VERSION "created by canmatrix"

NS_ :

BS_:

BU_:

BO_ 2633936894 GFC: 8 Vector__XXX
 SG_ TotalFuelUsed : 32|32@1+ (0.5,0) [0|2105540607.5] "kg" Vector__XXX
 SG_ TripFuel : 0|32@1+ (0.5,0) [0|2105540607.5] "kg" Vector__XXX

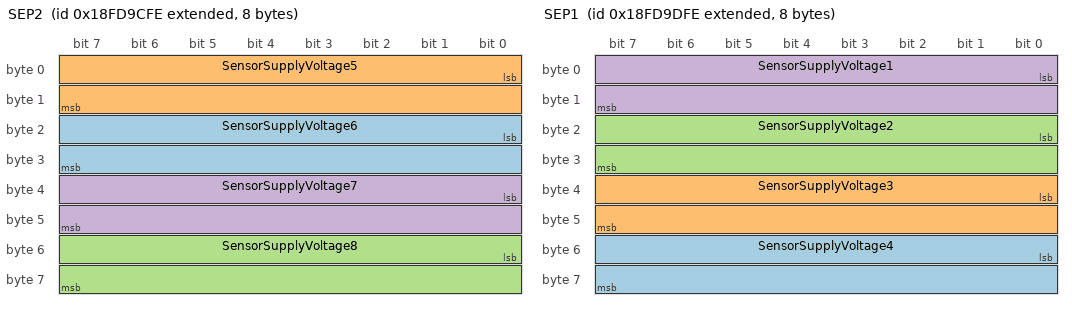
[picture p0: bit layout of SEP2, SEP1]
BO_ 2566757630 SEP2: 8 Vector__XXX
 SG_ SensorSupplyVoltage6 : 16|16@1+ (0.05,0) [0|3212.75] "V" Vector__XXX
 SG_ SensorSupplyVoltage5 : 0|16@1+ (0.05,0) [0|3212.75] "V" Vector__XXX
 SG_ SensorSupplyVoltage8 : 48|16@1+ (0.05,0) [0|3212.75] "V" Vector__XXX
 SG_ SensorSupplyVoltage7 : 32|16@1+ (0.05,0) [0|3212.75] "V" Vector__XXX

BO_ 2566757886 SEP1: 8 Vector__XXX
 SG_ SensorSupplyVoltage4 : 48|16@1+ (0.05,0) [0|3212.75] "V" Vector__XXX
 SG_ SensorSupplyVoltage3 : 32|16@1+ (0.05,0) [0|3212.75] "V" Vector__XXX
 SG_ SensorSupplyVoltage2 : 16|16@1+ (0.05,0) [0|3212.75] "V" Vector__XXX
 SG_ SensorSupplyVoltage1 : 0|16@1+ (0.05,0) [0|3212.75] "V" Vector__XXX

BO_ 2566759678 PTODE: 8 Vector__XXX
 SG_ EnggmntSttusTransInputShaftPTO1 : 38|2@1+ (1,0) [0|3] "" Vector__XXX
 SG_ EnggmntSttusTransInputShaftPTO2 : 36|2@1+ (1,0) [0|3] "" Vector__XXX
 SG_ EnggmntSttusTransOutputShaftPTO : 34|2@1+ (1,0) [0|3] "" Vector__XXX
 SG_ EnggmntSttsTrnsfrCsOtptShaftPTO : 32|2@1+ (1,0) [0|3] "" Vector__XXX
 SG_ EnggmntCnsntTransInputShaftPTO1 : 22|2@1+ (1,0) [0|3] "" Vector__XXX
 SG_ EnggmntCnsntTransInputShaftPTO2 : 20|2@1+ (1,0) [0|3] "" Vector__XXX
 SG_ EnggmntCnsntTransOutputShaftPTO : 18|2@1+ (1,0) [0|3] "" Vector__XXX
 SG_ EnggmntCnsntTrnsfrCsOtptShftPTO : 16|2@1+ (1,0) [0|3] "" Vector__XXX
 SG_ EnableSwitchTransInputShaftPTO1 : 6|2@1+ (1,0) [0|3] "" Vector__XXX
 SG_ EnableSwitchTransInputShaftPTO2 : 4|2@1+ (1,0) [0|3] "" Vector__XXX
 SG_ EnableSwitchTransOutputShaftPTO : 2|2@1+ (1,0) [0|3] "" Vector__XXX
 SG_ EnblSwtchTrnsfrCsOutputShaftPTO : 0|2@1+ (1,0) [0|3] "" Vector__XXX
 SG_ EnggmntSttsPTOEngAccssoryDrive2 : 44|2@1+ (1,0) [0|3] "" Vector__XXX
 SG_ EnggmntSttsPTOEngAccssoryDrive1 : 42|2@1+ (1,0) [0|3] "" Vector__XXX
 SG_ EnggmntCnsntPTOEngAccssryDrive2 : 28|2@1+ (1,0) [0|3] "" Vector__XXX
 SG_ EnggmntCnsntPTOEngAccssryDrive1 : 26|2@1+ (1,0) [0|3] "" Vector__XXX
 SG_ EngagementStatusPTOEngFlywheel : 40|2@1+ (1,0) [0|3] "" Vector__XXX
 SG_ EngagementConsentPTOEngFlywheel : 24|2@1+ (1,0) [0|3] "" Vector__XXX
 SG_ EnblSwitchPTOEngAccessoryDrive2 : 12|2@1+ (1,0) [0|3] "" Vector__XXX
 SG_ EnblSwitchPTOEngAccessoryDrive1 : 10|2@1+ (1,0) [0|3] "" Vector__XXX
 SG_ EnableSwitchPTOEngFlywheel : 8|2@1+ (1,0) [0|3] "" Vector__XXX
 SG_ AtLeastOnePTOEngaged : 48|2@1+ (1,0) [0|3] "" Vector__XXX

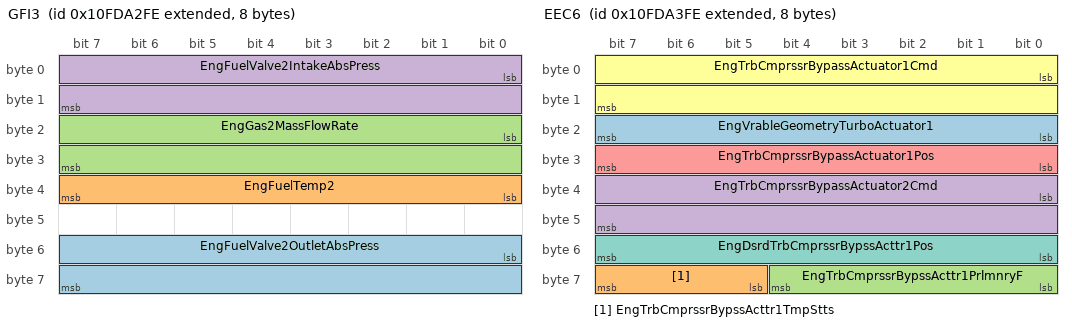
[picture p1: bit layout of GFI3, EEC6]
BO_ 2432541438 GFI3: 8 Vector__XXX
 SG_ EngFuelValve2OutletAbsPress : 48|16@1+ (0.1,0) [0|6425.5] "kPa" Vector__XXX
 SG_ EngFuelTemp2 : 32|8@1+ (1,-40) [-40|210] "deg C" Vector__XXX
 SG_ EngGas2MassFlowRate : 16|16@1+ (0.05,0) [0|3212.75] "kg/h" Vector__XXX
 SG_ EngFuelValve2IntakeAbsPress : 0|16@1+ (0.1,0) [0|6425.5] "kPa" Vector__XXX

BO_ 2432541694 EEC6: 8 Vector__XXX
 SG_ EngVrableGeometryTurboActuator1 : 16|8@1+ (0.4,0) [0|100] "%" Vector__XXX
 SG_ EngTrbCmprssrBypssActtr1TmpStts : 61|3@1+ (1,0) [0|7] "" Vector__XXX
 SG_ EngTrbCmprssrBypssActtr1PrlmnryF : 56|5@1+ (1,0) [0|31] "" Vector__XXX
 SG_ EngTrbCmprssrBypassActuator2Cmd : 32|16@1+ (0.0025,0) [0|160.6375] "%" Vector__XXX
 SG_ EngTrbCmprssrBypassActuator1Pos : 24|8@1+ (0.4,0) [0|100] "%" Vector__XXX
 SG_ EngTrbCmprssrBypassActuator1Cmd : 0|16@1+ (0.0025,0) [0|160.6375] "%" Vector__XXX
 SG_ EngDsrdTrbCmprssrBypssActtr1Pos : 48|8@1+ (0.4,0) [0|100] "%" Vector__XXX

BO_ 2566759934 DC2: 8 Vector__XXX
 SG_ EnableStatusOfDoor10 : 58|2@1+ (1,0) [0|3] "" Vector__XXX
 SG_ OpenStatusOfDoor10 : 56|2@1+ (1,0) [0|3] "" Vector__XXX
 SG_ LockStatusOfDoor10 : 54|2@1+ (1,0) [0|3] "" Vector__XXX
 SG_ EnableStatusOfDoor9 : 52|2@1+ (1,0) [0|3] "" Vector__XXX
 SG_ OpenStatusOfDoor9 : 50|2@1+ (1,0) [0|3] "" Vector__XXX
 SG_ LockStatusOfDoor9 : 48|2@1+ (1,0) [0|3] "" Vector__XXX
 SG_ EnableStatusOfDoor8 : 46|2@1+ (1,0) [0|3] "" Vector__XXX
 SG_ OpenStatusOfDoor8 : 44|2@1+ (1,0) [0|3] "" Vector__XXX
 SG_ LockStatusOfDoor8 : 42|2@1+ (1,0) [0|3] "" Vector__XXX
 SG_ EnableStatusOfDoor7 : 40|2@1+ (1,0) [0|3] "" Vector__XXX
 SG_ OpenStatusOfDoor7 : 38|2@1+ (1,0) [0|3] "" Vector__XXX
 SG_ LockStatusOfDoor7 : 36|2@1+ (1,0) [0|3] "" Vector__XXX
 SG_ EnableStatusOfDoor6 : 34|2@1+ (1,0) [0|3] "" Vector__XXX
 SG_ OpenStatusOfDoor6 : 32|2@1+ (1,0) [0|3] "" Vector__XXX
 SG_ LockStatusOfDoor6 : 30|2@1+ (1,0) [0|3] "" Vector__XXX
 SG_ EnableStatusOfDoor5 : 28|2@1+ (1,0) [0|3] "" Vector__XXX
 SG_ OpenStatusOfDoor5 : 26|2@1+ (1,0) [0|3] "" Vector__XXX
 SG_ LockStatusOfDoor5 : 24|2@1+ (1,0) [0|3] "" Vector__XXX
 SG_ EnableStatusOfDoor4 : 22|2@1+ (1,0) [0|3] "" Vector__XXX
 SG_ OpenStatusOfDoor4 : 20|2@1+ (1,0) [0|3] "" Vector__XXX
 SG_ LockStatusOfDoor4 : 18|2@1+ (1,0) [0|3] "" Vector__XXX
 SG_ EnableStatusOfDoor3 : 16|2@1+ (1,0) [0|3] "" Vector__XXX
 SG_ OpenStatusOfDoor3 : 14|2@1+ (1,0) [0|3] "" Vector__XXX
 SG_ LockStatusOfDoor3 : 12|2@1+ (1,0) [0|3] "" Vector__XXX
 SG_ EnableStatusOfDoor2 : 10|2@1+ (1,0) [0|3] "" Vector__XXX
 SG_ OpenStatusOfDoor2 : 8|2@1+ (1,0) [0|3] "" Vector__XXX
 SG_ LockStatusOfDoor2 : 6|2@1+ (1,0) [0|3] "" Vector__XXX
 SG_ EnableStatusOfDoor1 : 4|2@1+ (1,0) [0|3] "" Vector__XXX
 SG_ OpenStatusOfDoor1 : 2|2@1+ (1,0) [0|3] "" Vector__XXX
 SG_ LockStatusOfDoor1 : 0|2@1+ (1,0) [0|3] "" Vector__XXX

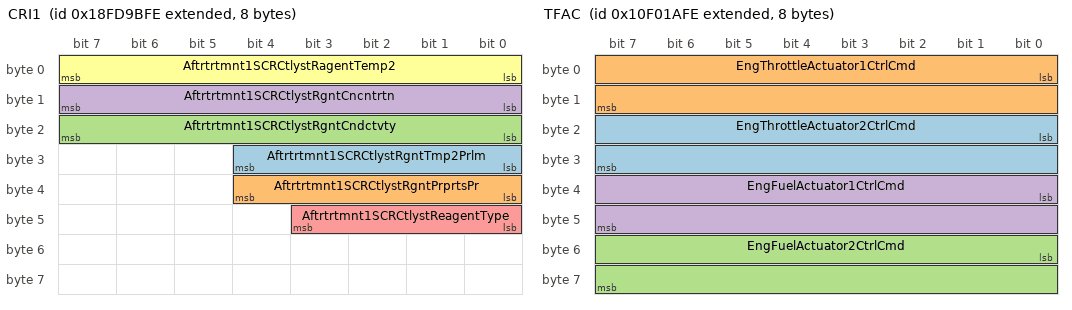
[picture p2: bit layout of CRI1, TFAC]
BO_ 2566757374 CRI1: 8 Vector__XXX
 SG_ Aftrtrtmnt1SCRCtlystRgntTmp2Prlm : 24|5@1+ (1,0) [0|31] "" Vector__XXX
 SG_ Aftrtrtmnt1SCRCtlystRgntPrprtsPr : 32|5@1+ (1,0) [0|31] "" Vector__XXX
 SG_ Aftrtrtmnt1SCRCtlystRgntCndctvty : 16|8@1+ (5,0) [0|1250] "microSiemens/mm" Vector__XXX
 SG_ Aftrtrtmnt1SCRCtlystRgntCncntrtn : 8|8@1+ (0.25,0) [0|62.5] "%" Vector__XXX
 SG_ Aftrtrtmnt1SCRCtlystReagentType : 40|4@1+ (1,0) [0|15] "" Vector__XXX
 SG_ Aftrtrtmnt1SCRCtlystRagentTemp2 : 0|8@1+ (1,-40) [-40|210] "deg C" Vector__XXX

BO_ 2431654654 TFAC: 8 Vector__XXX
 SG_ EngThrottleActuator2CtrlCmd : 16|16@1+ (0.0025,0) [0|160.6375] "%" Vector__XXX
 SG_ EngThrottleActuator1CtrlCmd : 0|16@1+ (0.0025,0) [0|160.6375] "%" Vector__XXX
 SG_ EngFuelActuator2CtrlCmd : 48|16@1+ (0.0025,0) [0|160.6375] "%" Vector__XXX
 SG_ EngFuelActuator1CtrlCmd : 32|16@1+ (0.0025,0) [0|160.6375] "%" Vector__XXX

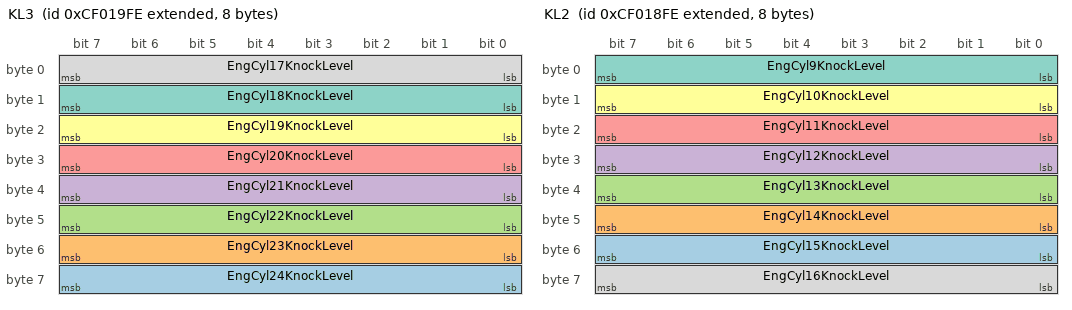
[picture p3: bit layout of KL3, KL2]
BO_ 2364545534 KL3: 8 Vector__XXX
 SG_ EngCyl24KnockLevel : 56|8@1+ (1,0) [0|250] "%" Vector__XXX
 SG_ EngCyl23KnockLevel : 48|8@1+ (1,0) [0|250] "%" Vector__XXX
 SG_ EngCyl22KnockLevel : 40|8@1+ (1,0) [0|250] "%" Vector__XXX
 SG_ EngCyl21KnockLevel : 32|8@1+ (1,0) [0|250] "%" Vector__XXX
 SG_ EngCyl20KnockLevel : 24|8@1+ (1,0) [0|250] "%" Vector__XXX
 SG_ EngCyl19KnockLevel : 16|8@1+ (1,0) [0|250] "%" Vector__XXX
 SG_ EngCyl18KnockLevel : 8|8@1+ (1,0) [0|250] "%" Vector__XXX
 SG_ EngCyl17KnockLevel : 0|8@1+ (1,0) [0|250] "%" Vector__XXX

BO_ 2364545278 KL2: 8 Vector__XXX
 SG_ EngCyl15KnockLevel : 48|8@1+ (1,0) [0|250] "%" Vector__XXX
 SG_ EngCyl14KnockLevel : 40|8@1+ (1,0) [0|250] "%" Vector__XXX
 SG_ EngCyl13KnockLevel : 32|8@1+ (1,0) [0|250] "%" Vector__XXX
 SG_ EngCyl12KnockLevel : 24|8@1+ (1,0) [0|250] "%" Vector__XXX
 SG_ EngCyl11KnockLevel : 16|8@1+ (1,0) [0|250] "%" Vector__XXX
 SG_ EngCyl10KnockLevel : 8|8@1+ (1,0) [0|250] "%" Vector__XXX
 SG_ EngCyl9KnockLevel : 0|8@1+ (1,0) [0|250] "%" Vector__XXX
 SG_ EngCyl16KnockLevel : 56|8@1+ (1,0) [0|250] "%" Vector__XXX

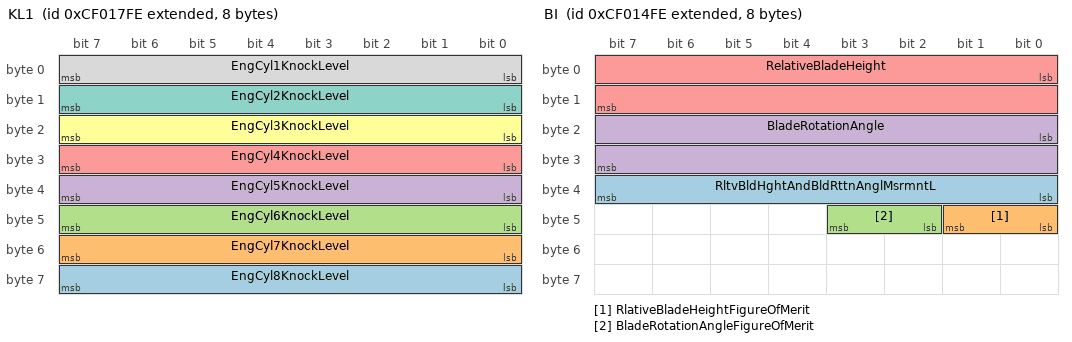
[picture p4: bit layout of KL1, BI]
BO_ 2364545022 KL1: 8 Vector__XXX
 SG_ EngCyl8KnockLevel : 56|8@1+ (1,0) [0|250] "%" Vector__XXX
 SG_ EngCyl7KnockLevel : 48|8@1+ (1,0) [0|250] "%" Vector__XXX
 SG_ EngCyl6KnockLevel : 40|8@1+ (1,0) [0|250] "%" Vector__XXX
 SG_ EngCyl5KnockLevel : 32|8@1+ (1,0) [0|250] "%" Vector__XXX
 SG_ EngCyl4KnockLevel : 24|8@1+ (1,0) [0|250] "%" Vector__XXX
 SG_ EngCyl3KnockLevel : 16|8@1+ (1,0) [0|250] "%" Vector__XXX
 SG_ EngCyl2KnockLevel : 8|8@1+ (1,0) [0|250] "%" Vector__XXX
 SG_ EngCyl1KnockLevel : 0|8@1+ (1,0) [0|250] "%" Vector__XXX

BO_ 2364544766 CCS: 8 Vector__XXX
 SG_ EngCyl9CombustionStatus : 16|2@1+ (1,0) [0|3] "" Vector__XXX
 SG_ EngCyl8CombustionStatus : 14|2@1+ (1,0) [0|3] "" Vector__XXX
 SG_ EngCyl7CombustionStatus : 12|2@1+ (1,0) [0|3] "" Vector__XXX
 SG_ EngCyl6CombustionStatus : 10|2@1+ (1,0) [0|3] "" Vector__XXX
 SG_ EngCyl5CombustionStatus : 8|2@1+ (1,0) [0|3] "" Vector__XXX
 SG_ EngCyl4CombustionStatus : 6|2@1+ (1,0) [0|3] "" Vector__XXX
 SG_ EngCyl3CombustionStatus : 4|2@1+ (1,0) [0|3] "" Vector__XXX
 SG_ EngCyl2CombustionStatus : 2|2@1+ (1,0) [0|3] "" Vector__XXX
 SG_ EngCyl24CombustionStatus : 46|2@1+ (1,0) [0|3] "" Vector__XXX
 SG_ EngCyl23CombustionStatus : 44|2@1+ (1,0) [0|3] "" Vector__XXX
 SG_ EngCyl22CombustionStatus : 42|2@1+ (1,0) [0|3] "" Vector__XXX
 SG_ EngCyl21CombustionStatus : 40|2@1+ (1,0) [0|3] "" Vector__XXX
 SG_ EngCyl20CombustionStatus : 38|2@1+ (1,0) [0|3] "" Vector__XXX
 SG_ EngCyl1CombustionStatus : 0|2@1+ (1,0) [0|3] "" Vector__XXX
 SG_ EngCyl19CombustionStatus : 36|2@1+ (1,0) [0|3] "" Vector__XXX
 SG_ EngCyl18CombustionStatus : 34|2@1+ (1,0) [0|3] "" Vector__XXX
 SG_ EngCyl17CombustionStatus : 32|2@1+ (1,0) [0|3] "" Vector__XXX
 SG_ EngCyl16CombustionStatus : 30|2@1+ (1,0) [0|3] "" Vector__XXX
 SG_ EngCyl15CombustionStatus : 28|2@1+ (1,0) [0|3] "" Vector__XXX
 SG_ EngCyl14CombustionStatus : 26|2@1+ (1,0) [0|3] "" Vector__XXX
 SG_ EngCyl13CombustionStatus : 24|2@1+ (1,0) [0|3] "" Vector__XXX
 SG_ EngCyl12CombustionStatus : 22|2@1+ (1,0) [0|3] "" Vector__XXX
 SG_ EngCyl11CombustionStatus : 20|2@1+ (1,0) [0|3] "" Vector__XXX
 SG_ EngCyl10CombustionStatus : 18|2@1+ (1,0) [0|3] "" Vector__XXX

BO_ 2364544254 BI: 8 Vector__XXX
 SG_ RltvBldHghtAndBldRttnAnglMsrmntL : 32|8@1+ (0.5,0) [0|125] "ms" Vector__XXX
 SG_ RlativeBladeHeightFigureOfMerit : 40|2@1+ (1,0) [0|3] "" Vector__XXX
 SG_ BladeRotationAngleFigureOfMerit : 42|2@1+ (1,0) [0|3] "" Vector__XXX
 SG_ BladeRotationAngle : 16|16@1+ (0.0078125,-200) [-200|301.99] "deg" Vector__XXX
 SG_ RelativeBladeHeight : 0|16@1+ (0.1,-3200) [-3200|3225.5] "mm" Vector__XXX

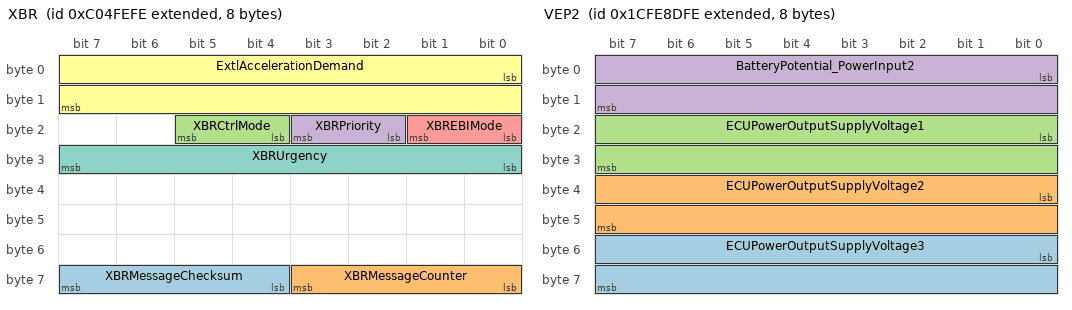
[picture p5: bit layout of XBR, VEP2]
BO_ 2349137662 XBR: 8 Vector__XXX
 SG_ XBRMessageChecksum : 60|4@1+ (1,0) [0|15] "" Vector__XXX
 SG_ XBRMessageCounter : 56|4@1+ (1,0) [0|15] "" Vector__XXX
 SG_ XBRCtrlMode : 20|2@1+ (1,0) [0|3] "" Vector__XXX
 SG_ XBRPriority : 18|2@1+ (1,0) [0|3] "" Vector__XXX
 SG_ XBREBIMode : 16|2@1+ (1,0) [0|3] "" Vector__XXX
 SG_ ExtlAccelerationDemand : 0|16@1+ (0.00048828125,-15.687) [-15.687|15.687] "m/s/s" Vector__XXX
 SG_ XBRUrgency : 24|8@1+ (0.4,0) [0|100] "%" Vector__XXX

BO_ 2566848510 WFI: 8 Vector__XXX
 SG_ WaterInFuelIndicator : 0|2@1+ (1,0) [0|3] "" Vector__XXX

BO_ 2566843134 VW: 8 Vector__XXX
 SG_ AxleLocation M : 0|8@1+ (1,0) [0|255] "" Vector__XXX
 SG_ CargoWeight_30 m48 : 40|16@1+ (2,0) [0|128510] "kg" Vector__XXX
 SG_ CargoWeight_20 m32 : 40|16@1+ (2,0) [0|128510] "kg" Vector__XXX
 SG_ CargoWeight_10 m16 : 40|16@1+ (2,0) [0|128510] "kg" Vector__XXX
 SG_ CargoWeight_00 m0 : 40|16@1+ (2,0) [0|128510] "kg" Vector__XXX
 SG_ TrailerWeight_30 m48 : 24|16@1+ (2,0) [0|128510] "kg" Vector__XXX
 SG_ TrailerWeight_20 m32 : 24|16@1+ (2,0) [0|128510] "kg" Vector__XXX
 SG_ TrailerWeight_10 m16 : 24|16@1+ (2,0) [0|128510] "kg" Vector__XXX
 SG_ TrailerWeight_00 m0 : 24|16@1+ (2,0) [0|128510] "kg" Vector__XXX
 SG_ AxleWeight_30 m48 : 8|16@1+ (0.5,0) [0|32127.5] "kg" Vector__XXX
 SG_ AxleWeight_20 m32 : 8|16@1+ (0.5,0) [0|32127.5] "kg" Vector__XXX
 SG_ AxleWeight_10 m16 : 8|16@1+ (0.5,0) [0|32127.5] "kg" Vector__XXX
 SG_ AxleWeight_00 m0 : 8|16@1+ (0.5,0) [0|32127.5] "kg" Vector__XXX

BO_ 2566804222 VEP3: 8 Vector__XXX
 SG_ NetBatteryCurrentHiRes : 16|16@1+ (0.05,-1600) [-1600|1612.75] "A" Vector__XXX
 SG_ AltCurrentHiRes : 0|16@1+ (0.05,-1600) [-1600|1676.75] "A" Vector__XXX

BO_ 2633928190 VEP2: 8 Vector__XXX
 SG_ ECUPowerOutputSupplyVoltage3 : 48|16@1+ (0.05,0) [0|3212.75] "V" Vector__XXX
 SG_ ECUPowerOutputSupplyVoltage2 : 32|16@1+ (0.05,0) [0|3212.75] "V" Vector__XXX
 SG_ ECUPowerOutputSupplyVoltage1 : 16|16@1+ (0.05,0) [0|3212.75] "V" Vector__XXX
 SG_ BatteryPotential_PowerInput2 : 0|16@1+ (0.05,0) [0|3212.75] "V" Vector__XXX

BO_ 2566845438 VP: 8 Vector__XXX
 SG_ Longitude : 32|32@1+ (10,-210) [-210|211.1008122] "deg" Vector__XXX
 SG_ Latitude : 0|32@1+ (10,-210) [-210|211.1008122] "deg" Vector__XXX

BO_ 2566843646 VI: 8 Vector__XXX
 SG_ VehicleIdentificationNumber : 0|8@1+ (1,0) [0|255] "" Vector__XXX

BO_ 2566842366 VH: 8 Vector__XXX
 SG_ TotalPowerTakeoffHours : 32|32@1+ (0.05,0) [0|210554060.75] "hr" Vector__XXX
 SG_ TotalVehicleHours : 0|32@1+ (0.05,0) [0|210554060.75] "hr" Vector__XXX

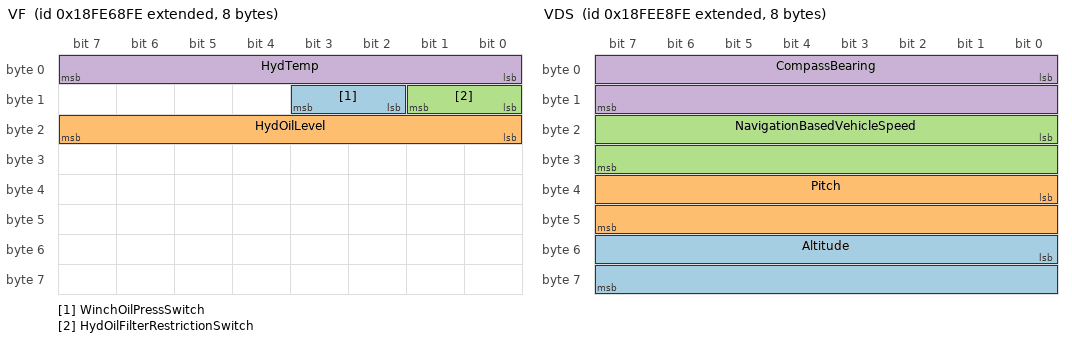
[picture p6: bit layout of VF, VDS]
BO_ 2566809854 VF: 8 Vector__XXX
 SG_ WinchOilPressSwitch : 10|2@1+ (1,0) [0|3] "" Vector__XXX
 SG_ HydOilLevel : 16|8@1+ (0.4,0) [0|100] "%" Vector__XXX
 SG_ HydOilFilterRestrictionSwitch : 8|2@1+ (1,0) [0|3] "" Vector__XXX
 SG_ HydTemp : 0|8@1+ (1,-40) [-40|210] "deg C" Vector__XXX

BO_ 2566842622 VDS: 8 Vector__XXX
 SG_ Altitude : 48|16@1+ (0.125,-2500) [-2500|5531.875] "m" Vector__XXX
 SG_ Pitch : 32|16@1+ (0.0078125,-200) [-200|301.99] "deg" Vector__XXX
 SG_ NavigationBasedVehicleSpeed : 16|16@1+ (0.00390625,0) [0|250.996] "km/h" Vector__XXX
 SG_ CompassBearing : 0|16@1+ (0.0078125,0) [0|501.99] "deg" Vector__XXX

BO_ 2566832638 VDHR: 8 Vector__XXX
 SG_ HighResolutionTripDistance : 32|32@1+ (5,0) [0|21055406] "km" Vector__XXX
 SG_ HghRslutionTotalVehicleDistance : 0|32@1+ (5,0) [0|21055406] "km" Vector__XXX

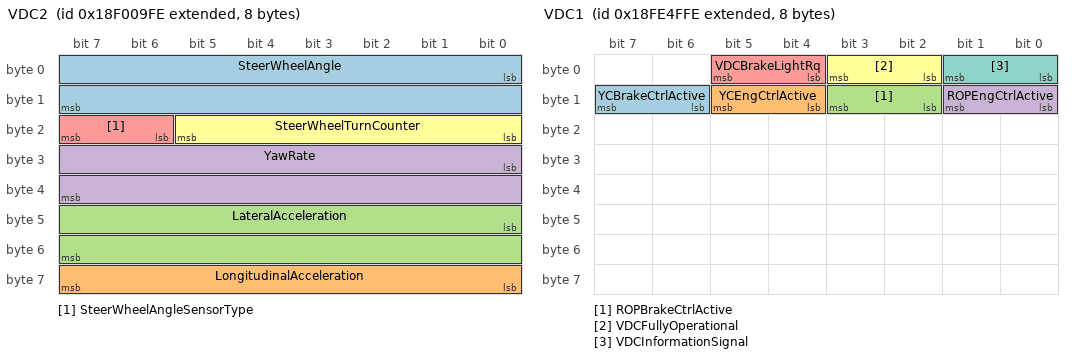
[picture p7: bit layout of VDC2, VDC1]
BO_ 2565868030 VDC2: 8 Vector__XXX
 SG_ SteerWheelAngle : 0|16@1+ (0.0009765625,-31.374) [-31.374|31.374] "rad" Vector__XXX
 SG_ LongitudinalAcceleration : 56|8@1+ (0.1,-12.5) [-12.5|12.5] "m/s/s" Vector__XXX
 SG_ LateralAcceleration : 40|16@1+ (0.00048828125,-15.687) [-15.687|15.687] "m/s/s" Vector__XXX
 SG_ YawRate : 24|16@1+ (0.0001220703125,-3.92) [-3.92|3.92] "rad/s" Vector__XXX
 SG_ SteerWheelAngleSensorType : 22|2@1+ (1,0) [0|3] "" Vector__XXX
 SG_ SteerWheelTurnCounter : 16|6@1+ (1,-32) [-32|29] "turns" Vector__XXX

BO_ 2566803454 VDC1: 8 Vector__XXX
 SG_ YCBrakeCtrlActive : 14|2@1+ (1,0) [0|3] "" Vector__XXX
 SG_ YCEngCtrlActive : 12|2@1+ (1,0) [0|3] "" Vector__XXX
 SG_ ROPBrakeCtrlActive : 10|2@1+ (1,0) [0|3] "" Vector__XXX
 SG_ ROPEngCtrlActive : 8|2@1+ (1,0) [0|3] "" Vector__XXX
 SG_ VDCBrakeLightRq : 4|2@1+ (1,0) [0|3] "" Vector__XXX
 SG_ VDCFullyOperational : 2|2@1+ (1,0) [0|3] "" Vector__XXX
 SG_ VDCInformationSignal : 0|2@1+ (1,0) [0|3] "" Vector__XXX

BO_ 2566840574 VD: 8 Vector__XXX
 SG_ TotalVehicleDistance : 32|32@1+ (0.125,0) [0|526385151.9] "km" Vector__XXX
 SG_ TripDistance : 0|32@1+ (0.125,0) [0|526385151.9] "km" Vector__XXX

BO_ 2633938686 TVI: 8 Vector__XXX
 SG_ TripCruiseDistance : 16|32@1+ (0.125,0) [0|526385151.9] "km" Vector__XXX
 SG_ TripMaxVehicleSpeed : 0|16@1+ (0.00390625,0) [0|250.996] "km/h" Vector__XXX

BO_ 2633937150 TTI2: 20 Vector__XXX
 SG_ TripAirCompressorOnTime : 128|32@1+ (0.05,0) [0|210554060.75] "hr" Vector__XXX
 SG_ TripIdleTime : 96|32@1+ (0.05,0) [0|210554060.75] "hr" Vector__XXX
 SG_ TripEngRunningTime : 64|32@1+ (0.05,0) [0|210554060.75] "hr" Vector__XXX
 SG_ TripCruiseTime : 0|32@1+ (0.05,0) [0|210554060.75] "hr" Vector__XXX
 SG_ TripPTOGovernorTime : 32|32@1+ (0.05,0) [0|210554060.75] "hr" Vector__XXX

BO_ 2633938174 TTI1: 16 Vector__XXX
 SG_ TripTimeInDerateByEng : 96|32@1+ (0.05,0) [0|210554060.75] "hr" Vector__XXX
 SG_ TripTimeInGearDown : 64|32@1+ (0.05,0) [0|210554060.75] "hr" Vector__XXX
 SG_ TripTimeInTopGear : 32|32@1+ (0.05,0) [0|210554060.75] "hr" Vector__XXX
 SG_ TripTimeInVSL : 0|32@1+ (0.05,0) [0|210554060.75] "hr" Vector__XXX

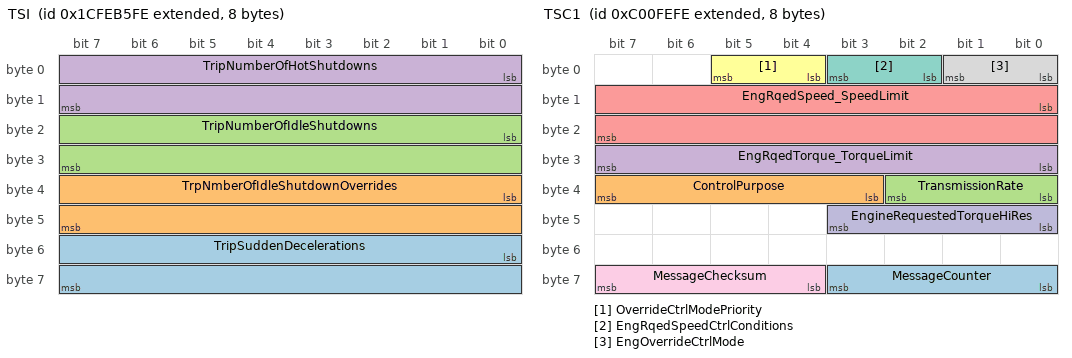
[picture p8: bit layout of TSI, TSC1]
BO_ 2633938430 TSI: 8 Vector__XXX
 SG_ TripSuddenDecelerations : 48|16@1+ (1,0) [0|64255] "counts" Vector__XXX
 SG_ TrpNmberOfIdleShutdownOverrides : 32|16@1+ (1,0) [0|64255] "counts" Vector__XXX
 SG_ TripNumberOfIdleShutdowns : 16|16@1+ (1,0) [0|64255] "counts" Vector__XXX
 SG_ TripNumberOfHotShutdowns : 0|16@1+ (1,0) [0|64255] "counts" Vector__XXX

BO_ 2348875518 TSC1: 8 Vector__XXX
 SG_ MessageCounter : 56|4@1+ (1,0) [0|15] "" Vector__XXX
 SG_ ControlPurpose : 35|5@1+ (1,0) [0|31] "" Vector__XXX
 SG_ TransmissionRate : 32|3@1+ (1,0) [0|7] "" Vector__XXX
 SG_ EngRqedTorque_TorqueLimit : 24|8@1+ (1,-125) [-125|125] "%" Vector__XXX
 SG_ EngRqedSpeed_SpeedLimit : 8|16@1+ (0.125,0) [0|8031.875] "rpm" Vector__XXX
 SG_ OverrideCtrlModePriority : 4|2@1+ (1,0) [0|3] "" Vector__XXX
 SG_ EngRqedSpeedCtrlConditions : 2|2@1+ (1,0) [0|3] "" Vector__XXX
 SG_ EngOverrideCtrlMode : 0|2@1+ (1,0) [0|3] "" Vector__XXX
 SG_ MessageChecksum : 60|4@1+ (1,0) [0|15] "" Vector__XXX
 SG_ EngineRequestedTorqueHiRes : 40|4@1+ (0.125,0) [0|0.875] "%" Vector__XXX

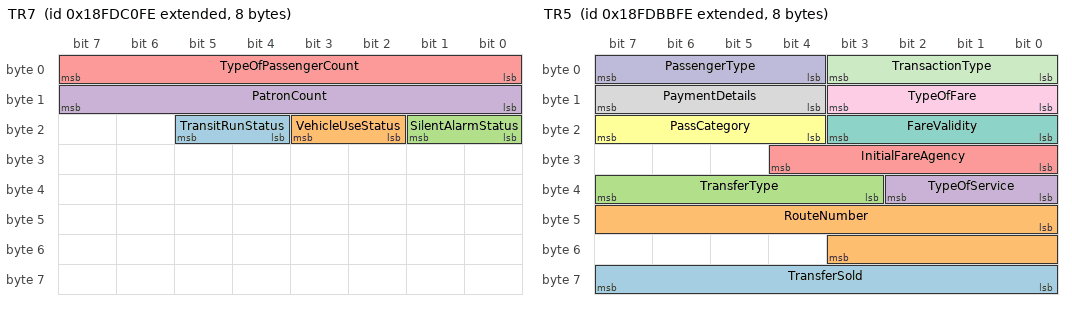
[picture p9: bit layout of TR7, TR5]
BO_ 2566766846 TR7: 8 Vector__XXX
 SG_ TransitRunStatus : 20|2@1+ (1,0) [0|3] "" Vector__XXX
 SG_ VehicleUseStatus : 18|2@1+ (1,0) [0|3] "" Vector__XXX
 SG_ SilentAlarmStatus : 16|2@1+ (1,0) [0|3] "" Vector__XXX
 SG_ PatronCount : 8|8@1+ (1,0) [0|250] "" Vector__XXX
 SG_ TypeOfPassengerCount : 0|8@1+ (1,0) [0|255] "" Vector__XXX

BO_ 2566765310 TR6: 8 Vector__XXX
 SG_ FareboxAlarmIdentifier : 8|7@1+ (1,0) [0|127] "" Vector__XXX
 SG_ FareboxEmergencyStatus : 0|2@1+ (1,0) [0|3] "" Vector__XXX

BO_ 2566765566 TR5: 8 Vector__XXX
 SG_ TransferSold : 56|8@1+ (1,0) [0|255] "" Vector__XXX
 SG_ RouteNumber : 40|12@1+ (1,0) [0|4095] "" Vector__XXX
 SG_ TransferType : 35|5@1+ (1,0) [0|31] "" Vector__XXX
 SG_ TypeOfService : 32|3@1+ (1,0) [0|7] "" Vector__XXX
 SG_ InitialFareAgency : 24|5@1+ (1,0) [0|31] "" Vector__XXX
 SG_ PassCategory : 20|4@1+ (1,0) [0|15] "" Vector__XXX
 SG_ FareValidity : 16|4@1+ (1,0) [0|15] "" Vector__XXX
 SG_ PaymentDetails : 12|4@1+ (1,0) [0|15] "" Vector__XXX
 SG_ TypeOfFare : 8|4@1+ (1,0) [0|15] "" Vector__XXX
 SG_ PassengerType : 4|4@1+ (1,0) [0|15] "" Vector__XXX
 SG_ TransactionType : 0|4@1+ (1,0) [0|15] "" Vector__XXX

BO_ 2566765822 TR4: 15 Vector__XXX
 SG_ DriversFareboxSecurityCode : 104|16@1+ (1,0) [0|65535] "counts" Vector__XXX
 SG_ AssignedBlock : 88|16@1+ (1,0) [0|65535] "counts" Vector__XXX
 SG_ AssignedRun : 72|16@1+ (1,0) [0|65535] "counts" Vector__XXX
 SG_ AssignedRoute : 56|16@1+ (1,0) [0|65535] "counts" Vector__XXX
 SG_ PatternNumber : 40|16@1+ (1,0) [0|65535] "counts" Vector__XXX
 SG_ TripNumber : 24|16@1+ (1,0) [0|65535] "counts" Vector__XXX
 SG_ FarePresets : 16|8@1+ (1,0) [0|255] "" Vector__XXX
 SG_ TripDirection : 8|4@1+ (1,0) [0|15] "" Vector__XXX
 SG_ TripStatus : 2|3@1+ (1,0) [0|7] "" Vector__XXX
 SG_ FareboxServiceStatus : 0|2@1+ (1,0) [0|3] "" Vector__XXX

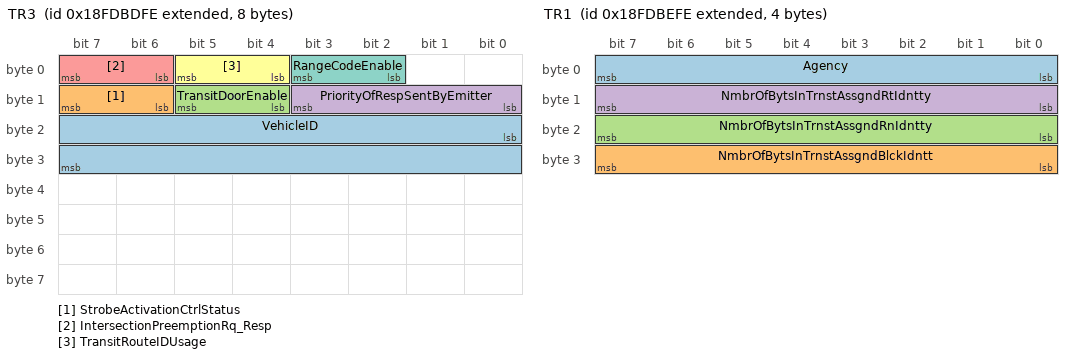
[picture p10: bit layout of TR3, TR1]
BO_ 2566766078 TR3: 8 Vector__XXX
 SG_ VehicleID : 16|16@1+ (1,0) [0|65535] "counts" Vector__XXX
 SG_ StrobeActivationCtrlStatus : 14|2@1+ (1,0) [0|3] "" Vector__XXX
 SG_ TransitDoorEnable : 12|2@1+ (1,0) [0|3] "" Vector__XXX
 SG_ PriorityOfRespSentByEmitter : 8|4@1+ (1,0) [0|15] "" Vector__XXX
 SG_ IntersectionPreemptionRq_Resp : 6|2@1+ (1,0) [0|3] "" Vector__XXX
 SG_ TransitRouteIDUsage : 4|2@1+ (1,0) [0|3] "" Vector__XXX
 SG_ RangeCodeEnable : 2|2@1+ (1,0) [0|3] "" Vector__XXX

BO_ 2566766590 TR2: 8 Vector__XXX
 SG_ NmbrOfBytsInMlpstIdentification : 0|8@1+ (1,0) [0|250] "" Vector__XXX

BO_ 2566766334 TR1: 4 Vector__XXX
 SG_ Agency : 0|8@1+ (1,0) [0|255] "" Vector__XXX
 SG_ NmbrOfBytsInTrnstAssgndBlckIdntt : 24|8@1+ (1,0) [0|250] "" Vector__XXX
 SG_ NmbrOfBytsInTrnstAssgndRnIdntty : 16|8@1+ (1,0) [0|250] "" Vector__XXX
 SG_ NmbrOfBytsInTrnstAssgndRtIdntty : 8|8@1+ (1,0) [0|250] "" Vector__XXX

BO_ 2561605374 TPRS: 8 Vector__XXX
 SG_ ReferenceTirePressSetting_33 m51 : 8|8@1+ (8,0) [0|2000] "kPa" Vector__XXX
 SG_ ReferenceTirePressSetting_32 m50 : 8|8@1+ (8,0) [0|2000] "kPa" Vector__XXX
 SG_ ReferenceTirePressSetting_31 m49 : 8|8@1+ (8,0) [0|2000] "kPa" Vector__XXX
 SG_ ReferenceTirePressSetting_30 m48 : 8|8@1+ (8,0) [0|2000] "kPa" Vector__XXX
 SG_ ReferenceTirePressSetting_23 m35 : 8|8@1+ (8,0) [0|2000] "kPa" Vector__XXX
 SG_ ReferenceTirePressSetting_22 m34 : 8|8@1+ (8,0) [0|2000] "kPa" Vector__XXX
 SG_ ReferenceTirePressSetting_21 m33 : 8|8@1+ (8,0) [0|2000] "kPa" Vector__XXX
 SG_ ReferenceTirePressSetting_20 m32 : 8|8@1+ (8,0) [0|2000] "kPa" Vector__XXX
 SG_ ReferenceTirePressSetting_13 m19 : 8|8@1+ (8,0) [0|2000] "kPa" Vector__XXX
 SG_ ReferenceTirePressSetting_12 m18 : 8|8@1+ (8,0) [0|2000] "kPa" Vector__XXX
 SG_ ReferenceTirePressSetting_11 m17 : 8|8@1+ (8,0) [0|2000] "kPa" Vector__XXX
 SG_ ReferenceTirePressSetting_10 m16 : 8|8@1+ (8,0) [0|2000] "kPa" Vector__XXX
 SG_ ReferenceTirePressSetting_01 m1 : 8|8@1+ (8,0) [0|2000] "kPa" Vector__XXX
 SG_ ReferenceTirePressSetting_00 m0 : 8|8@1+ (8,0) [0|2000] "kPa" Vector__XXX
 SG_ TireLocation M : 0|8@1+ (1,0) [0|255] "" Vector__XXX

BO_ 2566765054 TPRI: 8 Vector__XXX
 SG_ ReferenceTirePress_33 m51 : 8|8@1+ (8,0) [0|2000] "kPa" Vector__XXX
 SG_ ReferenceTirePress_32 m50 : 8|8@1+ (8,0) [0|2000] "kPa" Vector__XXX
 SG_ ReferenceTirePress_31 m49 : 8|8@1+ (8,0) [0|2000] "kPa" Vector__XXX
 SG_ ReferenceTirePress_30 m48 : 8|8@1+ (8,0) [0|2000] "kPa" Vector__XXX
 SG_ ReferenceTirePress_23 m35 : 8|8@1+ (8,0) [0|2000] "kPa" Vector__XXX
 SG_ ReferenceTirePress_22 m34 : 8|8@1+ (8,0) [0|2000] "kPa" Vector__XXX
 SG_ ReferenceTirePress_21 m33 : 8|8@1+ (8,0) [0|2000] "kPa" Vector__XXX
 SG_ ReferenceTirePress_20 m32 : 8|8@1+ (8,0) [0|2000] "kPa" Vector__XXX
 SG_ ReferenceTirePress_13 m19 : 8|8@1+ (8,0) [0|2000] "kPa" Vector__XXX
 SG_ ReferenceTirePress_12 m18 : 8|8@1+ (8,0) [0|2000] "kPa" Vector__XXX
 SG_ ReferenceTirePress_11 m17 : 8|8@1+ (8,0) [0|2000] "kPa" Vector__XXX
 SG_ ReferenceTirePress_10 m16 : 8|8@1+ (8,0) [0|2000] "kPa" Vector__XXX
 SG_ ReferenceTirePress_01 m1 : 8|8@1+ (8,0) [0|2000] "kPa" Vector__XXX
 SG_ ReferenceTirePress_00 m0 : 8|8@1+ (8,0) [0|2000] "kPa" Vector__XXX
 SG_ TireLocation M : 0|8@1+ (1,0) [0|255] "" Vector__XXX

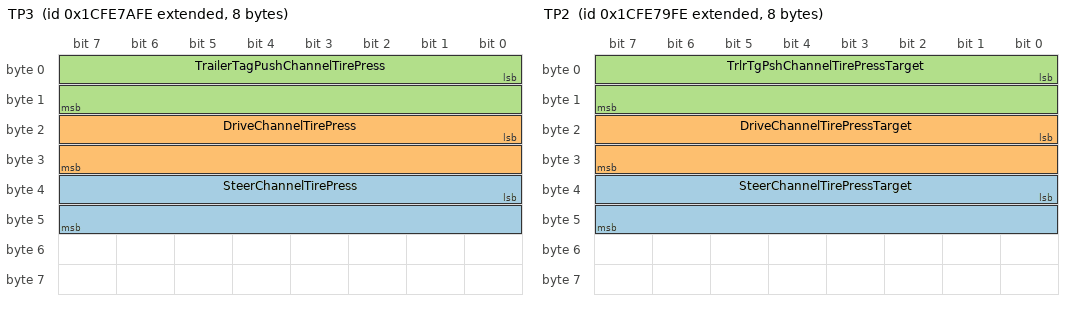
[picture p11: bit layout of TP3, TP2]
BO_ 2633923326 TP3: 8 Vector__XXX
 SG_ SteerChannelTirePress : 32|16@1+ (0.5,0) [0|32127.5] "kPa" Vector__XXX
 SG_ DriveChannelTirePress : 16|16@1+ (0.5,0) [0|32127.5] "kPa" Vector__XXX
 SG_ TrailerTagPushChannelTirePress : 0|16@1+ (0.5,0) [0|32127.5] "kPa" Vector__XXX

BO_ 2633923070 TP2: 8 Vector__XXX
 SG_ SteerChannelTirePressTarget : 32|16@1+ (0.5,0) [0|32127.5] "kPa" Vector__XXX
 SG_ DriveChannelTirePressTarget : 16|16@1+ (0.5,0) [0|32127.5] "kPa" Vector__XXX
 SG_ TrlrTgPshChannelTirePressTarget : 0|16@1+ (0.5,0) [0|32127.5] "kPa" Vector__XXX

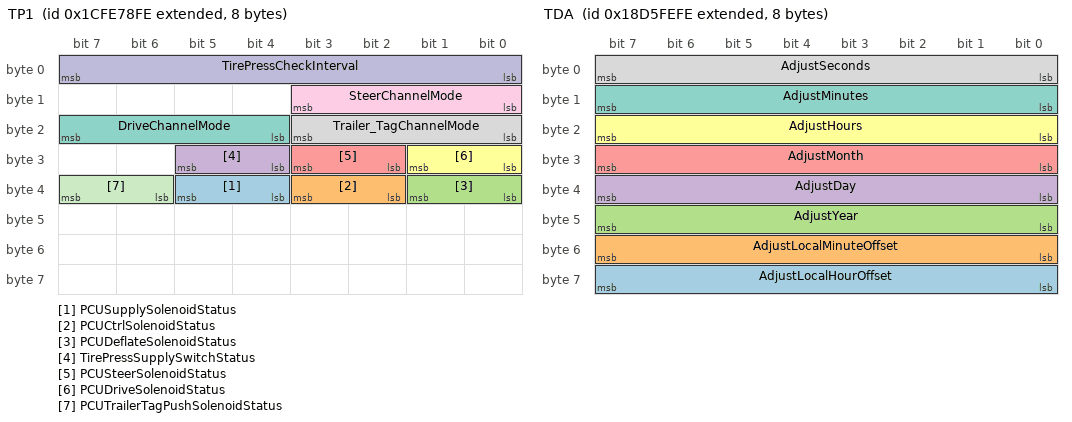
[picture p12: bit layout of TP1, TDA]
BO_ 2633922814 TP1: 8 Vector__XXX
 SG_ PCUSupplySolenoidStatus : 36|2@1+ (1,0) [0|3] "" Vector__XXX
 SG_ PCUCtrlSolenoidStatus : 34|2@1+ (1,0) [0|3] "" Vector__XXX
 SG_ PCUDeflateSolenoidStatus : 32|2@1+ (1,0) [0|3] "" Vector__XXX
 SG_ TirePressSupplySwitchStatus : 28|2@1+ (1,0) [0|3] "" Vector__XXX
 SG_ PCUSteerSolenoidStatus : 26|2@1+ (1,0) [0|3] "" Vector__XXX
 SG_ PCUDriveSolenoidStatus : 24|2@1+ (1,0) [0|3] "" Vector__XXX
 SG_ DriveChannelMode : 20|4@1+ (1,0) [0|15] "" Vector__XXX
 SG_ Trailer_TagChannelMode : 16|4@1+ (1,0) [0|15] "" Vector__XXX
 SG_ SteerChannelMode : 8|4@1+ (1,0) [0|15] "" Vector__XXX
 SG_ TirePressCheckInterval : 0|8@1+ (1,0) [0|250] "mins" Vector__XXX
 SG_ PCUTrailerTagPushSolenoidStatus : 38|2@1+ (1,0) [0|3] "" Vector__XXX

BO_ 2566845694 TIRE: 8 Vector__XXX
 SG_ TirePressThresholdDetection_13 m19 : 61|3@1+ (1,0) [0|7] "" Vector__XXX
 SG_ TirePressThresholdDetection_12 m18 : 61|3@1+ (1,0) [0|7] "" Vector__XXX
 SG_ TirePressThresholdDetection_11 m17 : 61|3@1+ (1,0) [0|7] "" Vector__XXX
 SG_ TirePressThresholdDetection_10 m16 : 61|3@1+ (1,0) [0|7] "" Vector__XXX
 SG_ TirePressThresholdDetection_01 m1 : 61|3@1+ (1,0) [0|7] "" Vector__XXX
 SG_ TirePress_33 m51 : 8|8@1+ (4,0) [0|1000] "kPa" Vector__XXX
 SG_ TirePress_32 m50 : 8|8@1+ (4,0) [0|1000] "kPa" Vector__XXX
 SG_ TirePress_31 m49 : 8|8@1+ (4,0) [0|1000] "kPa" Vector__XXX
 SG_ TirePress_30 m48 : 8|8@1+ (4,0) [0|1000] "kPa" Vector__XXX
 SG_ TirePress_23 m35 : 8|8@1+ (4,0) [0|1000] "kPa" Vector__XXX
 SG_ TirePress_22 m34 : 8|8@1+ (4,0) [0|1000] "kPa" Vector__XXX
 SG_ TirePress_21 m33 : 8|8@1+ (4,0) [0|1000] "kPa" Vector__XXX
 SG_ TirePress_20 m32 : 8|8@1+ (4,0) [0|1000] "kPa" Vector__XXX
 SG_ TirePress_13 m19 : 8|8@1+ (4,0) [0|1000] "kPa" Vector__XXX
 SG_ TirePress_12 m18 : 8|8@1+ (4,0) [0|1000] "kPa" Vector__XXX
 SG_ TirePress_11 m17 : 8|8@1+ (4,0) [0|1000] "kPa" Vector__XXX
 SG_ TirePress_10 m16 : 8|8@1+ (4,0) [0|1000] "kPa" Vector__XXX
 SG_ TireAirLeakageRate_33 m51 : 40|16@1+ (0.1,0) [0|6425.5] "Pa/s" Vector__XXX
 SG_ TireAirLeakageRate_32 m50 : 40|16@1+ (0.1,0) [0|6425.5] "Pa/s" Vector__XXX
 SG_ TireAirLeakageRate_31 m49 : 40|16@1+ (0.1,0) [0|6425.5] "Pa/s" Vector__XXX
 SG_ TireAirLeakageRate_30 m48 : 40|16@1+ (0.1,0) [0|6425.5] "Pa/s" Vector__XXX
 SG_ TireAirLeakageRate_23 m35 : 40|16@1+ (0.1,0) [0|6425.5] "Pa/s" Vector__XXX
 SG_ TireAirLeakageRate_22 m34 : 40|16@1+ (0.1,0) [0|6425.5] "Pa/s" Vector__XXX
 SG_ TireAirLeakageRate_21 m33 : 40|16@1+ (0.1,0) [0|6425.5] "Pa/s" Vector__XXX
 SG_ TireAirLeakageRate_20 m32 : 40|16@1+ (0.1,0) [0|6425.5] "Pa/s" Vector__XXX
 SG_ TireAirLeakageRate_13 m19 : 40|16@1+ (0.1,0) [0|6425.5] "Pa/s" Vector__XXX
 SG_ TireAirLeakageRate_12 m18 : 40|16@1+ (0.1,0) [0|6425.5] "Pa/s" Vector__XXX
 SG_ TireAirLeakageRate_11 m17 : 40|16@1+ (0.1,0) [0|6425.5] "Pa/s" Vector__XXX
 SG_ TireAirLeakageRate_10 m16 : 40|16@1+ (0.1,0) [0|6425.5] "Pa/s" Vector__XXX
 SG_ TireAirLeakageRate_01 m1 : 40|16@1+ (0.1,0) [0|6425.5] "Pa/s" Vector__XXX
 SG_ TireAirLeakageRate_00 m0 : 40|16@1+ (0.1,0) [0|6425.5] "Pa/s" Vector__XXX
 SG_ CTIWheelSensorStatus_33 m51 : 32|2@1+ (1,0) [0|3] "" Vector__XXX
 SG_ CTIWheelSensorStatus_32 m50 : 32|2@1+ (1,0) [0|3] "" Vector__XXX
 SG_ CTIWheelSensorStatus_31 m49 : 32|2@1+ (1,0) [0|3] "" Vector__XXX
 SG_ CTIWheelSensorStatus_30 m48 : 32|2@1+ (1,0) [0|3] "" Vector__XXX
 SG_ CTIWheelSensorStatus_23 m35 : 32|2@1+ (1,0) [0|3] "" Vector__XXX
 SG_ CTIWheelSensorStatus_22 m34 : 32|2@1+ (1,0) [0|3] "" Vector__XXX
 SG_ CTIWheelSensorStatus_21 m33 : 32|2@1+ (1,0) [0|3] "" Vector__XXX
 SG_ CTIWheelSensorStatus_20 m32 : 32|2@1+ (1,0) [0|3] "" Vector__XXX
 SG_ CTIWheelSensorStatus_13 m19 : 32|2@1+ (1,0) [0|3] "" Vector__XXX
 SG_ CTIWheelSensorStatus_12 m18 : 32|2@1+ (1,0) [0|3] "" Vector__XXX
 SG_ CTIWheelSensorStatus_11 m17 : 32|2@1+ (1,0) [0|3] "" Vector__XXX
 SG_ CTIWheelSensorStatus_10 m16 : 32|2@1+ (1,0) [0|3] "" Vector__XXX
 SG_ CTIWheelSensorStatus_01 m1 : 32|2@1+ (1,0) [0|3] "" Vector__XXX
 SG_ CTIWheelEndElectricalFault_33 m51 : 36|2@1+ (1,0) [0|3] "" Vector__XXX
 SG_ CTIWheelEndElectricalFault_32 m50 : 36|2@1+ (1,0) [0|3] "" Vector__XXX
 SG_ CTIWheelEndElectricalFault_31 m49 : 36|2@1+ (1,0) [0|3] "" Vector__XXX
 SG_ CTIWheelEndElectricalFault_30 m48 : 36|2@1+ (1,0) [0|3] "" Vector__XXX
 SG_ CTIWheelEndElectricalFault_23 m35 : 36|2@1+ (1,0) [0|3] "" Vector__XXX
 SG_ CTIWheelEndElectricalFault_22 m34 : 36|2@1+ (1,0) [0|3] "" Vector__XXX
 SG_ CTIWheelEndElectricalFault_21 m33 : 36|2@1+ (1,0) [0|3] "" Vector__XXX
 SG_ CTIWheelEndElectricalFault_20 m32 : 36|2@1+ (1,0) [0|3] "" Vector__XXX
 SG_ CTIWheelEndElectricalFault_13 m19 : 36|2@1+ (1,0) [0|3] "" Vector__XXX
 SG_ CTIWheelEndElectricalFault_12 m18 : 36|2@1+ (1,0) [0|3] "" Vector__XXX
 SG_ CTIWheelEndElectricalFault_11 m17 : 36|2@1+ (1,0) [0|3] "" Vector__XXX
 SG_ CTIWheelEndElectricalFault_10 m16 : 36|2@1+ (1,0) [0|3] "" Vector__XXX
 SG_ CTIWheelEndElectricalFault_01 m1 : 36|2@1+ (1,0) [0|3] "" Vector__XXX
 SG_ CTITireStatus_33 m51 : 34|2@1+ (1,0) [0|3] "" Vector__XXX
 SG_ CTITireStatus_32 m50 : 34|2@1+ (1,0) [0|3] "" Vector__XXX
 SG_ CTITireStatus_31 m49 : 34|2@1+ (1,0) [0|3] "" Vector__XXX
 SG_ CTITireStatus_30 m48 : 34|2@1+ (1,0) [0|3] "" Vector__XXX
 SG_ CTITireStatus_23 m35 : 34|2@1+ (1,0) [0|3] "" Vector__XXX
 SG_ CTITireStatus_22 m34 : 34|2@1+ (1,0) [0|3] "" Vector__XXX
 SG_ CTITireStatus_21 m33 : 34|2@1+ (1,0) [0|3] "" Vector__XXX
 SG_ CTITireStatus_20 m32 : 34|2@1+ (1,0) [0|3] "" Vector__XXX
 SG_ CTITireStatus_13 m19 : 34|2@1+ (1,0) [0|3] "" Vector__XXX
 SG_ CTITireStatus_12 m18 : 34|2@1+ (1,0) [0|3] "" Vector__XXX
 SG_ CTITireStatus_11 m17 : 34|2@1+ (1,0) [0|3] "" Vector__XXX
 SG_ CTITireStatus_10 m16 : 34|2@1+ (1,0) [0|3] "" Vector__XXX
 SG_ CTITireStatus_01 m1 : 34|2@1+ (1,0) [0|3] "" Vector__XXX
 SG_ TireTemp_11 m17 : 16|16@1+ (0.03125,-273) [-273|1735] "deg C" Vector__XXX
 SG_ TireTemp_33 m51 : 16|16@1+ (0.03125,-273) [-273|1735] "deg C" Vector__XXX
 SG_ TireTemp_32 m50 : 16|16@1+ (0.03125,-273) [-273|1735] "deg C" Vector__XXX
 SG_ TireTemp_31 m49 : 16|16@1+ (0.03125,-273) [-273|1735] "deg C" Vector__XXX
 SG_ TireTemp_30 m48 : 16|16@1+ (0.03125,-273) [-273|1735] "deg C" Vector__XXX
 SG_ TireTemp_23 m35 : 16|16@1+ (0.03125,-273) [-273|1735] "deg C" Vector__XXX
 SG_ TireTemp_22 m34 : 16|16@1+ (0.03125,-273) [-273|1735] "deg C" Vector__XXX
 SG_ TireTemp_21 m33 : 16|16@1+ (0.03125,-273) [-273|1735] "deg C" Vector__XXX
 SG_ TireTemp_20 m32 : 16|16@1+ (0.03125,-273) [-273|1735] "deg C" Vector__XXX
 SG_ TireTemp_13 m19 : 16|16@1+ (0.03125,-273) [-273|1735] "deg C" Vector__XXX
 SG_ TireTemp_12 m18 : 16|16@1+ (0.03125,-273) [-273|1735] "deg C" Vector__XXX
 SG_ TireTemp_10 m16 : 16|16@1+ (0.03125,-273) [-273|1735] "deg C" Vector__XXX
 SG_ TireTemp_01 m1 : 16|16@1+ (0.03125,-273) [-273|1735] "deg C" Vector__XXX
 SG_ TireTemp_00 m0 : 16|16@1+ (0.03125,-273) [-273|1735] "deg C" Vector__XXX
 SG_ TirePressThresholdDetection_33 m51 : 61|3@1+ (1,0) [0|7] "" Vector__XXX
 SG_ TirePressThresholdDetection_32 m50 : 61|3@1+ (1,0) [0|7] "" Vector__XXX
 SG_ TirePressThresholdDetection_31 m49 : 61|3@1+ (1,0) [0|7] "" Vector__XXX
 SG_ TirePressThresholdDetection_30 m48 : 61|3@1+ (1,0) [0|7] "" Vector__XXX
 SG_ TirePressThresholdDetection_23 m35 : 61|3@1+ (1,0) [0|7] "" Vector__XXX
 SG_ TirePressThresholdDetection_22 m34 : 61|3@1+ (1,0) [0|7] "" Vector__XXX
 SG_ TirePressThresholdDetection_21 m33 : 61|3@1+ (1,0) [0|7] "" Vector__XXX
 SG_ TirePressThresholdDetection_20 m32 : 61|3@1+ (1,0) [0|7] "" Vector__XXX
 SG_ TirePressThresholdDetection_00 m0 : 61|3@1+ (1,0) [0|7] "" Vector__XXX
 SG_ TirePress_01 m1 : 8|8@1+ (4,0) [0|1000] "kPa" Vector__XXX
 SG_ TirePress_00 m0 : 8|8@1+ (4,0) [0|1000] "kPa" Vector__XXX
 SG_ CTIWheelSensorStatus_00 m0 : 32|2@1+ (1,0) [0|3] "" Vector__XXX
 SG_ CTIWheelEndElectricalFault_00 m0 : 36|2@1+ (1,0) [0|3] "" Vector__XXX
 SG_ CTITireStatus_00 m0 : 34|2@1+ (1,0) [0|3] "" Vector__XXX
 SG_ TireLocation M : 0|8@1+ (1,0) [0|255] "" Vector__XXX

BO_ 2633939966 TFI: 16 Vector__XXX
 SG_ TripFanOnTimeDueToAManualSwitch : 64|32@1+ (0.05,0) [0|210554060.75] "hr" Vector__XXX
 SG_ TripFanOnTime : 0|32@1+ (0.05,0) [0|210554060.75] "hr" Vector__XXX
 SG_ TripFanOnTimeDueToA_CSystem : 96|32@1+ (0.05,0) [0|210554060.75] "hr" Vector__XXX
 SG_ TripFanOnTimeDueToEngSystem : 32|32@1+ (0.05,0) [0|210554060.75] "hr" Vector__XXX

BO_ 2633939710 TDI: 12 Vector__XXX
 SG_ TripDistanceInTopGear : 64|32@1+ (0.125,0) [0|526385151.9] "km" Vector__XXX
 SG_ TripGearDownDistance : 32|32@1+ (0.125,0) [0|526385151.9] "km" Vector__XXX
 SG_ TripDistanceOnVSL : 0|32@1+ (0.125,0) [0|526385151.9] "km" Vector__XXX

BO_ 2564161278 TDA: 8 Vector__XXX
 SG_ AdjustLocalHourOffset : 56|8@1+ (1,-125) [-125|125] "hr" Vector__XXX
 SG_ AdjustLocalMinuteOffset : 48|8@1+ (1,-125) [-125|125] "mins" Vector__XXX
 SG_ AdjustYear : 40|8@1+ (1,1985) [1985|2235] "years" Vector__XXX
 SG_ AdjustDay : 32|8@1+ (0.25,0) [0|62.5] "days" Vector__XXX
 SG_ AdjustMonth : 24|8@1+ (1,0) [0|250] "months" Vector__XXX
 SG_ AdjustHours : 16|8@1+ (1,0) [0|250] "hr" Vector__XXX
 SG_ AdjustMinutes : 8|8@1+ (1,0) [0|250] "mins" Vector__XXX
 SG_ AdjustSeconds : 0|8@1+ (0.25,0) [0|62.5] "s" Vector__XXX

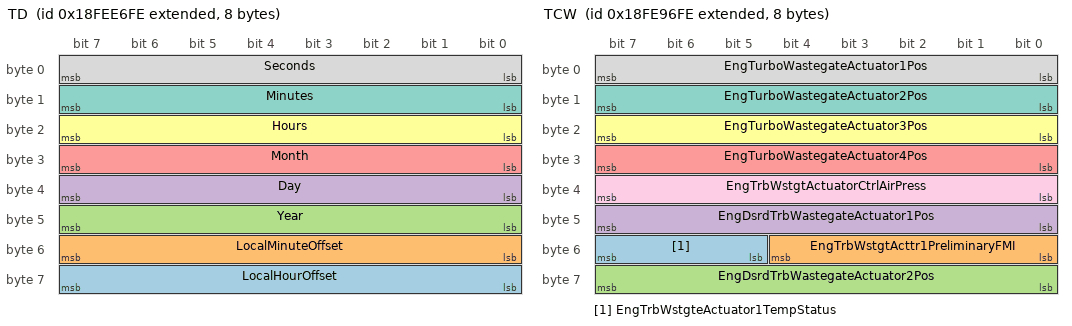
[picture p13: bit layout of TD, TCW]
BO_ 2566842110 TD: 8 Vector__XXX
 SG_ LocalHourOffset : 56|8@1+ (1,-125) [-125|125] "hr" Vector__XXX
 SG_ LocalMinuteOffset : 48|8@1+ (1,-125) [-125|125] "mins" Vector__XXX
 SG_ Year : 40|8@1+ (1,1985) [1985|2235] "years" Vector__XXX
 SG_ Day : 32|8@1+ (0.25,0) [0|62.5] "days" Vector__XXX
 SG_ Month : 24|8@1+ (1,0) [0|250] "months" Vector__XXX
 SG_ Hours : 16|8@1+ (1,0) [0|250] "hr" Vector__XXX
 SG_ Minutes : 8|8@1+ (1,0) [0|250] "mins" Vector__XXX
 SG_ Seconds : 0|8@1+ (0.25,0) [0|62.5] "s" Vector__XXX

BO_ 2566821630 TCW: 8 Vector__XXX
 SG_ EngTrbWstgteActuator1TempStatus : 53|3@1+ (1,0) [0|7] "" Vector__XXX
 SG_ EngTrbWstgtActtr1PreliminaryFMI : 48|5@1+ (1,0) [0|31] "" Vector__XXX
 SG_ EngDsrdTrbWastegateActuator2Pos : 56|8@1+ (0.4,0) [0|100] "%" Vector__XXX
 SG_ EngDsrdTrbWastegateActuator1Pos : 40|8@1+ (0.4,0) [0|100] "%" Vector__XXX
 SG_ EngTurboWastegateActuator4Pos : 24|8@1+ (0.4,0) [0|100] "%" Vector__XXX
 SG_ EngTurboWastegateActuator3Pos : 16|8@1+ (0.4,0) [0|100] "%" Vector__XXX
 SG_ EngTurboWastegateActuator2Pos : 8|8@1+ (0.4,0) [0|100] "%" Vector__XXX
 SG_ EngTurboWastegateActuator1Pos : 0|8@1+ (0.4,0) [0|100] "%" Vector__XXX
 SG_ EngTrbWstgtActuatorCtrlAirPress : 32|8@1+ (4,0) [0|1000] "kPa" Vector__XXX

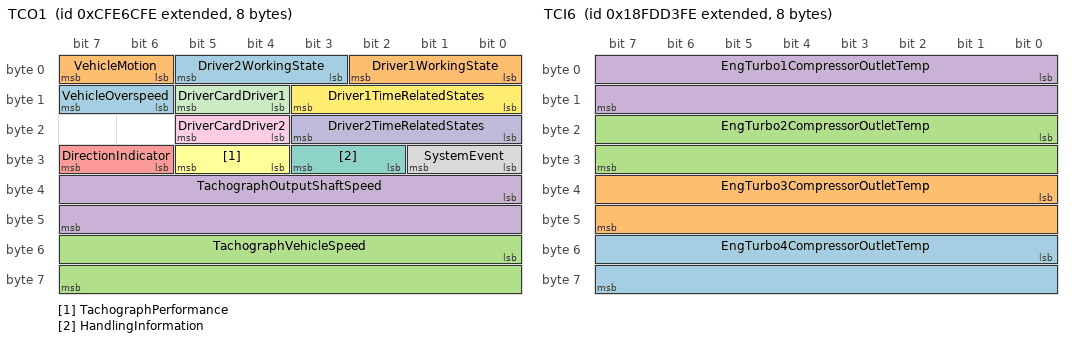
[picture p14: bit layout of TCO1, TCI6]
BO_ 2365484286 TCO1: 8 Vector__XXX
 SG_ VehicleOverspeed : 14|2@1+ (1,0) [0|3] "" Vector__XXX
 SG_ VehicleMotion : 6|2@1+ (1,0) [0|3] "" Vector__XXX
 SG_ TachographVehicleSpeed : 48|16@1+ (0.00390625,0) [0|250.996] "km/h" Vector__XXX
 SG_ TachographOutputShaftSpeed : 32|16@1+ (0.125,0) [0|8031.875] "rpm" Vector__XXX
 SG_ DirectionIndicator : 30|2@1+ (1,0) [0|3] "" Vector__XXX
 SG_ TachographPerformance : 28|2@1+ (1,0) [0|3] "" Vector__XXX
 SG_ HandlingInformation : 26|2@1+ (1,0) [0|3] "" Vector__XXX
 SG_ SystemEvent : 24|2@1+ (1,0) [0|3] "" Vector__XXX
 SG_ DriverCardDriver2 : 20|2@1+ (1,0) [0|3] "" Vector__XXX
 SG_ Driver2TimeRelatedStates : 16|4@1+ (1,0) [0|15] "" Vector__XXX
 SG_ DriverCardDriver1 : 12|2@1+ (1,0) [0|3] "" Vector__XXX
 SG_ Driver1TimeRelatedStates : 8|4@1+ (1,0) [0|15] "" Vector__XXX
 SG_ Driver2WorkingState : 3|3@1+ (1,0) [0|7] "" Vector__XXX
 SG_ Driver1WorkingState : 0|3@1+ (1,0) [0|7] "" Vector__XXX

BO_ 2566771710 TCI6: 8 Vector__XXX
 SG_ EngTurbo4CompressorOutletTemp : 48|16@1+ (0.03125,-273) [-273|1734.96875] "deg C" Vector__XXX
 SG_ EngTurbo3CompressorOutletTemp : 32|16@1+ (0.03125,-273) [-273|1734.96875] "deg C" Vector__XXX
 SG_ EngTurbo2CompressorOutletTemp : 16|16@1+ (0.03125,-273) [-273|1734.96875] "deg C" Vector__XXX
 SG_ EngTurbo1CompressorOutletTemp : 0|16@1+ (0.03125,-273) [-273|1734.96875] "deg C" Vector__XXX

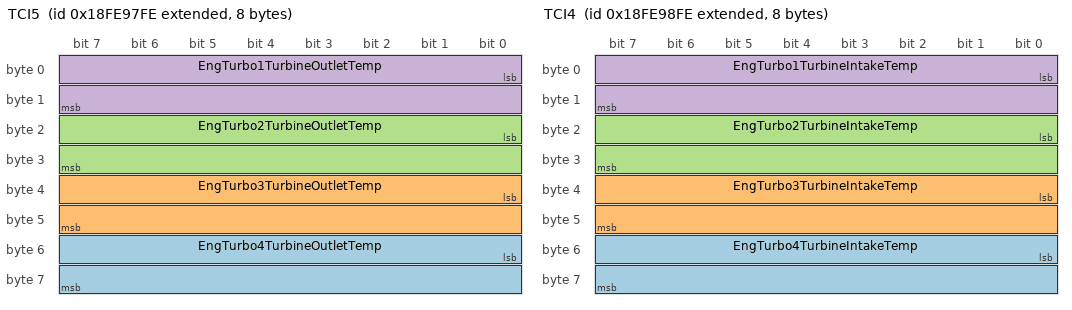
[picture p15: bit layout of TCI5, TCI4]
BO_ 2566821886 TCI5: 8 Vector__XXX
 SG_ EngTurbo4TurbineOutletTemp : 48|16@1+ (0.03125,-273) [-273|1734.96875] "deg C" Vector__XXX
 SG_ EngTurbo3TurbineOutletTemp : 32|16@1+ (0.03125,-273) [-273|1734.96875] "deg C" Vector__XXX
 SG_ EngTurbo2TurbineOutletTemp : 16|16@1+ (0.03125,-273) [-273|1734.96875] "deg C" Vector__XXX
 SG_ EngTurbo1TurbineOutletTemp : 0|16@1+ (0.03125,-273) [-273|1734.96875] "deg C" Vector__XXX

BO_ 2566822142 TCI4: 8 Vector__XXX
 SG_ EngTurbo4TurbineIntakeTemp : 48|16@1+ (0.03125,-273) [-273|1734.96875] "deg C" Vector__XXX
 SG_ EngTurbo3TurbineIntakeTemp : 32|16@1+ (0.03125,-273) [-273|1734.96875] "deg C" Vector__XXX
 SG_ EngTurbo2TurbineIntakeTemp : 16|16@1+ (0.03125,-273) [-273|1734.96875] "deg C" Vector__XXX
 SG_ EngTurbo1TurbineIntakeTemp : 0|16@1+ (0.03125,-273) [-273|1734.96875] "deg C" Vector__XXX

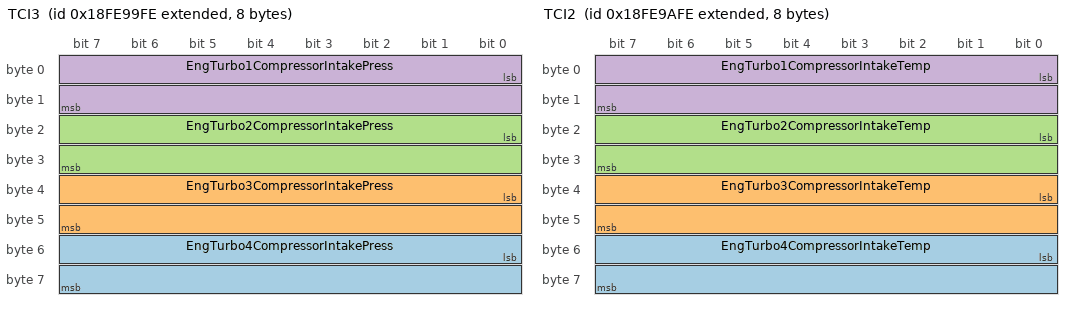
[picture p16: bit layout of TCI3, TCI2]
BO_ 2566822398 TCI3: 8 Vector__XXX
 SG_ EngTurbo4CompressorIntakePress : 48|16@1+ (0.0078125,-250) [-250|251.99] "kPa" Vector__XXX
 SG_ EngTurbo3CompressorIntakePress : 32|16@1+ (0.0078125,-250) [-250|251.99] "kPa" Vector__XXX
 SG_ EngTurbo2CompressorIntakePress : 16|16@1+ (0.0078125,-250) [-250|251.99] "kPa" Vector__XXX
 SG_ EngTurbo1CompressorIntakePress : 0|16@1+ (0.0078125,-250) [-250|251.99] "kPa" Vector__XXX

BO_ 2566822654 TCI2: 8 Vector__XXX
 SG_ EngTurbo4CompressorIntakeTemp : 48|16@1+ (0.03125,-273) [-273|1734.96875] "deg C" Vector__XXX
 SG_ EngTurbo3CompressorIntakeTemp : 32|16@1+ (0.03125,-273) [-273|1734.96875] "deg C" Vector__XXX
 SG_ EngTurbo2CompressorIntakeTemp : 16|16@1+ (0.03125,-273) [-273|1734.96875] "deg C" Vector__XXX
 SG_ EngTurbo1CompressorIntakeTemp : 0|16@1+ (0.03125,-273) [-273|1734.96875] "deg C" Vector__XXX

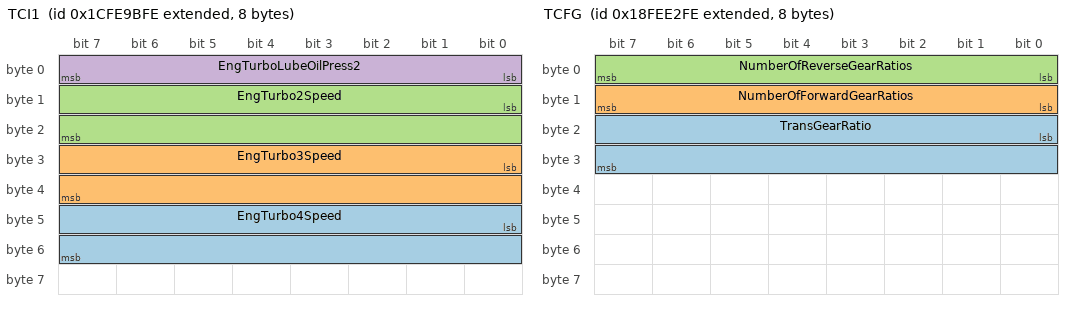
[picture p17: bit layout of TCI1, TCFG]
BO_ 2633931774 TCI1: 8 Vector__XXX
 SG_ EngTurbo4Speed : 40|16@1+ (4,0) [0|257020] "rpm" Vector__XXX
 SG_ EngTurbo3Speed : 24|16@1+ (4,0) [0|257020] "rpm" Vector__XXX
 SG_ EngTurbo2Speed : 8|16@1+ (4,0) [0|257020] "rpm" Vector__XXX
 SG_ EngTurboLubeOilPress2 : 0|8@1+ (4,0) [0|1000] "kPa" Vector__XXX

BO_ 2566802430 TCFG2: 8 Vector__XXX
 SG_ TransTorqueLimit : 0|16@1+ (1,0) [0|64255] "Nm" Vector__XXX

BO_ 2566841086 TCFG: 8 Vector__XXX
 SG_ TransGearRatio : 16|16@1+ (0.001,0) [0|64.255] "" Vector__XXX
 SG_ NumberOfForwardGearRatios : 8|8@1+ (1,0) [0|250] "" Vector__XXX
 SG_ NumberOfReverseGearRatios : 0|8@1+ (1,0) [0|250] "" Vector__XXX

CM_ BO_ 2633936894  "Fuel Consumption (Gaseous)";
CM_ BO_ 2566757630  "Sensor Electrical Power #2";
CM_ BO_ 2566757886  "Sensor Electrical Power #1";
CM_ BO_ 2566759678  "PTO Drive Engagement";
CM_ BO_ 2432541438  "Fuel Information 3 (Gaseous)";
CM_ BO_ 2432541694  "Electronic Engine Controller 6";
CM_ BO_ 2566759934  "Door Control 2";
CM_ BO_ 2566757374  "Aftertreatment 1 SCR Reagent Information";
CM_ BO_ 2431654654  "Engine Throttle / Fuel Actuator Control Command";
CM_ BO_ 2364545534  "Engine Knock Level #3";
CM_ BO_ 2364545278  "Engine Knock Level #2";
CM_ BO_ 2364545022  "Engine Knock Level #1";
CM_ BO_ 2364544766  "Cylinder Combustion Status";
CM_ BO_ 2364544254  "Blade Information";
CM_ BO_ 2349137662  "External Brake Request";
CM_ BO_ 2566848510  "Water in Fuel Indicator";
CM_ BO_ 2566843134  "Vehicle Weight";
CM_ BO_ 2566804222  "Vehicle Electrical Power #3";
CM_ BO_ 2633928190  "Vehicle Electrical Power 2";
CM_ BO_ 2566845438  "Vehicle Position";
CM_ BO_ 2566843646  "Vehicle Identification";
CM_ BO_ 2566842366  "Vehicle Hours";
CM_ BO_ 2566809854  "Vehicle Fluids";
CM_ BO_ 2566842622  "Vehicle Direction/Speed";
CM_ BO_ 2566832638  "High Resolution Vehicle Distance";
CM_ BO_ 2565868030  "Vehicle Dynamic Stability Control 2";
CM_ BO_ 2566803454  "Vehicle Dynamic Stability Control 1";
CM_ BO_ 2566840574  "Vehicle Distance";
CM_ BO_ 2633938686  "Trip Vehicle Speed/Cruise Distance Information";
CM_ BO_ 2633937150  "Trip Time Information 2";
CM_ BO_ 2633938174  "Trip Time Information 1";
CM_ BO_ 2633938430  "Trip Shutdown Information";
CM_ BO_ 2348875518  "Torque/Speed Control 1";
CM_ BO_ 2566766846  "Passenger Counter";
CM_ BO_ 2566765310  "Farebox Status";
CM_ BO_ 2566765566  "Farebox Point of Sale";
CM_ BO_ 2566765822  "Farebox Service Detail";
CM_ BO_ 2566766078  "Signal Preemption";
CM_ BO_ 2566766590  "Transit Milepost";
CM_ BO_ 2566766334  "Transit Route";
CM_ BO_ 2561605374  "Tire Pressure Reference Setting";
CM_ BO_ 2566765054  "Tire Pressure Reference Information";
CM_ BO_ 2633923326  "Tire Pressure Control Unit Current Pressures";
CM_ BO_ 2633923070  "Tire Pressure Control Unit Target Pressures";
CM_ BO_ 2633922814  "Tire Pressure Control Unit Mode and Status";
CM_ BO_ 2566845694  "Tire Condition";
CM_ BO_ 2633939966  "Trip Fan Information";
CM_ BO_ 2633939710  "Trip Distance Information";
CM_ BO_ 2564161278  "Time/Date Adjust";
CM_ BO_ 2566842110  "Time/Date";
CM_ BO_ 2566821630  "Turbocharger Wastegate";
CM_ BO_ 2365484286  "Tachograph";
CM_ BO_ 2566771710  "Turbocharger Information 6";
CM_ BO_ 2566821886  "Turbocharger Information 5";
CM_ BO_ 2566822142  "Turbocharger Information 4";
CM_ BO_ 2566822398  "Turbocharger Information 3";
CM_ BO_ 2566822654  "Turbocharger Information 2";
CM_ BO_ 2633931774  "Turbocharger Information 1";
CM_ BO_ 2566802430  "Transmission Configuration 2";
CM_ BO_ 2566841086  "Transmission Configuration";
CM_ SG_ 2633936894 TotalFuelUsed "Total fuel consumed (trip drive fuel + trip PTO moving fuel + trip PTO non-moving fuel + trip idle fuel) over the life of the engine.";
CM_ SG_ 2633936894 TripFuel "Total fuel consumed (trip drive fuel + trip PTO moving fuel + trip PTO non-moving fuel + trip idle fuel) since the last trip reset.";
CM_ SG_ 2566757630 SensorSupplyVoltage6 "Sensor ECU supply voltage 6";
CM_ SG_ 2566757630 SensorSupplyVoltage5 "Sensor ECU supply voltage 5";
CM_ SG_ 2566757630 SensorSupplyVoltage8 "Sensor ECU supply voltage 8";
CM_ SG_ 2566757630 SensorSupplyVoltage7 "Sensor ECU supply voltage 7";
CM_ SG_ 2566757886 SensorSupplyVoltage4 "Sensor ECU supply voltage 4";
CM_ SG_ 2566757886 SensorSupplyVoltage3 "Sensor ECU supply voltage 3";
CM_ SG_ 2566757886 SensorSupplyVoltage2 "Sensor ECU supply voltage 2";
CM_ SG_ 2566757886 SensorSupplyVoltage1 "Sensor ECU supply voltage 1";
CM_ SG_ 2566759678 EnggmntSttusTransInputShaftPTO1 "Reports if this specific PTO drive is engaged.";
CM_ SG_ 2566759678 EnggmntSttusTransInputShaftPTO2 "Reports if this specific PTO drive is engaged.";
CM_ SG_ 2566759678 EnggmntSttusTransOutputShaftPTO "Reports if this specific PTO drive is engaged.";
CM_ SG_ 2566759678 EnggmntSttsTrnsfrCsOtptShaftPTO "Reports if this specific PTO drive is engaged.";
CM_ SG_ 2566759678 EnggmntCnsntTransInputShaftPTO1 "Status of the transmission controller's consent to engage the first or sole PTO drive mounted on the transmission case.";
CM_ SG_ 2566759678 EnggmntCnsntTransInputShaftPTO2 "Status of the transmission controller's consent to engage the second PTO drive mounted on the transmission case.";
CM_ SG_ 2566759678 EnggmntCnsntTransOutputShaftPTO "Status of the transmission controller's consent to engage the PTO drive connected to the transmission output shaft.";
CM_ SG_ 2566759678 EnggmntCnsntTrnsfrCsOtptShftPTO "Status of the transmission controller's consent to engage the PTO drive connected to the transfer case output shaft.";
CM_ SG_ 2566759678 EnableSwitchTransInputShaftPTO1 "Status of the operator's switch or other input which indicates the desire for engaging the first PTO drive mounted on the";
CM_ SG_ 2566759678 EnableSwitchTransInputShaftPTO2 "Status of the operator's switch or other input which indicates the desire for engaging the second PTO drive mounted on";
CM_ SG_ 2566759678 EnableSwitchTransOutputShaftPTO "Status of the operator's switch or other input which indicates the desire for engaging the PTO drive mounted on the";
CM_ SG_ 2566759678 EnblSwtchTrnsfrCsOutputShaftPTO "Status of the operator's switch or other input which indicates the desire for engaging the PTO drive mounted on the output";
CM_ SG_ 2566759678 EnggmntSttsPTOEngAccssoryDrive2 "Engagement status of the PTO engine accessory drive 2";
CM_ SG_ 2566759678 EnggmntSttsPTOEngAccssoryDrive1 "Engagement status of the PTO engine accessory drive 1";
CM_ SG_ 2566759678 EnggmntCnsntPTOEngAccssryDrive2 "Engagement Consent status for the PTO engine accessory drive 2";
CM_ SG_ 2566759678 EnggmntCnsntPTOEngAccssryDrive1 "Engagement consent status for the PTO engine accessory drive 1";
CM_ SG_ 2566759678 EngagementStatusPTOEngFlywheel "Engagement status of the PTO Engine Flywheel";
CM_ SG_ 2566759678 EngagementConsentPTOEngFlywheel "Engagement Consent status for the PTO Engine Flywheel";
CM_ SG_ 2566759678 EnblSwitchPTOEngAccessoryDrive2 "Status of the PTO engine accessory drive 2 enable switch";
CM_ SG_ 2566759678 EnblSwitchPTOEngAccessoryDrive1 "Status of the PTO engine accessory drive 1 enable switch";
CM_ SG_ 2566759678 EnableSwitchPTOEngFlywheel "Status of the PTO Engine Flywheel enable switch";
CM_ SG_ 2566759678 AtLeastOnePTOEngaged "Indicates that at least one PTO is engaged";
CM_ SG_ 2432541438 EngFuelValve2OutletAbsPress "Absolute pressure of gas on outlet side of the second fuel system control valve.";
CM_ SG_ 2432541438 EngFuelTemp2 "Temperature 2 of fuel (or gas).";
CM_ SG_ 2432541438 EngGas2MassFlowRate "Gas mass flow rate delivered to an engine through its second fuel control system, using standard convention for";
CM_ SG_ 2432541438 EngFuelValve2IntakeAbsPress "Absolute pressure of gas on intake side of the second fuel system control valve, using standard convention for";
CM_ SG_ 2432541694 EngVrableGeometryTurboActuator1 "Actuator that controls the variable geometry turbocharger geometry.";
CM_ SG_ 2432541694 EngTrbCmprssrBypssActtr1TmpStts "Used to identify the status of the Engine Turbocharger Compresssor Bypass Actuator 1 drive circuitry temperature.";
CM_ SG_ 2432541694 EngTrbCmprssrBypssActtr1PrlmnryF "Used to identify the appplicable J1939-73 FMI detected in the Engine Turbocharger Compressor Bypass Actuator 1 by";
CM_ SG_ 2432541694 EngTrbCmprssrBypassActuator2Cmd "The command to a compressor bypass actuator 2, normalized to percent, where 0% nominally represents fully closed and";
CM_ SG_ 2432541694 EngTrbCmprssrBypassActuator1Pos "Measures the position of the turbocharger compressor bypass actuator, where 0% represents bypass fully closed and";
CM_ SG_ 2432541694 EngTrbCmprssrBypassActuator1Cmd "The command to a compressor bypass actuator, normalized to percent, where 0% nominally represents fully closed and";
CM_ SG_ 2432541694 EngDsrdTrbCmprssrBypssActtr1Pos "The requested position of the Engine Turbocharger Compressor Bypass actuator by the engine ECM, where 0%";
CM_ SG_ 2566759934 EnableStatusOfDoor10 "Enable status of bus door 10.";
CM_ SG_ 2566759934 OpenStatusOfDoor10 "Open status of bus door 10";
CM_ SG_ 2566759934 LockStatusOfDoor10 "Lock status of bus door 10";
CM_ SG_ 2566759934 EnableStatusOfDoor9 "Enable status of bus door 9.";
CM_ SG_ 2566759934 OpenStatusOfDoor9 "Open status of bus door 9";
CM_ SG_ 2566759934 LockStatusOfDoor9 "Lock status of bus door 9";
CM_ SG_ 2566759934 EnableStatusOfDoor8 "Enable status of bus door 8.";
CM_ SG_ 2566759934 OpenStatusOfDoor8 "Open status of bus door 8";
CM_ SG_ 2566759934 LockStatusOfDoor8 "Lock status of bus door 8";
CM_ SG_ 2566759934 EnableStatusOfDoor7 "Enable status of bus door 7.";
CM_ SG_ 2566759934 OpenStatusOfDoor7 "Open status of bus door 7";
CM_ SG_ 2566759934 LockStatusOfDoor7 "Lock status of bus door 7";
CM_ SG_ 2566759934 EnableStatusOfDoor6 "Enable status of bus door 6.";
CM_ SG_ 2566759934 OpenStatusOfDoor6 "Open status of bus door 6";
CM_ SG_ 2566759934 LockStatusOfDoor6 "Lock status of bus door 6";
CM_ SG_ 2566759934 EnableStatusOfDoor5 "Enable status of bus door 5.";
CM_ SG_ 2566759934 OpenStatusOfDoor5 "Open status of bus door 5";
CM_ SG_ 2566759934 LockStatusOfDoor5 "Lock status of bus door 5";
CM_ SG_ 2566759934 EnableStatusOfDoor4 "Enable status of bus door 4.";
CM_ SG_ 2566759934 OpenStatusOfDoor4 "Open status of bus door 4";
CM_ SG_ 2566759934 LockStatusOfDoor4 "Lock status of bus door 4";
CM_ SG_ 2566759934 EnableStatusOfDoor3 "Enable status of bus door 3.";
CM_ SG_ 2566759934 OpenStatusOfDoor3 "Open status of bus door 3";
CM_ SG_ 2566759934 LockStatusOfDoor3 "Lock status of bus door 3";
CM_ SG_ 2566759934 EnableStatusOfDoor2 "Enable status of bus door 2.";
CM_ SG_ 2566759934 OpenStatusOfDoor2 "Open status of bus door 2";
CM_ SG_ 2566759934 LockStatusOfDoor2 "Lock status of bus door 2";
CM_ SG_ 2566759934 EnableStatusOfDoor1 "Enable status of bus door 1.";
CM_ SG_ 2566759934 OpenStatusOfDoor1 "Open status of bus door 1";
CM_ SG_ 2566759934 LockStatusOfDoor1 "Lock status of bus door 1";
CM_ SG_ 2566757374 Aftrtrtmnt1SCRCtlystRgntTmp2Prlm "Used to identify the applicable J1939-73 FMI that applies to the most significant failure of the catalyst temperature sensor.";
CM_ SG_ 2566757374 Aftrtrtmnt1SCRCtlystRgntPrprtsPr "Used to identify the applicable J1939-73 FMI that applies to the most significant failure of the catalyst reagent properties";
CM_ SG_ 2566757374 Aftrtrtmnt1SCRCtlystRgntCndctvty "A measure of the conductivity of the reagent or fluid at the sensor.";
CM_ SG_ 2566757374 Aftrtrtmnt1SCRCtlystRgntCncntrtn "A measure of the concentration of urea in water.";
CM_ SG_ 2566757374 Aftrtrtmnt1SCRCtlystReagentType "This parameter indicates what reagent is in the tank.";
CM_ SG_ 2566757374 Aftrtrtmnt1SCRCtlystRagentTemp2 "Temperature of the catalyst reagent at the device measuring reagent quality";
CM_ SG_ 2431654654 EngThrottleActuator2CtrlCmd "The control command to throttle actuator 2, normalized to percent, where 0% represents fully closed and 100%";
CM_ SG_ 2431654654 EngThrottleActuator1CtrlCmd "The control command to throttle actuator 1, normalized to percent, where 0% represents fully closed and 100%";
CM_ SG_ 2431654654 EngFuelActuator2CtrlCmd "The control command to fuel actuator 2, normalized to percent, where 0% represents fully closed and 100% represents";
CM_ SG_ 2431654654 EngFuelActuator1CtrlCmd "The control command to fuel actuator 1, normalized to percent, where 0% represents fully closed and 100% represents";
CM_ SG_ 2364545534 EngCyl24KnockLevel "Used to indicate the level of knock for engine cylinder 24.";
CM_ SG_ 2364545534 EngCyl23KnockLevel "Used to indicate the level of knock for engine cylinder 23.";
CM_ SG_ 2364545534 EngCyl22KnockLevel "Used to indicate the level of knock for engine cylinder 22.";
CM_ SG_ 2364545534 EngCyl21KnockLevel "Used to indicate the level of knock for engine cylinder 21.";
CM_ SG_ 2364545534 EngCyl20KnockLevel "Used to indicate the level of knock for engine cylinder 20.";
CM_ SG_ 2364545534 EngCyl19KnockLevel "Used to indicate the level of knock for engine cylinder 19.";
CM_ SG_ 2364545534 EngCyl18KnockLevel "Used to indicate the level of knock for engine cylinder 18.";
CM_ SG_ 2364545534 EngCyl17KnockLevel "Used to indicate the level of knock for engine cylinder 17.";
CM_ SG_ 2364545278 EngCyl15KnockLevel "Used to indicate the level of knock for engine cylinder 15.";
CM_ SG_ 2364545278 EngCyl14KnockLevel "Used to indicate the level of knock for engine cylinder 14.";
CM_ SG_ 2364545278 EngCyl13KnockLevel "Used to indicate the level of knock for engine cylinder 13.";
CM_ SG_ 2364545278 EngCyl12KnockLevel "Used to indicate the level of knock for engine cylinder 12.";
CM_ SG_ 2364545278 EngCyl11KnockLevel "Used to indicate the level of knock for engine cylinder 11.";
CM_ SG_ 2364545278 EngCyl10KnockLevel "Used to indicate the level of knock for engine cylinder 10.";
CM_ SG_ 2364545278 EngCyl9KnockLevel "Used to indicate the level of knock for engine cylinder 9.";
CM_ SG_ 2364545278 EngCyl16KnockLevel "Used to indicate the level of knock for engine cylinder 16.";
CM_ SG_ 2364545022 EngCyl8KnockLevel "Used to indicate the level of knock for engine cylinder 8.";
CM_ SG_ 2364545022 EngCyl7KnockLevel "Used to indicate the level of knock for engine cylinder 7.";
CM_ SG_ 2364545022 EngCyl6KnockLevel "Used to indicate the level of knock for engine cylinder 6.";
CM_ SG_ 2364545022 EngCyl5KnockLevel "Used to indicate the level of knock for engine cylinder 5.";
CM_ SG_ 2364545022 EngCyl4KnockLevel "Used to indicate the level of knock for engine cylinder 4.";
CM_ SG_ 2364545022 EngCyl3KnockLevel "Used to indicate the level of knock for engine cylinder 3.";
CM_ SG_ 2364545022 EngCyl2KnockLevel "Used to indicate the level of knock for engine cylinder 2.";
CM_ SG_ 2364545022 EngCyl1KnockLevel "Used to indicate the level of knock for engine cylinder 1.";
CM_ SG_ 2364544766 EngCyl9CombustionStatus "This parameter is used to indicate state of combustion in engine cylinder #9";
CM_ SG_ 2364544766 EngCyl8CombustionStatus "This parameter is used to indicate state of combustion in engine cylinder #8";
CM_ SG_ 2364544766 EngCyl7CombustionStatus "This parameter is used to indicate state of combustion in engine cylinder #7";
CM_ SG_ 2364544766 EngCyl6CombustionStatus "This parameter is used to indicate state of combustion in engine cylinder #6";
CM_ SG_ 2364544766 EngCyl5CombustionStatus "This parameter is used to indicate state of combustion in engine cylinder #5";
CM_ SG_ 2364544766 EngCyl4CombustionStatus "This parameter is used to indicate state of combustion in engine cylinder #4";
CM_ SG_ 2364544766 EngCyl3CombustionStatus "This parameter is used to indicate state of combustion in engine cylinder #3";
CM_ SG_ 2364544766 EngCyl2CombustionStatus "This parameter is used to indicate state of combustion in engine cylinder #2";
CM_ SG_ 2364544766 EngCyl24CombustionStatus "This parameter is used to indicate state of combustion in engine cylinder #24";
CM_ SG_ 2364544766 EngCyl23CombustionStatus "This parameter is used to indicate state of combustion in engine cylinder #23";
CM_ SG_ 2364544766 EngCyl22CombustionStatus "This parameter is used to indicate state of combustion in engine cylinder #22";
CM_ SG_ 2364544766 EngCyl21CombustionStatus "This parameter is used to indicate state of combustion in engine cylinder #21";
CM_ SG_ 2364544766 EngCyl20CombustionStatus "This parameter is used to indicate state of combustion in engine cylinder #20";
CM_ SG_ 2364544766 EngCyl1CombustionStatus "This parameter is used to indicate state of combustion in engine cylinder #1";
CM_ SG_ 2364544766 EngCyl19CombustionStatus "This parameter is used to indicate state of combustion in engine cylinder #19";
CM_ SG_ 2364544766 EngCyl18CombustionStatus "This parameter is used to indicate state of combustion in engine cylinder #18";
CM_ SG_ 2364544766 EngCyl17CombustionStatus "This parameter is used to indicate state of combustion in engine cylinder #17";
CM_ SG_ 2364544766 EngCyl16CombustionStatus "This parameter is used to indicate state of combustion in engine cylinder #16";
CM_ SG_ 2364544766 EngCyl15CombustionStatus "This parameter is used to indicate state of combustion in engine cylinder #15";
CM_ SG_ 2364544766 EngCyl14CombustionStatus "This parameter is used to indicate state of combustion in engine cylinder #14";
CM_ SG_ 2364544766 EngCyl13CombustionStatus "This parameter is used to indicate state of combustion in engine cylinder #13";
CM_ SG_ 2364544766 EngCyl12CombustionStatus "This parameter is used to indicate state of combustion in engine cylinder #12";
CM_ SG_ 2364544766 EngCyl11CombustionStatus "This parameter is used to indicate state of combustion in engine cylinder #11";
CM_ SG_ 2364544766 EngCyl10CombustionStatus "This parameter is used to indicate state of combustion in engine cylinder #10";
CM_ SG_ 2364544254 RltvBldHghtAndBldRttnAnglMsrmntL "The estimated measurement latency of the measurement.";
CM_ SG_ 2364544254 RlativeBladeHeightFigureOfMerit "Figure of merit for blade height measurement.";
CM_ SG_ 2364544254 BladeRotationAngleFigureOfMerit "Figure of merit for blade rotation measurement.";
CM_ SG_ 2364544254 BladeRotationAngle "The blade rotation angle measurement around the yaw (z-axis).";
CM_ SG_ 2364544254 RelativeBladeHeight "The measured vertical distance from a fixed location on the machine blade to a ground-based reference.";
CM_ SG_ 2349137662 XBRMessageChecksum "The XBR message checksum is used to verify the signal path from the demanding device to the brake controller on";
CM_ SG_ 2349137662 XBRMessageCounter "The XBR message counter is to verify the signal path from the demanding device to the brake controller on electronic";
CM_ SG_ 2349137662 XBRCtrlMode "The XBR Control Mode is used as an input to the brake system and defines how the external acceleration demand has to";
CM_ SG_ 2349137662 XBRPriority "The XBR Priority is used as an input to the brake system to manage the priority of overlapping external and internal requests.";
CM_ SG_ 2349137662 XBREBIMode "The XBR EBI (Endurance Brake Integration) Mode is used as an input for the brake system to prescribe the use of";
CM_ SG_ 2349137662 ExtlAccelerationDemand "Parameter provided to the brake system from external sources.";
CM_ SG_ 2349137662 XBRUrgency "The idea of the urgency value is to adjust the endurance brake integration behavior in the EBS system according to the";
CM_ SG_ 2566848510 WaterInFuelIndicator "Signal which indicates the presence of water in the fuel.";
CM_ SG_ 2566843134 AxleLocation "To identify to which of several similar devices (such as tires or fuel tanks) the information applies.";
CM_ SG_ 2566843134 CargoWeight_30 "The mass of freight carried.";
CM_ SG_ 2566843134 CargoWeight_20 "The mass of freight carried.";
CM_ SG_ 2566843134 CargoWeight_10 "The mass of freight carried.";
CM_ SG_ 2566843134 CargoWeight_00 "The mass of freight carried.";
CM_ SG_ 2566843134 TrailerWeight_30 "Total mass of freight-carrying vehicle designed to be pulled by truck, including the weight of the contents.";
CM_ SG_ 2566843134 TrailerWeight_20 "Total mass of freight-carrying vehicle designed to be pulled by truck, including the weight of the contents.";
CM_ SG_ 2566843134 TrailerWeight_10 "Total mass of freight-carrying vehicle designed to be pulled by truck, including the weight of the contents.";
CM_ SG_ 2566843134 TrailerWeight_00 "Total mass of freight-carrying vehicle designed to be pulled by truck, including the weight of the contents.";
CM_ SG_ 2566843134 AxleWeight_30 "Total mass imposed by the tires on the road surface at the specified axle.";
CM_ SG_ 2566843134 AxleWeight_20 "Total mass imposed by the tires on the road surface at the specified axle.";
CM_ SG_ 2566843134 AxleWeight_10 "Total mass imposed by the tires on the road surface at the specified axle.";
CM_ SG_ 2566843134 AxleWeight_00 "Total mass imposed by the tires on the road surface at the specified axle.";
CM_ SG_ 2566804222 NetBatteryCurrentHiRes "Net flow of electrical current into/out-of the battery or batteries.";
CM_ SG_ 2566804222 AltCurrentHiRes "This parameter indicates the amount of electrical current output from the alternator of the main vehicle.";
CM_ SG_ 2633928190 ECUPowerOutputSupplyVoltage3 "The third power output from an ECM.";
CM_ SG_ 2633928190 ECUPowerOutputSupplyVoltage2 "The second power output from an ECM.";
CM_ SG_ 2633928190 ECUPowerOutputSupplyVoltage1 "The first power output from an ECM";
CM_ SG_ 2633928190 BatteryPotential_PowerInput2 "This parameter measures the second source of battery potential as measured at the input of the ECM/actuator etc.";
CM_ SG_ 2566845438 Longitude "Longitude position of the vehicle.";
CM_ SG_ 2566845438 Latitude "Latitude position of the vehicle.";
CM_ SG_ 2566843646 VehicleIdentificationNumber "Vehicle Identification Number";
CM_ SG_ 2566842366 TotalPowerTakeoffHours "Accumulated time of operation of power takeoff device.";
CM_ SG_ 2566842366 TotalVehicleHours "Accumulated time of operation of vehicle.";
CM_ SG_ 2566809854 WinchOilPressSwitch "State of switch used to determine if Winch Oil Pressure is above desired minimum";
CM_ SG_ 2566809854 HydOilLevel "This parameter indicates the level of the hydraulic fluid in tank as a ratio of current volume to total tank volume.";
CM_ SG_ 2566809854 HydOilFilterRestrictionSwitch "This switch indicates whether hydraulic oil filter is clogged.";
CM_ SG_ 2566809854 HydTemp "Temperature of hydraulic fluid.";
CM_ SG_ 2566842622 Altitude "Altitude of the vehicle referenced to sea level at standard atmospheric pressure and temperature.";
CM_ SG_ 2566842622 Pitch "Pitch of the vehicle as calculated by the navigation device(s).";
CM_ SG_ 2566842622 NavigationBasedVehicleSpeed "Speed of the vehicle as calculated from a device such as a Global Positioning System (GPS).";
CM_ SG_ 2566842622 CompassBearing "Present compass bearing of vehicle.";
CM_ SG_ 2566832638 HighResolutionTripDistance "Distance traveled during all or part of a journey.";
CM_ SG_ 2566832638 HghRslutionTotalVehicleDistance "Accumulated distance traveled by the vehicle during its operation.";
CM_ SG_ 2565868030 SteerWheelAngle "The main operator`s steering wheel angle (on the steering column, not the actual wheel angle).";
CM_ SG_ 2565868030 LongitudinalAcceleration "Indicates the longitudinal acceleration of the vehicle.";
CM_ SG_ 2565868030 LateralAcceleration "Indicates a lateral acceleration of the vehicle.";
CM_ SG_ 2565868030 YawRate "Indicates the rotation about the vertical axis.";
CM_ SG_ 2565868030 SteerWheelAngleSensorType "Indicates whether the steering wheel angle sensor is capable of absolute measuring of the number of steering wheel";
CM_ SG_ 2565868030 SteerWheelTurnCounter "Indicates number of steering wheel turns, absolute position or relative position at ignition on.";
CM_ SG_ 2566803454 YCBrakeCtrlActive "State signal which indicates that Yaw Control (YC) has activated brake control.";
CM_ SG_ 2566803454 YCEngCtrlActive "State Signal which indicates that the Yaw Control (YC) has commanded engine control to be active.";
CM_ SG_ 2566803454 ROPBrakeCtrlActive "State signal which indicates that Roll over Prevention (ROP) has activated brake control.";
CM_ SG_ 2566803454 ROPEngCtrlActive "State Signal which indicates that the Roll Over Prevention (ROP) has commanded engine control to be active.";
CM_ SG_ 2566803454 VDCBrakeLightRq "Indicates whether VDC requests to turn the vehicle brake lights on";
CM_ SG_ 2566803454 VDCFullyOperational "Signal that indicates whether VDC is fully operational or whether its functionality is reduced by a permanent or temporary";
CM_ SG_ 2566803454 VDCInformationSignal "This parameter commands the VDC information signal, for example a dash lamp.";
CM_ SG_ 2566840574 TotalVehicleDistance "Accumulated distance traveled by vehicle during its operation.";
CM_ SG_ 2566840574 TripDistance "Distance traveled during all or part of a journey.";
CM_ SG_ 2633938686 TripCruiseDistance "Total distance that the engine has operated in the cruise hold state, excluding time in accelerator override, since the last";
CM_ SG_ 2633938686 TripMaxVehicleSpeed "Maximum vehicle speed achieved while the engine speed is greater than zero and the accelerator pedal position (APS) is";
CM_ SG_ 2633937150 TripAirCompressorOnTime "Total time that the air compressor is on and compressing air since the last trip reset.";
CM_ SG_ 2633937150 TripIdleTime "Total time accumulated while the engine speed is greater than zero, both the PTO and remote PTO governors are";
CM_ SG_ 2633937150 TripEngRunningTime "Total time accumulated while the engine speed is greater than zero since the last trip reset.";
CM_ SG_ 2633937150 TripCruiseTime "Total time accumulated while the engine is in the cruise hold state, excluding time in accelerator override, since the last trip reset.";
CM_ SG_ 2633937150 TripPTOGovernorTime "Total time accumulated while the engine is in the PTO or remote PTO governor hold state since the last trip reset.";
CM_ SG_ 2633938174 TripTimeInDerateByEng "Total time accumulated when the engine final fueling has been derated due to an engine protection algorithm, since the last reset.";
CM_ SG_ 2633938174 TripTimeInGearDown "Total time accumulated when the vehicle has operated in one gear down from the top gear for a calibrated minimum time,";
CM_ SG_ 2633938174 TripTimeInTopGear "Total time accumulated when the vehicle has operated in top gear for a calibrated minimum time, since the last trip reset.";
CM_ SG_ 2633938174 TripTimeInVSL "Total time accumulated when the engine has operated on the vehicle speed limiter (VSL) while not in the cruise hold";
CM_ SG_ 2633938430 TripSuddenDecelerations "Total number of decelerations whenever the vehicle deceleration is more than XYZ km/h/sec (where XYZ is a calibratible";
CM_ SG_ 2633938430 TrpNmberOfIdleShutdownOverrides "Total number of times an operator disables idle shutdown to prevent an engine shutdown, since the last trip reset.";
CM_ SG_ 2633938430 TripNumberOfIdleShutdowns "Total number of times the engine has been shutdown due to idling too long (at normal idle or fast idle) since the last trip reset.";
CM_ SG_ 2633938430 TripNumberOfHotShutdowns "Total number of hot shutdowns since the last trip reset.";
CM_ SG_ 2348875518 MessageCounter "The message counter is used to detect situations where the transmitting ECU malfunction repeats the same frame all the time.";
CM_ SG_ 2348875518 ControlPurpose "State signal which indicates which control mode the sending device is using to generate the TSC1 command.";
CM_ SG_ 2348875518 TransmissionRate "This parameter indicates the transmission rate at which the sending device will transmit the TSC1 message.";
CM_ SG_ 2348875518 EngRqedTorque_TorqueLimit "Parameter provided to the engine or retarder in the torque/speed control message for controlling or limiting the output torque.";
CM_ SG_ 2348875518 EngRqedSpeed_SpeedLimit "Parameter provided to the engine from external sources in the torque/speed control message.";
CM_ SG_ 2348875518 EngRqedSpeedCtrlConditions "This mode tells the engine control system the governor characteristics that are desired during speed control.";
CM_ SG_ 2348875518 MessageChecksum "The checksum is used to verify the signal path from the transmitting device to the receiving device.";
CM_ SG_ 2348875518 EngineRequestedTorqueHiRes "This parameter displays an additional torque in percent of the reference engine torque.";
CM_ SG_ 2566766846 TransitRunStatus "Status of the run switch for the vehicle.";
CM_ SG_ 2566766846 VehicleUseStatus "Used to indicate the proper or unauthorized use of the vehicle.";
CM_ SG_ 2566766846 SilentAlarmStatus "Used to report silent alarm push button status.";
CM_ SG_ 2566766846 PatronCount "Count of the number of passengers on a transit vehicle.";
CM_ SG_ 2566766846 TypeOfPassengerCount "Used to notify transit link devices of the type of passenger counting system used in the vehicle.";
CM_ SG_ 2566765310 FareboxAlarmIdentifier "Indicates the nature of the farebox alarm condition.";
CM_ SG_ 2566765310 FareboxEmergencyStatus "Indicates if a farebox emergency condition exists.";
CM_ SG_ 2566765566 TransferSold "Indicates that a transfer was sold or issued on this transaction including its type and/or restrictions.";
CM_ SG_ 2566765566 RouteNumber "The route number issuing the transfer.";
CM_ SG_ 2566765566 TransferType "The kind of transfer used";
CM_ SG_ 2566765566 TypeOfService "The type of service provided";
CM_ SG_ 2566765566 InitialFareAgency "Identifies where the initial fare is paid";
CM_ SG_ 2566765566 PassCategory "Agency defined value indicating the category of the passenger associated with this fare";
CM_ SG_ 2566765566 FareValidity "Agency defined value indicating validity of this fare";
CM_ SG_ 2566765566 PaymentDetails "Payment details.";
CM_ SG_ 2566765566 TypeOfFare "Type of Fare";
CM_ SG_ 2566765566 PassengerType "Enumerated value representing the type/class of passenger, as defined by the agency.";
CM_ SG_ 2566765566 TransactionType "Enumerated value representing the type of transaction completed";
CM_ SG_ 2566765822 DriversFareboxSecurityCode "Security code for the farebox, numerical only.";
CM_ SG_ 2566765822 AssignedBlock "The agency defined block number for this trip";
CM_ SG_ 2566765822 AssignedRun "The agency defined run number for this trip";
CM_ SG_ 2566765822 AssignedRoute "The identity number assigned to this route.";
CM_ SG_ 2566765822 PatternNumber "The agency defined pattern number for this trip";
CM_ SG_ 2566765822 TripNumber "The identity number assigned to this trip.";
CM_ SG_ 2566765822 FarePresets "Fare Presets";
CM_ SG_ 2566765822 TripDirection "The general direction of travel for this trip.";
CM_ SG_ 2566765822 TripStatus "Trip Status";
CM_ SG_ 2566765822 FareboxServiceStatus "Indicates if the farebox is in or out of service.";
CM_ SG_ 2566766078 VehicleID "Numerical designation of the vehicle.";
CM_ SG_ 2566766078 StrobeActivationCtrlStatus "Strobe activation control status";
CM_ SG_ 2566766078 TransitDoorEnable "Transit door enable";
CM_ SG_ 2566766078 PriorityOfRespSentByEmitter "Priority of response sent by emitter";
CM_ SG_ 2566766078 IntersectionPreemptionRq_Resp "Status of the intersection signal preemption";
CM_ SG_ 2566766078 TransitRouteIDUsage "Transit route ID usage";
CM_ SG_ 2566766078 RangeCodeEnable "Range code enable";
CM_ SG_ 2566766590 NmbrOfBytsInMlpstIdentification "Number of bytes in the Milepost Identification.";
CM_ SG_ 2566766334 Agency "The identity of the agency involved in this transaction";
CM_ SG_ 2566766334 NmbrOfBytsInTrnstAssgndBlckIdntt "Number of bytes in the Transit Assigned Block Identity.";
CM_ SG_ 2566766334 NmbrOfBytsInTrnstAssgndRnIdntty "Number of bytes in the Transit Assigned Run Identity.";
CM_ SG_ 2566766334 NmbrOfBytsInTrnstAssgndRtIdntty "Number of bytes in the Transit Assigned Route Identity.";
CM_ SG_ 2561605374 TireLocation "Identifies which tire is associated with the parametric data in this PGN.";
CM_ SG_ 2566765054 TireLocation "Identifies which tire is associated with the parametric data in this PGN.";
CM_ SG_ 2633923326 SteerChannelTirePress "The latest gage pressure reading of the steer group of tires, as opposed to the pressure in each tire.";
CM_ SG_ 2633923326 DriveChannelTirePress "The latest gage pressure reading of the drive group of tires, as opposed to the pressure in each tire.";
CM_ SG_ 2633923326 TrailerTagPushChannelTirePress "The latest gage pressure reading of the trailer, tag, or push group of tires, as opposed to the pressure in each tire.";
CM_ SG_ 2633923070 SteerChannelTirePressTarget "The tire pressure control system's target gage pressure for the steer group of tires.";
CM_ SG_ 2633923070 DriveChannelTirePressTarget "The tire pressure control system's target gage pressure for the drive group of tires.";
CM_ SG_ 2633923070 TrlrTgPshChannelTirePressTarget "The tire pressure control system's target gage pressure for the trailer, tag, or push group of tires.";
CM_ SG_ 2633922814 PCUSupplySolenoidStatus "Current state of the supply solenoid used to implement a tire pressure control system in its pneumatic control unit (PCU).";
CM_ SG_ 2633922814 PCUCtrlSolenoidStatus "Current state of the control solenoid used to implement a tire pressure control system in its pneumatic control unit (PCU).";
CM_ SG_ 2633922814 PCUDeflateSolenoidStatus "Current state of the deflate solenoid used to implement a tire pressure control system in its pneumatic control unit (PCU).";
CM_ SG_ 2633922814 TirePressSupplySwitchStatus "Current state of an open/closed type switch used to determine if adequate pressure exists for system implementation.";
CM_ SG_ 2633922814 PCUSteerSolenoidStatus "Current state of the steer solenoid used to implement a tire pressure control system in its pneumatic control unit (PCU).";
CM_ SG_ 2633922814 PCUDriveSolenoidStatus "Current state of the drive solenoid used to implement a tire pressure control system in its pneumatic control unit (PCU).";
CM_ SG_ 2633922814 DriveChannelMode "Indicates the functional mode of trailer/tag channel of the tire pressure control system.";
CM_ SG_ 2633922814 Trailer_TagChannelMode "Indicates the functional mode of trailer/tag channel of the tire pressure control system.";
CM_ SG_ 2633922814 SteerChannelMode "Indicates the functional mode of steer channel of the tire pressure control system.";
CM_ SG_ 2633922814 TirePressCheckInterval "The interval at which the system will check the tire pressures (e.";
CM_ SG_ 2633922814 PCUTrailerTagPushSolenoidStatus "Current state of the trailer, tag, or push solenoid used to implement a tire pressure control system in its pneumatic control";
CM_ SG_ 2566845694 TirePressThresholdDetection_13 "Signal indicating the pressure level of the tire.";
CM_ SG_ 2566845694 TirePressThresholdDetection_12 "Signal indicating the pressure level of the tire.";
CM_ SG_ 2566845694 TirePressThresholdDetection_11 "Signal indicating the pressure level of the tire.";
CM_ SG_ 2566845694 TirePressThresholdDetection_10 "Signal indicating the pressure level of the tire.";
CM_ SG_ 2566845694 TirePressThresholdDetection_01 "Signal indicating the pressure level of the tire.";
CM_ SG_ 2566845694 TirePress_33 "Pressure at which air is contained in cavity formed by tire and rim.";
CM_ SG_ 2566845694 TirePress_32 "Pressure at which air is contained in cavity formed by tire and rim.";
CM_ SG_ 2566845694 TirePress_31 "Pressure at which air is contained in cavity formed by tire and rim.";
CM_ SG_ 2566845694 TirePress_30 "Pressure at which air is contained in cavity formed by tire and rim.";
CM_ SG_ 2566845694 TirePress_23 "Pressure at which air is contained in cavity formed by tire and rim.";
CM_ SG_ 2566845694 TirePress_22 "Pressure at which air is contained in cavity formed by tire and rim.";
CM_ SG_ 2566845694 TirePress_21 "Pressure at which air is contained in cavity formed by tire and rim.";
CM_ SG_ 2566845694 TirePress_20 "Pressure at which air is contained in cavity formed by tire and rim.";
CM_ SG_ 2566845694 TirePress_13 "Pressure at which air is contained in cavity formed by tire and rim.";
CM_ SG_ 2566845694 TirePress_12 "Pressure at which air is contained in cavity formed by tire and rim.";
CM_ SG_ 2566845694 TirePress_11 "Pressure at which air is contained in cavity formed by tire and rim.";
CM_ SG_ 2566845694 TirePress_10 "Pressure at which air is contained in cavity formed by tire and rim.";
CM_ SG_ 2566845694 TireAirLeakageRate_33 "The pressure loss rate of a tire.";
CM_ SG_ 2566845694 TireAirLeakageRate_32 "The pressure loss rate of a tire.";
CM_ SG_ 2566845694 TireAirLeakageRate_31 "The pressure loss rate of a tire.";
CM_ SG_ 2566845694 TireAirLeakageRate_30 "The pressure loss rate of a tire.";
CM_ SG_ 2566845694 TireAirLeakageRate_23 "The pressure loss rate of a tire.";
CM_ SG_ 2566845694 TireAirLeakageRate_22 "The pressure loss rate of a tire.";
CM_ SG_ 2566845694 TireAirLeakageRate_21 "The pressure loss rate of a tire.";
CM_ SG_ 2566845694 TireAirLeakageRate_20 "The pressure loss rate of a tire.";
CM_ SG_ 2566845694 TireAirLeakageRate_13 "The pressure loss rate of a tire.";
CM_ SG_ 2566845694 TireAirLeakageRate_12 "The pressure loss rate of a tire.";
CM_ SG_ 2566845694 TireAirLeakageRate_11 "The pressure loss rate of a tire.";
CM_ SG_ 2566845694 TireAirLeakageRate_10 "The pressure loss rate of a tire.";
CM_ SG_ 2566845694 TireAirLeakageRate_01 "The pressure loss rate of a tire.";
CM_ SG_ 2566845694 TireAirLeakageRate_00 "The pressure loss rate of a tire.";
CM_ SG_ 2566845694 CTIWheelSensorStatus_33 "Indicates whether the wheel is being monitored by the CTI controller.";
CM_ SG_ 2566845694 CTIWheelSensorStatus_32 "Indicates whether the wheel is being monitored by the CTI controller.";
CM_ SG_ 2566845694 CTIWheelSensorStatus_31 "Indicates whether the wheel is being monitored by the CTI controller.";
CM_ SG_ 2566845694 CTIWheelSensorStatus_30 "Indicates whether the wheel is being monitored by the CTI controller.";
CM_ SG_ 2566845694 CTIWheelSensorStatus_23 "Indicates whether the wheel is being monitored by the CTI controller.";
CM_ SG_ 2566845694 CTIWheelSensorStatus_22 "Indicates whether the wheel is being monitored by the CTI controller.";
CM_ SG_ 2566845694 CTIWheelSensorStatus_21 "Indicates whether the wheel is being monitored by the CTI controller.";
CM_ SG_ 2566845694 CTIWheelSensorStatus_20 "Indicates whether the wheel is being monitored by the CTI controller.";
CM_ SG_ 2566845694 CTIWheelSensorStatus_13 "Indicates whether the wheel is being monitored by the CTI controller.";
CM_ SG_ 2566845694 CTIWheelSensorStatus_12 "Indicates whether the wheel is being monitored by the CTI controller.";
CM_ SG_ 2566845694 CTIWheelSensorStatus_11 "Indicates whether the wheel is being monitored by the CTI controller.";
CM_ SG_ 2566845694 CTIWheelSensorStatus_10 "Indicates whether the wheel is being monitored by the CTI controller.";
CM_ SG_ 2566845694 CTIWheelSensorStatus_01 "Indicates whether the wheel is being monitored by the CTI controller.";
CM_ SG_ 2566845694 CTIWheelEndElectricalFault_33 "Indicates the status of electrical fault on CTI wheel interface.";
CM_ SG_ 2566845694 CTIWheelEndElectricalFault_32 "Indicates the status of electrical fault on CTI wheel interface.";
CM_ SG_ 2566845694 CTIWheelEndElectricalFault_31 "Indicates the status of electrical fault on CTI wheel interface.";
CM_ SG_ 2566845694 CTIWheelEndElectricalFault_30 "Indicates the status of electrical fault on CTI wheel interface.";
CM_ SG_ 2566845694 CTIWheelEndElectricalFault_23 "Indicates the status of electrical fault on CTI wheel interface.";
CM_ SG_ 2566845694 CTIWheelEndElectricalFault_22 "Indicates the status of electrical fault on CTI wheel interface.";
CM_ SG_ 2566845694 CTIWheelEndElectricalFault_21 "Indicates the status of electrical fault on CTI wheel interface.";
CM_ SG_ 2566845694 CTIWheelEndElectricalFault_20 "Indicates the status of electrical fault on CTI wheel interface.";
CM_ SG_ 2566845694 CTIWheelEndElectricalFault_13 "Indicates the status of electrical fault on CTI wheel interface.";
CM_ SG_ 2566845694 CTIWheelEndElectricalFault_12 "Indicates the status of electrical fault on CTI wheel interface.";
CM_ SG_ 2566845694 CTIWheelEndElectricalFault_11 "Indicates the status of electrical fault on CTI wheel interface.";
CM_ SG_ 2566845694 CTIWheelEndElectricalFault_10 "Indicates the status of electrical fault on CTI wheel interface.";
CM_ SG_ 2566845694 CTIWheelEndElectricalFault_01 "Indicates the status of electrical fault on CTI wheel interface.";
CM_ SG_ 2566845694 CTITireStatus_33 "Indicates the status of the tire.";
CM_ SG_ 2566845694 CTITireStatus_32 "Indicates the status of the tire.";
CM_ SG_ 2566845694 CTITireStatus_31 "Indicates the status of the tire.";
CM_ SG_ 2566845694 CTITireStatus_30 "Indicates the status of the tire.";
CM_ SG_ 2566845694 CTITireStatus_23 "Indicates the status of the tire.";
CM_ SG_ 2566845694 CTITireStatus_22 "Indicates the status of the tire.";
CM_ SG_ 2566845694 CTITireStatus_21 "Indicates the status of the tire.";
CM_ SG_ 2566845694 CTITireStatus_20 "Indicates the status of the tire.";
CM_ SG_ 2566845694 CTITireStatus_13 "Indicates the status of the tire.";
CM_ SG_ 2566845694 CTITireStatus_12 "Indicates the status of the tire.";
CM_ SG_ 2566845694 CTITireStatus_11 "Indicates the status of the tire.";
CM_ SG_ 2566845694 CTITireStatus_10 "Indicates the status of the tire.";
CM_ SG_ 2566845694 CTITireStatus_01 "Indicates the status of the tire.";
CM_ SG_ 2566845694 TireTemp_11 "Temperature at the surface of the tire sidewall.";
CM_ SG_ 2566845694 TireTemp_33 "Temperature at the surface of the tire sidewall.";
CM_ SG_ 2566845694 TireTemp_32 "Temperature at the surface of the tire sidewall.";
CM_ SG_ 2566845694 TireTemp_31 "Temperature at the surface of the tire sidewall.";
CM_ SG_ 2566845694 TireTemp_30 "Temperature at the surface of the tire sidewall.";
CM_ SG_ 2566845694 TireTemp_23 "Temperature at the surface of the tire sidewall.";
CM_ SG_ 2566845694 TireTemp_22 "Temperature at the surface of the tire sidewall.";
CM_ SG_ 2566845694 TireTemp_21 "Temperature at the surface of the tire sidewall.";
CM_ SG_ 2566845694 TireTemp_20 "Temperature at the surface of the tire sidewall.";
CM_ SG_ 2566845694 TireTemp_13 "Temperature at the surface of the tire sidewall.";
CM_ SG_ 2566845694 TireTemp_12 "Temperature at the surface of the tire sidewall.";
CM_ SG_ 2566845694 TireTemp_10 "Temperature at the surface of the tire sidewall.";
CM_ SG_ 2566845694 TireTemp_01 "Temperature at the surface of the tire sidewall.";
CM_ SG_ 2566845694 TireTemp_00 "Temperature at the surface of the tire sidewall.";
CM_ SG_ 2566845694 TirePressThresholdDetection_33 "Signal indicating the pressure level of the tire.";
CM_ SG_ 2566845694 TirePressThresholdDetection_32 "Signal indicating the pressure level of the tire.";
CM_ SG_ 2566845694 TirePressThresholdDetection_31 "Signal indicating the pressure level of the tire.";
CM_ SG_ 2566845694 TirePressThresholdDetection_30 "Signal indicating the pressure level of the tire.";
CM_ SG_ 2566845694 TirePressThresholdDetection_23 "Signal indicating the pressure level of the tire.";
CM_ SG_ 2566845694 TirePressThresholdDetection_22 "Signal indicating the pressure level of the tire.";
CM_ SG_ 2566845694 TirePressThresholdDetection_21 "Signal indicating the pressure level of the tire.";
CM_ SG_ 2566845694 TirePressThresholdDetection_20 "Signal indicating the pressure level of the tire.";
CM_ SG_ 2566845694 TirePressThresholdDetection_00 "Signal indicating the pressure level of the tire.";
CM_ SG_ 2566845694 TirePress_01 "Pressure at which air is contained in cavity formed by tire and rim.";
CM_ SG_ 2566845694 TirePress_00 "Pressure at which air is contained in cavity formed by tire and rim.";
CM_ SG_ 2566845694 CTIWheelSensorStatus_00 "Indicates whether the wheel is being monitored by the CTI controller.";
CM_ SG_ 2566845694 CTIWheelEndElectricalFault_00 "Indicates the status of electrical fault on CTI wheel interface.";
CM_ SG_ 2566845694 CTITireStatus_00 "Indicates the status of the tire.";
CM_ SG_ 2566845694 TireLocation "Identifies which tire is associated with the parametric data in this PGN.";
CM_ SG_ 2633939966 TripFanOnTimeDueToAManualSwitch "Total time the fan has been on due to manual activation by the operator (i.";
CM_ SG_ 2633939966 TripFanOnTime "Total time the fan has been on (due to an automatic trigger or manual trigger) since the last trip reset.";
CM_ SG_ 2633939966 TripFanOnTimeDueToA_CSystem "Total time the fan has been on due to the A/C system since the last trip reset.";
CM_ SG_ 2633939966 TripFanOnTimeDueToEngSystem "Total time the fan has been on due to engine triggers (i.";
CM_ SG_ 2633939710 TripDistanceInTopGear "Total distance accumulated while the vehicle has operated in top gear for a calibrated minimum time since the last trip reset.";
CM_ SG_ 2633939710 TripGearDownDistance "Total distance accumulated while the vehicle has operated in the gear which is one gear down from top gear and exceeds";
CM_ SG_ 2633939710 TripDistanceOnVSL "Total distance accumulated while the engine torque mode is road speed governing since the last trip reset.";
CM_ SG_ 2564161278 AdjustLocalHourOffset "The hour component for setting the offset between the UTC (Universal Time Coordinate) time and date and a the local";
CM_ SG_ 2564161278 AdjustLocalMinuteOffset "The minute component for setting the offset between the UTC (Universal Time Coordinate) time and date and a the local";
CM_ SG_ 2564161278 AdjustYear "The year component for setting the current calendar date.";
CM_ SG_ 2564161278 AdjustDay "The day component for setting the current calendar date.";
CM_ SG_ 2564161278 AdjustMonth "The month component for setting the current calendar date.";
CM_ SG_ 2564161278 AdjustHours "The hours component for setting the current time of day.";
CM_ SG_ 2564161278 AdjustMinutes "The minutes component for setting the current time of day.";
CM_ SG_ 2564161278 AdjustSeconds "The seconds component for setting the current time of day.";
CM_ SG_ 2566842110 LocalHourOffset "The hour component of the offset between the UTC (Universal Time Coordinate) time and date and a local time zone time";
CM_ SG_ 2566842110 LocalMinuteOffset "The minute component of the offset between the UTC time and date and a local time zone time and date.";
CM_ SG_ 2566842110 Year "The year component of the current calendar date.";
CM_ SG_ 2566842110 Day "The day component of the current calendar date.";
CM_ SG_ 2566842110 Month "The month component of the current calendar date.";
CM_ SG_ 2566842110 Hours "The hour component of the current time of day.";
CM_ SG_ 2566842110 Minutes "The minutes component of the current time of day.";
CM_ SG_ 2566842110 Seconds "The seconds component of the current time of day.";
CM_ SG_ 2566821630 EngTrbWstgteActuator1TempStatus "Used to identify the status of the Engine Turbocharger Wastegate Actuator 1 drive circuitry temperature.";
CM_ SG_ 2566821630 EngTrbWstgtActtr1PreliminaryFMI "Used to identify the applicable J1939-73 FMI detected in the Engine Turbocharger Wastegate Actuator 1 by the";
CM_ SG_ 2566821630 EngDsrdTrbWastegateActuator2Pos "The Requested Valve position of the Turbocharger Wastegate Valve 2, commanded by the engine ECM.";
CM_ SG_ 2566821630 EngDsrdTrbWastegateActuator1Pos "The Requested Valve position of the Turbocharger Wastegate Valve 1, commanded by the engine ECM.";
CM_ SG_ 2566821630 EngTurboWastegateActuator4Pos "Position of the wastegate drive.";
CM_ SG_ 2566821630 EngTurboWastegateActuator3Pos "Position of the wastegate drive.";
CM_ SG_ 2566821630 EngTurboWastegateActuator2Pos "Position of the wastegate drive.";
CM_ SG_ 2566821630 EngTurboWastegateActuator1Pos "Position of the wastegate drive.";
CM_ SG_ 2566821630 EngTrbWstgtActuatorCtrlAirPress "Gage pressure of the air used to control the actuator which opens and closes the wastegate valve.";
CM_ SG_ 2365484286 VehicleOverspeed "Indicates whether the vehicle is exceeding the legal speed limit set in the tachograph.";
CM_ SG_ 2365484286 VehicleMotion "Indicates whether motion of the vehicle is detected or not.";
CM_ SG_ 2365484286 TachographVehicleSpeed "Speed of the vehicle registered by the tachograph.";
CM_ SG_ 2365484286 TachographOutputShaftSpeed "Calculated speed of the transmission output shaft.";
CM_ SG_ 2365484286 DirectionIndicator "Indicates the direction of the vehicle.";
CM_ SG_ 2365484286 TachographPerformance "Indicates the tachograph performance; including electronic or mechanical analysis, instrument analysis, speed sensor";
CM_ SG_ 2365484286 HandlingInformation "Indicates that handling information is present.";
CM_ SG_ 2365484286 SystemEvent "Indicates that a tachograph event has occurred.";
CM_ SG_ 2365484286 DriverCardDriver2 "Indicates the presence of a driver card";
CM_ SG_ 2365484286 Driver2TimeRelatedStates "Indicates if the driver approaches or exceeds working time limits (or other limits).";
CM_ SG_ 2365484286 DriverCardDriver1 "Indicates the presence of a driver card";
CM_ SG_ 2365484286 Driver1TimeRelatedStates "Indicates if the driver approaches or exceeds working time limits (or other limits).";
CM_ SG_ 2365484286 Driver2WorkingState "State of work of the driver.";
CM_ SG_ 2365484286 Driver1WorkingState "State of work of the driver.";
CM_ SG_ 2566771710 EngTurbo4CompressorOutletTemp "Temperature of the air exiting the turbocharger 4 compressor outlet";
CM_ SG_ 2566771710 EngTurbo3CompressorOutletTemp "Temperature of the air exiting the turbocharger 3 compressor outlet";
CM_ SG_ 2566771710 EngTurbo2CompressorOutletTemp "Temperature of the air exiting the turbocharger 2 compressor outlet";
CM_ SG_ 2566771710 EngTurbo1CompressorOutletTemp "Temperature of the air exiting the turbocharger 1 compressor outlet";
CM_ SG_ 2566821886 EngTurbo4TurbineOutletTemp "Temperature of the combustion by-products exiting the turbine side of the turbocharger.";
CM_ SG_ 2566821886 EngTurbo3TurbineOutletTemp "Temperature of the combustion by-products exiting the turbine side of the turbocharger.";
CM_ SG_ 2566821886 EngTurbo2TurbineOutletTemp "Temperature of the combustion by-products exiting the turbine side of the turbocharger.";
CM_ SG_ 2566821886 EngTurbo1TurbineOutletTemp "Temperature of the combustion by-products exiting the turbine side of the turbocharger.";
CM_ SG_ 2566822142 EngTurbo4TurbineIntakeTemp "Temperature of the combustion by-products entering the turbine side of the turbocharger.";
CM_ SG_ 2566822142 EngTurbo3TurbineIntakeTemp "Temperature of the combustion by-products entering the turbine side of the turbocharger.";
CM_ SG_ 2566822142 EngTurbo2TurbineIntakeTemp "Temperature of the combustion by-products entering the turbine side of the turbocharger.";
CM_ SG_ 2566822142 EngTurbo1TurbineIntakeTemp "Temperature of the combustion by-products entering the turbine side of the turbocharger.";
CM_ SG_ 2566822398 EngTurbo4CompressorIntakePress "Gage pressure of the air entering the compressor side of the turbocharger.";
CM_ SG_ 2566822398 EngTurbo3CompressorIntakePress "Gage pressure of the air entering the compressor side of the turbocharger.";
CM_ SG_ 2566822398 EngTurbo2CompressorIntakePress "Gage pressure of the air entering the compressor side of the turbocharger.";
CM_ SG_ 2566822398 EngTurbo1CompressorIntakePress "Gage pressure of the air entering the compressor side of the turbocharger.";
CM_ SG_ 2566822654 EngTurbo4CompressorIntakeTemp "Temperature of the air entering the compressor side of the turbocharger.";
CM_ SG_ 2566822654 EngTurbo3CompressorIntakeTemp "Temperature of the air entering the compressor side of the turbocharger.";
CM_ SG_ 2566822654 EngTurbo2CompressorIntakeTemp "Temperature of the air entering the compressor side of the turbocharger.";
CM_ SG_ 2566822654 EngTurbo1CompressorIntakeTemp "Temperature of the air entering the compressor side of the turbocharger.";
CM_ SG_ 2633931774 EngTurbo4Speed "Rotational velocity of rotor in the turbocharger.";
CM_ SG_ 2633931774 EngTurbo3Speed "Rotational velocity of rotor in the turbocharger.";
CM_ SG_ 2633931774 EngTurbo2Speed "Rotational velocity of rotor in the turbocharger.";
CM_ SG_ 2633931774 EngTurboLubeOilPress2 "Gage pressure of oil in turbocharger lubrication system.";
CM_ SG_ 2566802430 TransTorqueLimit "Parameter provided to the engine from the transmission as a torque limit to be invoked by the engine in the event that";
CM_ SG_ 2566841086 TransGearRatio "The transmission configuration describes the number of forward gears, the number of reverse gears, and the ratio of each";
CM_ SG_ 2566841086 NumberOfForwardGearRatios "Number of forward gear ratios in the transmission, provided as part of the configuration.";
CM_ SG_ 2566841086 NumberOfReverseGearRatios "Number of reverse gear ratios in the transmission, provided as part of the transmission configuration.";

BA_DEF_ BO_ "GenMsgCycleTime" INT 0 3600000;
BA_DEF_ BO_ "GenMsgSendType" ENUM  "cyclic","reserved","cyclicIfActive","reserved","reserved","reserved","reserved","reserved","noMsgSendType";
BA_DEF_ BO_ "GenMsgStartDelayTime" INT 0 100000;
BA_DEF_ BO_ "VFrameFormat" ENUM  "StandardCAN","ExtendedCAN","reserved","J1939PG";
BA_DEF_ SG_ "GenSigStartValue" INT 0 10000;
BA_DEF_ SG_ "SPN" INT 0 524287;
BA_DEF_ SG_ "SigType" ENUM  "Default","Range","RangeSigned","ASCII","Discrete","Control","ReferencePGN","DTC","StringDelimiter","StringLength","StringLengthControl";
BA_DEF_ SG_ "SystemSignalLongSymbol" STRING;
BA_DEF_DEF_ "GenMsgCycleTime" 0;
BA_DEF_DEF_ "GenMsgSendType" "noMsgSendType";
BA_DEF_DEF_ "GenMsgStartDelayTime" 0;
BA_DEF_DEF_ "GenSigStartValue" 0;
BA_DEF_DEF_ "SPN" 0;
BA_DEF_DEF_ "SigType" "Default";
BA_DEF_DEF_ "VFrameFormat" "J1939PG";
BA_ "GenMsgCycleTime" BO_ 2566757630 1000;
BA_ "GenMsgSendType" BO_ 2566757630 0;
BA_ "GenMsgCycleTime" BO_ 2566757886 1000;
BA_ "GenMsgSendType" BO_ 2566757886 0;
BA_ "GenMsgCycleTime" BO_ 2566759678 100;
BA_ "GenMsgSendType" BO_ 2566759678 0;
BA_ "GenMsgCycleTime" BO_ 2432541438 500;
BA_ "GenMsgSendType" BO_ 2432541438 0;
BA_ "GenMsgCycleTime" BO_ 2432541694 100;
BA_ "GenMsgSendType" BO_ 2432541694 0;
BA_ "GenMsgCycleTime" BO_ 2566759934 100;
BA_ "GenMsgSendType" BO_ 2566759934 0;
BA_ "GenMsgCycleTime" BO_ 2566757374 1000;
BA_ "GenMsgSendType" BO_ 2566757374 0;
BA_ "GenMsgCycleTime" BO_ 2431654654 50;
BA_ "GenMsgSendType" BO_ 2431654654 0;
BA_ "GenMsgCycleTime" BO_ 2364545534 5000;
BA_ "GenMsgSendType" BO_ 2364545534 0;
BA_ "GenMsgCycleTime" BO_ 2364545278 5000;
BA_ "GenMsgSendType" BO_ 2364545278 0;
BA_ "GenMsgCycleTime" BO_ 2364545022 5000;
BA_ "GenMsgSendType" BO_ 2364545022 0;
BA_ "GenMsgCycleTime" BO_ 2364544766 5000;
BA_ "GenMsgSendType" BO_ 2364544766 0;
BA_ "GenMsgCycleTime" BO_ 2364544254 50;
BA_ "GenMsgSendType" BO_ 2364544254 0;
BA_ "GenMsgCycleTime" BO_ 2349137662 20;
BA_ "GenMsgSendType" BO_ 2349137662 2;
BA_ "GenMsgCycleTime" BO_ 2566848510 10000;
BA_ "GenMsgSendType" BO_ 2566848510 0;
BA_ "GenMsgCycleTime" BO_ 2566804222 1000;
BA_ "GenMsgSendType" BO_ 2566804222 0;
BA_ "GenMsgCycleTime" BO_ 2566845438 5000;
BA_ "GenMsgSendType" BO_ 2566845438 0;
BA_ "GenMsgCycleTime" BO_ 2566809854 1000;
BA_ "GenMsgSendType" BO_ 2566809854 0;
BA_ "GenMsgCycleTime" BO_ 2566832638 1000;
BA_ "GenMsgSendType" BO_ 2566832638 0;
BA_ "GenMsgCycleTime" BO_ 2565868030 10;
BA_ "GenMsgSendType" BO_ 2565868030 0;
BA_ "GenMsgCycleTime" BO_ 2566803454 100;
BA_ "GenMsgSendType" BO_ 2566803454 0;
BA_ "GenMsgCycleTime" BO_ 2566840574 100;
BA_ "GenMsgSendType" BO_ 2566840574 0;
BA_ "GenMsgCycleTime" BO_ 2566845694 10000;
BA_ "GenMsgSendType" BO_ 2566845694 0;
BA_ "GenMsgCycleTime" BO_ 2566821630 100;
BA_ "GenMsgSendType" BO_ 2566821630 0;
BA_ "GenMsgCycleTime" BO_ 2365484286 50;
BA_ "GenMsgSendType" BO_ 2365484286 0;
BA_ "GenMsgCycleTime" BO_ 2566771710 1000;
BA_ "GenMsgSendType" BO_ 2566771710 0;
BA_ "GenMsgCycleTime" BO_ 2566821886 1000;
BA_ "GenMsgSendType" BO_ 2566821886 0;
BA_ "GenMsgCycleTime" BO_ 2566822142 1000;
BA_ "GenMsgSendType" BO_ 2566822142 0;
BA_ "GenMsgCycleTime" BO_ 2566822398 1000;
BA_ "GenMsgSendType" BO_ 2566822398 0;
BA_ "GenMsgCycleTime" BO_ 2566822654 1000;
BA_ "GenMsgSendType" BO_ 2566822654 0;
BA_ "GenMsgCycleTime" BO_ 2633931774 1000;
BA_ "GenMsgSendType" BO_ 2633931774 0;
BA_ "SPN" SG_ 2633936894 TotalFuelUsed 1040;
BA_ "SigType" SG_ 2633936894 TotalFuelUsed 1;
BA_ "SPN" SG_ 2633936894 TripFuel 1039;
BA_ "SigType" SG_ 2633936894 TripFuel 1;
BA_ "SPN" SG_ 2566757630 SensorSupplyVoltage6 3514;
BA_ "SigType" SG_ 2566757630 SensorSupplyVoltage6 1;
BA_ "SPN" SG_ 2566757630 SensorSupplyVoltage5 3513;
BA_ "SigType" SG_ 2566757630 SensorSupplyVoltage5 1;
BA_ "SPN" SG_ 2566757630 SensorSupplyVoltage8 5126;
BA_ "SigType" SG_ 2566757630 SensorSupplyVoltage8 1;
BA_ "SPN" SG_ 2566757630 SensorSupplyVoltage7 5125;
BA_ "SigType" SG_ 2566757630 SensorSupplyVoltage7 1;
BA_ "SPN" SG_ 2566757886 SensorSupplyVoltage4 3512;
BA_ "SigType" SG_ 2566757886 SensorSupplyVoltage4 1;
BA_ "SPN" SG_ 2566757886 SensorSupplyVoltage3 3511;
BA_ "SigType" SG_ 2566757886 SensorSupplyVoltage3 1;
BA_ "SPN" SG_ 2566757886 SensorSupplyVoltage2 3510;
BA_ "SigType" SG_ 2566757886 SensorSupplyVoltage2 1;
BA_ "SPN" SG_ 2566757886 SensorSupplyVoltage1 3509;
BA_ "SigType" SG_ 2566757886 SensorSupplyVoltage1 1;
BA_ "SPN" SG_ 2566759678 EnggmntSttusTransInputShaftPTO1 3460;
BA_ "SigType" SG_ 2566759678 EnggmntSttusTransInputShaftPTO1 4;
BA_ "SPN" SG_ 2566759678 EnggmntSttusTransInputShaftPTO2 3461;
BA_ "SigType" SG_ 2566759678 EnggmntSttusTransInputShaftPTO2 4;
BA_ "SPN" SG_ 2566759678 EnggmntSttusTransOutputShaftPTO 3462;
BA_ "SigType" SG_ 2566759678 EnggmntSttusTransOutputShaftPTO 4;
BA_ "SPN" SG_ 2566759678 EnggmntSttsTrnsfrCsOtptShaftPTO 3463;
BA_ "SigType" SG_ 2566759678 EnggmntSttsTrnsfrCsOtptShaftPTO 4;
BA_ "SPN" SG_ 2566759678 EnggmntCnsntTransInputShaftPTO1 3456;
BA_ "SigType" SG_ 2566759678 EnggmntCnsntTransInputShaftPTO1 4;
BA_ "SPN" SG_ 2566759678 EnggmntCnsntTransInputShaftPTO2 3457;
BA_ "SigType" SG_ 2566759678 EnggmntCnsntTransInputShaftPTO2 4;
BA_ "SPN" SG_ 2566759678 EnggmntCnsntTransOutputShaftPTO 3458;
BA_ "SigType" SG_ 2566759678 EnggmntCnsntTransOutputShaftPTO 4;
BA_ "SPN" SG_ 2566759678 EnggmntCnsntTrnsfrCsOtptShftPTO 3459;
BA_ "SigType" SG_ 2566759678 EnggmntCnsntTrnsfrCsOtptShftPTO 4;
BA_ "SPN" SG_ 2566759678 EnableSwitchTransInputShaftPTO1 3452;
BA_ "SigType" SG_ 2566759678 EnableSwitchTransInputShaftPTO1 4;
BA_ "SPN" SG_ 2566759678 EnableSwitchTransInputShaftPTO2 3453;
BA_ "SigType" SG_ 2566759678 EnableSwitchTransInputShaftPTO2 4;
BA_ "SPN" SG_ 2566759678 EnableSwitchTransOutputShaftPTO 3454;
BA_ "SigType" SG_ 2566759678 EnableSwitchTransOutputShaftPTO 4;
BA_ "SPN" SG_ 2566759678 EnblSwtchTrnsfrCsOutputShaftPTO 3455;
BA_ "SigType" SG_ 2566759678 EnblSwtchTrnsfrCsOutputShaftPTO 4;
BA_ "SPN" SG_ 2566759678 EnggmntSttsPTOEngAccssoryDrive2 3947;
BA_ "SigType" SG_ 2566759678 EnggmntSttsPTOEngAccssoryDrive2 4;
BA_ "SPN" SG_ 2566759678 EnggmntSttsPTOEngAccssoryDrive1 3944;
BA_ "SigType" SG_ 2566759678 EnggmntSttsPTOEngAccssoryDrive1 4;
BA_ "SPN" SG_ 2566759678 EnggmntCnsntPTOEngAccssryDrive2 3946;
BA_ "SigType" SG_ 2566759678 EnggmntCnsntPTOEngAccssryDrive2 4;
BA_ "SPN" SG_ 2566759678 EnggmntCnsntPTOEngAccssryDrive1 3943;
BA_ "SigType" SG_ 2566759678 EnggmntCnsntPTOEngAccssryDrive1 4;
BA_ "SPN" SG_ 2566759678 EngagementStatusPTOEngFlywheel 3941;
BA_ "SigType" SG_ 2566759678 EngagementStatusPTOEngFlywheel 4;
BA_ "SPN" SG_ 2566759678 EngagementConsentPTOEngFlywheel 3940;
BA_ "SigType" SG_ 2566759678 EngagementConsentPTOEngFlywheel 4;
BA_ "SPN" SG_ 2566759678 EnblSwitchPTOEngAccessoryDrive2 3945;
BA_ "SigType" SG_ 2566759678 EnblSwitchPTOEngAccessoryDrive2 4;
BA_ "SPN" SG_ 2566759678 EnblSwitchPTOEngAccessoryDrive1 3942;
BA_ "SigType" SG_ 2566759678 EnblSwitchPTOEngAccessoryDrive1 4;
BA_ "SPN" SG_ 2566759678 EnableSwitchPTOEngFlywheel 3939;
BA_ "SigType" SG_ 2566759678 EnableSwitchPTOEngFlywheel 4;
BA_ "SPN" SG_ 2566759678 AtLeastOnePTOEngaged 3948;
BA_ "SigType" SG_ 2566759678 AtLeastOnePTOEngaged 4;
BA_ "SPN" SG_ 2432541438 EngFuelValve2OutletAbsPress 3469;
BA_ "SigType" SG_ 2432541438 EngFuelValve2OutletAbsPress 1;
BA_ "SPN" SG_ 2432541438 EngFuelTemp2 3468;
BA_ "SigType" SG_ 2432541438 EngFuelTemp2 1;
BA_ "SPN" SG_ 2432541438 EngGas2MassFlowRate 3467;
BA_ "SigType" SG_ 2432541438 EngGas2MassFlowRate 1;
BA_ "SPN" SG_ 2432541438 EngFuelValve2IntakeAbsPress 3466;
BA_ "SigType" SG_ 2432541438 EngFuelValve2IntakeAbsPress 1;
BA_ "SPN" SG_ 2432541694 EngVrableGeometryTurboActuator1 641;
BA_ "SigType" SG_ 2432541694 EngVrableGeometryTurboActuator1 1;
BA_ "SPN" SG_ 2432541694 EngTrbCmprssrBypssActtr1TmpStts 5368;
BA_ "SigType" SG_ 2432541694 EngTrbCmprssrBypssActtr1TmpStts 4;
BA_ "SPN" SG_ 2432541694 EngTrbCmprssrBypssActtr1PrlmnryF 5367;
BA_ "SigType" SG_ 2432541694 EngTrbCmprssrBypssActtr1PrlmnryF 1;
BA_ "SystemSignalLongSymbol" SG_ 2432541694 EngTrbCmprssrBypssActtr1PrlmnryF "EngTrbCmprssrBypssActtr1PrlmnryFMI";
BA_ "SPN" SG_ 2432541694 EngTrbCmprssrBypassActuator2Cmd 5369;
BA_ "SigType" SG_ 2432541694 EngTrbCmprssrBypassActuator2Cmd 1;
BA_ "SPN" SG_ 2432541694 EngTrbCmprssrBypassActuator1Pos 3675;
BA_ "SigType" SG_ 2432541694 EngTrbCmprssrBypassActuator1Pos 1;
BA_ "SPN" SG_ 2432541694 EngTrbCmprssrBypassActuator1Cmd 3470;
BA_ "SigType" SG_ 2432541694 EngTrbCmprssrBypassActuator1Cmd 1;
BA_ "SPN" SG_ 2432541694 EngDsrdTrbCmprssrBypssActtr1Pos 5366;
BA_ "SigType" SG_ 2432541694 EngDsrdTrbCmprssrBypssActtr1Pos 1;
BA_ "SPN" SG_ 2566759934 EnableStatusOfDoor10 3441;
BA_ "SigType" SG_ 2566759934 EnableStatusOfDoor10 4;
BA_ "SPN" SG_ 2566759934 OpenStatusOfDoor10 3440;
BA_ "SigType" SG_ 2566759934 OpenStatusOfDoor10 4;
BA_ "SPN" SG_ 2566759934 LockStatusOfDoor10 3439;
BA_ "SigType" SG_ 2566759934 LockStatusOfDoor10 4;
BA_ "SPN" SG_ 2566759934 EnableStatusOfDoor9 3438;
BA_ "SigType" SG_ 2566759934 EnableStatusOfDoor9 4;
BA_ "SPN" SG_ 2566759934 OpenStatusOfDoor9 3437;
BA_ "SigType" SG_ 2566759934 OpenStatusOfDoor9 4;
BA_ "SPN" SG_ 2566759934 LockStatusOfDoor9 3436;
BA_ "SigType" SG_ 2566759934 LockStatusOfDoor9 4;
BA_ "SPN" SG_ 2566759934 EnableStatusOfDoor8 3435;
BA_ "SigType" SG_ 2566759934 EnableStatusOfDoor8 4;
BA_ "SPN" SG_ 2566759934 OpenStatusOfDoor8 3434;
BA_ "SigType" SG_ 2566759934 OpenStatusOfDoor8 4;
BA_ "SPN" SG_ 2566759934 LockStatusOfDoor8 3433;
BA_ "SigType" SG_ 2566759934 LockStatusOfDoor8 4;
BA_ "SPN" SG_ 2566759934 EnableStatusOfDoor7 3432;
BA_ "SigType" SG_ 2566759934 EnableStatusOfDoor7 4;
BA_ "SPN" SG_ 2566759934 OpenStatusOfDoor7 3431;
BA_ "SigType" SG_ 2566759934 OpenStatusOfDoor7 4;
BA_ "SPN" SG_ 2566759934 LockStatusOfDoor7 3430;
BA_ "SigType" SG_ 2566759934 LockStatusOfDoor7 4;
BA_ "SPN" SG_ 2566759934 EnableStatusOfDoor6 3429;
BA_ "SigType" SG_ 2566759934 EnableStatusOfDoor6 4;
BA_ "SPN" SG_ 2566759934 OpenStatusOfDoor6 3428;
BA_ "SigType" SG_ 2566759934 OpenStatusOfDoor6 4;
BA_ "SPN" SG_ 2566759934 LockStatusOfDoor6 3427;
BA_ "SigType" SG_ 2566759934 LockStatusOfDoor6 4;
BA_ "SPN" SG_ 2566759934 EnableStatusOfDoor5 3426;
BA_ "SigType" SG_ 2566759934 EnableStatusOfDoor5 4;
BA_ "SPN" SG_ 2566759934 OpenStatusOfDoor5 3425;
BA_ "SigType" SG_ 2566759934 OpenStatusOfDoor5 4;
BA_ "SPN" SG_ 2566759934 LockStatusOfDoor5 3424;
BA_ "SigType" SG_ 2566759934 LockStatusOfDoor5 4;
BA_ "SPN" SG_ 2566759934 EnableStatusOfDoor4 3423;
BA_ "SigType" SG_ 2566759934 EnableStatusOfDoor4 4;
BA_ "SPN" SG_ 2566759934 OpenStatusOfDoor4 3422;
BA_ "SigType" SG_ 2566759934 OpenStatusOfDoor4 4;
BA_ "SPN" SG_ 2566759934 LockStatusOfDoor4 3421;
BA_ "SigType" SG_ 2566759934 LockStatusOfDoor4 4;
BA_ "SPN" SG_ 2566759934 EnableStatusOfDoor3 3420;
BA_ "SigType" SG_ 2566759934 EnableStatusOfDoor3 4;
BA_ "SPN" SG_ 2566759934 OpenStatusOfDoor3 3419;
BA_ "SigType" SG_ 2566759934 OpenStatusOfDoor3 4;
BA_ "SPN" SG_ 2566759934 LockStatusOfDoor3 3418;
BA_ "SigType" SG_ 2566759934 LockStatusOfDoor3 4;
BA_ "SPN" SG_ 2566759934 EnableStatusOfDoor2 3417;
BA_ "SigType" SG_ 2566759934 EnableStatusOfDoor2 4;
BA_ "SPN" SG_ 2566759934 OpenStatusOfDoor2 3416;
BA_ "SigType" SG_ 2566759934 OpenStatusOfDoor2 4;
BA_ "SPN" SG_ 2566759934 LockStatusOfDoor2 3415;
BA_ "SigType" SG_ 2566759934 LockStatusOfDoor2 4;
BA_ "SPN" SG_ 2566759934 EnableStatusOfDoor1 3414;
BA_ "SigType" SG_ 2566759934 EnableStatusOfDoor1 4;
BA_ "SPN" SG_ 2566759934 OpenStatusOfDoor1 3413;
BA_ "SigType" SG_ 2566759934 OpenStatusOfDoor1 4;
BA_ "SPN" SG_ 2566759934 LockStatusOfDoor1 3412;
BA_ "SigType" SG_ 2566759934 LockStatusOfDoor1 4;
BA_ "SPN" SG_ 2566757374 Aftrtrtmnt1SCRCtlystRgntTmp2Prlm 3519;
BA_ "SigType" SG_ 2566757374 Aftrtrtmnt1SCRCtlystRgntTmp2Prlm 1;
BA_ "SystemSignalLongSymbol" SG_ 2566757374 Aftrtrtmnt1SCRCtlystRgntTmp2Prlm "Aftrtrtmnt1SCRCtlystRgntTmp2PrlmnryFMI";
BA_ "SPN" SG_ 2566757374 Aftrtrtmnt1SCRCtlystRgntPrprtsPr 3520;
BA_ "SigType" SG_ 2566757374 Aftrtrtmnt1SCRCtlystRgntPrprtsPr 1;
BA_ "SystemSignalLongSymbol" SG_ 2566757374 Aftrtrtmnt1SCRCtlystRgntPrprtsPr "Aftrtrtmnt1SCRCtlystRgntPrprtsPrlmnryFMI";
BA_ "SPN" SG_ 2566757374 Aftrtrtmnt1SCRCtlystRgntCndctvty 3518;
BA_ "SigType" SG_ 2566757374 Aftrtrtmnt1SCRCtlystRgntCndctvty 1;
BA_ "SPN" SG_ 2566757374 Aftrtrtmnt1SCRCtlystRgntCncntrtn 3516;
BA_ "SigType" SG_ 2566757374 Aftrtrtmnt1SCRCtlystRgntCncntrtn 1;
BA_ "SPN" SG_ 2566757374 Aftrtrtmnt1SCRCtlystReagentType 3521;
BA_ "SigType" SG_ 2566757374 Aftrtrtmnt1SCRCtlystReagentType 4;
BA_ "SPN" SG_ 2566757374 Aftrtrtmnt1SCRCtlystRagentTemp2 3515;
BA_ "SigType" SG_ 2566757374 Aftrtrtmnt1SCRCtlystRagentTemp2 1;
BA_ "SPN" SG_ 2431654654 EngThrottleActuator2CtrlCmd 3465;
BA_ "SigType" SG_ 2431654654 EngThrottleActuator2CtrlCmd 1;
BA_ "SPN" SG_ 2431654654 EngThrottleActuator1CtrlCmd 3464;
BA_ "SigType" SG_ 2431654654 EngThrottleActuator1CtrlCmd 1;
BA_ "SPN" SG_ 2431654654 EngFuelActuator2CtrlCmd 1244;
BA_ "SigType" SG_ 2431654654 EngFuelActuator2CtrlCmd 1;
BA_ "SPN" SG_ 2431654654 EngFuelActuator1CtrlCmd 633;
BA_ "SigType" SG_ 2431654654 EngFuelActuator1CtrlCmd 1;
BA_ "SPN" SG_ 2364545534 EngCyl24KnockLevel 1375;
BA_ "SigType" SG_ 2364545534 EngCyl24KnockLevel 1;
BA_ "SPN" SG_ 2364545534 EngCyl23KnockLevel 1374;
BA_ "SigType" SG_ 2364545534 EngCyl23KnockLevel 1;
BA_ "SPN" SG_ 2364545534 EngCyl22KnockLevel 1373;
BA_ "SigType" SG_ 2364545534 EngCyl22KnockLevel 1;
BA_ "SPN" SG_ 2364545534 EngCyl21KnockLevel 1372;
BA_ "SigType" SG_ 2364545534 EngCyl21KnockLevel 1;
BA_ "SPN" SG_ 2364545534 EngCyl20KnockLevel 1371;
BA_ "SigType" SG_ 2364545534 EngCyl20KnockLevel 1;
BA_ "SPN" SG_ 2364545534 EngCyl19KnockLevel 1370;
BA_ "SigType" SG_ 2364545534 EngCyl19KnockLevel 1;
BA_ "SPN" SG_ 2364545534 EngCyl18KnockLevel 1369;
BA_ "SigType" SG_ 2364545534 EngCyl18KnockLevel 1;
BA_ "SPN" SG_ 2364545534 EngCyl17KnockLevel 1368;
BA_ "SigType" SG_ 2364545534 EngCyl17KnockLevel 1;
BA_ "SPN" SG_ 2364545278 EngCyl15KnockLevel 1366;
BA_ "SigType" SG_ 2364545278 EngCyl15KnockLevel 1;
BA_ "SPN" SG_ 2364545278 EngCyl14KnockLevel 1365;
BA_ "SigType" SG_ 2364545278 EngCyl14KnockLevel 1;
BA_ "SPN" SG_ 2364545278 EngCyl13KnockLevel 1364;
BA_ "SigType" SG_ 2364545278 EngCyl13KnockLevel 1;
BA_ "SPN" SG_ 2364545278 EngCyl12KnockLevel 1363;
BA_ "SigType" SG_ 2364545278 EngCyl12KnockLevel 1;
BA_ "SPN" SG_ 2364545278 EngCyl11KnockLevel 1362;
BA_ "SigType" SG_ 2364545278 EngCyl11KnockLevel 1;
BA_ "SPN" SG_ 2364545278 EngCyl10KnockLevel 1361;
BA_ "SigType" SG_ 2364545278 EngCyl10KnockLevel 1;
BA_ "SPN" SG_ 2364545278 EngCyl9KnockLevel 1360;
BA_ "SigType" SG_ 2364545278 EngCyl9KnockLevel 1;
BA_ "SPN" SG_ 2364545278 EngCyl16KnockLevel 1367;
BA_ "SigType" SG_ 2364545278 EngCyl16KnockLevel 1;
BA_ "SPN" SG_ 2364545022 EngCyl8KnockLevel 1359;
BA_ "SigType" SG_ 2364545022 EngCyl8KnockLevel 1;
BA_ "SPN" SG_ 2364545022 EngCyl7KnockLevel 1358;
BA_ "SigType" SG_ 2364545022 EngCyl7KnockLevel 1;
BA_ "SPN" SG_ 2364545022 EngCyl6KnockLevel 1357;
BA_ "SigType" SG_ 2364545022 EngCyl6KnockLevel 1;
BA_ "SPN" SG_ 2364545022 EngCyl5KnockLevel 1356;
BA_ "SigType" SG_ 2364545022 EngCyl5KnockLevel 1;
BA_ "SPN" SG_ 2364545022 EngCyl4KnockLevel 1355;
BA_ "SigType" SG_ 2364545022 EngCyl4KnockLevel 1;
BA_ "SPN" SG_ 2364545022 EngCyl3KnockLevel 1354;
BA_ "SigType" SG_ 2364545022 EngCyl3KnockLevel 1;
BA_ "SPN" SG_ 2364545022 EngCyl2KnockLevel 1353;
BA_ "SigType" SG_ 2364545022 EngCyl2KnockLevel 1;
BA_ "SPN" SG_ 2364545022 EngCyl1KnockLevel 1352;
BA_ "SigType" SG_ 2364545022 EngCyl1KnockLevel 1;
BA_ "SPN" SG_ 2364544766 EngCyl9CombustionStatus 3395;
BA_ "SigType" SG_ 2364544766 EngCyl9CombustionStatus 4;
BA_ "SPN" SG_ 2364544766 EngCyl8CombustionStatus 3394;
BA_ "SigType" SG_ 2364544766 EngCyl8CombustionStatus 4;
BA_ "SPN" SG_ 2364544766 EngCyl7CombustionStatus 3393;
BA_ "SigType" SG_ 2364544766 EngCyl7CombustionStatus 4;
BA_ "SPN" SG_ 2364544766 EngCyl6CombustionStatus 3392;
BA_ "SigType" SG_ 2364544766 EngCyl6CombustionStatus 4;
BA_ "SPN" SG_ 2364544766 EngCyl5CombustionStatus 3391;
BA_ "SigType" SG_ 2364544766 EngCyl5CombustionStatus 4;
BA_ "SPN" SG_ 2364544766 EngCyl4CombustionStatus 3390;
BA_ "SigType" SG_ 2364544766 EngCyl4CombustionStatus 4;
BA_ "SPN" SG_ 2364544766 EngCyl3CombustionStatus 3389;
BA_ "SigType" SG_ 2364544766 EngCyl3CombustionStatus 4;
BA_ "SPN" SG_ 2364544766 EngCyl2CombustionStatus 3388;
BA_ "SigType" SG_ 2364544766 EngCyl2CombustionStatus 4;
BA_ "SPN" SG_ 2364544766 EngCyl24CombustionStatus 3410;
BA_ "SigType" SG_ 2364544766 EngCyl24CombustionStatus 4;
BA_ "SPN" SG_ 2364544766 EngCyl23CombustionStatus 3409;
BA_ "SigType" SG_ 2364544766 EngCyl23CombustionStatus 4;
BA_ "SPN" SG_ 2364544766 EngCyl22CombustionStatus 3408;
BA_ "SigType" SG_ 2364544766 EngCyl22CombustionStatus 4;
BA_ "SPN" SG_ 2364544766 EngCyl21CombustionStatus 3407;
BA_ "SigType" SG_ 2364544766 EngCyl21CombustionStatus 4;
BA_ "SPN" SG_ 2364544766 EngCyl20CombustionStatus 3406;
BA_ "SigType" SG_ 2364544766 EngCyl20CombustionStatus 4;
BA_ "SPN" SG_ 2364544766 EngCyl1CombustionStatus 3387;
BA_ "SigType" SG_ 2364544766 EngCyl1CombustionStatus 4;
BA_ "SPN" SG_ 2364544766 EngCyl19CombustionStatus 3405;
BA_ "SigType" SG_ 2364544766 EngCyl19CombustionStatus 4;
BA_ "SPN" SG_ 2364544766 EngCyl18CombustionStatus 3404;
BA_ "SigType" SG_ 2364544766 EngCyl18CombustionStatus 4;
BA_ "SPN" SG_ 2364544766 EngCyl17CombustionStatus 3403;
BA_ "SigType" SG_ 2364544766 EngCyl17CombustionStatus 4;
BA_ "SPN" SG_ 2364544766 EngCyl16CombustionStatus 3402;
BA_ "SigType" SG_ 2364544766 EngCyl16CombustionStatus 4;
BA_ "SPN" SG_ 2364544766 EngCyl15CombustionStatus 3401;
BA_ "SigType" SG_ 2364544766 EngCyl15CombustionStatus 4;
BA_ "SPN" SG_ 2364544766 EngCyl14CombustionStatus 3400;
BA_ "SigType" SG_ 2364544766 EngCyl14CombustionStatus 4;
BA_ "SPN" SG_ 2364544766 EngCyl13CombustionStatus 3399;
BA_ "SigType" SG_ 2364544766 EngCyl13CombustionStatus 4;
BA_ "SPN" SG_ 2364544766 EngCyl12CombustionStatus 3398;
BA_ "SigType" SG_ 2364544766 EngCyl12CombustionStatus 4;
BA_ "SPN" SG_ 2364544766 EngCyl11CombustionStatus 3397;
BA_ "SigType" SG_ 2364544766 EngCyl11CombustionStatus 4;
BA_ "SPN" SG_ 2364544766 EngCyl10CombustionStatus 3396;
BA_ "SigType" SG_ 2364544766 EngCyl10CombustionStatus 4;
BA_ "SPN" SG_ 2364544254 RltvBldHghtAndBldRttnAnglMsrmntL 3366;
BA_ "SigType" SG_ 2364544254 RltvBldHghtAndBldRttnAnglMsrmntL 1;
BA_ "SystemSignalLongSymbol" SG_ 2364544254 RltvBldHghtAndBldRttnAnglMsrmntL "RltvBldHghtAndBldRttnAnglMsrmntLtncy";
BA_ "SPN" SG_ 2364544254 RlativeBladeHeightFigureOfMerit 3367;
BA_ "SigType" SG_ 2364544254 RlativeBladeHeightFigureOfMerit 4;
BA_ "SPN" SG_ 2364544254 BladeRotationAngleFigureOfMerit 3332;
BA_ "SigType" SG_ 2364544254 BladeRotationAngleFigureOfMerit 4;
BA_ "SPN" SG_ 2364544254 BladeRotationAngle 3331;
BA_ "SigType" SG_ 2364544254 BladeRotationAngle 1;
BA_ "SPN" SG_ 2364544254 RelativeBladeHeight 3365;
BA_ "SigType" SG_ 2364544254 RelativeBladeHeight 1;
BA_ "SPN" SG_ 2349137662 XBRMessageChecksum 3188;
BA_ "SigType" SG_ 2349137662 XBRMessageChecksum 4;
BA_ "SPN" SG_ 2349137662 XBRMessageCounter 3189;
BA_ "SigType" SG_ 2349137662 XBRMessageCounter 4;
BA_ "SPN" SG_ 2349137662 XBRCtrlMode 2916;
BA_ "SigType" SG_ 2349137662 XBRCtrlMode 4;
BA_ "SPN" SG_ 2349137662 XBRPriority 2915;
BA_ "SigType" SG_ 2349137662 XBRPriority 4;
BA_ "SPN" SG_ 2349137662 XBREBIMode 2914;
BA_ "SigType" SG_ 2349137662 XBREBIMode 4;
BA_ "SPN" SG_ 2349137662 ExtlAccelerationDemand 2920;
BA_ "SigType" SG_ 2349137662 ExtlAccelerationDemand 1;
BA_ "SPN" SG_ 2349137662 XBRUrgency 4099;
BA_ "SigType" SG_ 2349137662 XBRUrgency 1;
BA_ "SPN" SG_ 2566848510 WaterInFuelIndicator 97;
BA_ "SigType" SG_ 2566848510 WaterInFuelIndicator 4;
BA_ "SPN" SG_ 2566843134 AxleLocation 928;
BA_ "SigType" SG_ 2566843134 AxleLocation 1;
BA_ "SPN" SG_ 2566843134 CargoWeight_30 522230;
BA_ "SigType" SG_ 2566843134 CargoWeight_30 1;
BA_ "SPN" SG_ 2566843134 CargoWeight_20 522220;
BA_ "SigType" SG_ 2566843134 CargoWeight_20 1;
BA_ "SPN" SG_ 2566843134 CargoWeight_10 522210;
BA_ "SigType" SG_ 2566843134 CargoWeight_10 1;
BA_ "SPN" SG_ 2566843134 CargoWeight_00 522200;
BA_ "SigType" SG_ 2566843134 CargoWeight_00 1;
BA_ "SPN" SG_ 2566843134 TrailerWeight_30 522130;
BA_ "SigType" SG_ 2566843134 TrailerWeight_30 1;
BA_ "SPN" SG_ 2566843134 TrailerWeight_20 522120;
BA_ "SigType" SG_ 2566843134 TrailerWeight_20 1;
BA_ "SPN" SG_ 2566843134 TrailerWeight_10 522110;
BA_ "SigType" SG_ 2566843134 TrailerWeight_10 1;
BA_ "SPN" SG_ 2566843134 TrailerWeight_00 522100;
BA_ "SigType" SG_ 2566843134 TrailerWeight_00 1;
BA_ "SPN" SG_ 2566843134 AxleWeight_30 522030;
BA_ "SigType" SG_ 2566843134 AxleWeight_30 1;
BA_ "SPN" SG_ 2566843134 AxleWeight_20 522020;
BA_ "SigType" SG_ 2566843134 AxleWeight_20 1;
BA_ "SPN" SG_ 2566843134 AxleWeight_10 522010;
BA_ "SigType" SG_ 2566843134 AxleWeight_10 1;
BA_ "SPN" SG_ 2566843134 AxleWeight_00 522000;
BA_ "SigType" SG_ 2566843134 AxleWeight_00 1;
BA_ "SPN" SG_ 2566804222 NetBatteryCurrentHiRes 2579;
BA_ "SigType" SG_ 2566804222 NetBatteryCurrentHiRes 1;
BA_ "SPN" SG_ 2566804222 AltCurrentHiRes 1795;
BA_ "SigType" SG_ 2566804222 AltCurrentHiRes 1;
BA_ "SPN" SG_ 2633928190 ECUPowerOutputSupplyVoltage3 3599;
BA_ "SigType" SG_ 2633928190 ECUPowerOutputSupplyVoltage3 1;
BA_ "SPN" SG_ 2633928190 ECUPowerOutputSupplyVoltage2 3598;
BA_ "SigType" SG_ 2633928190 ECUPowerOutputSupplyVoltage2 1;
BA_ "SPN" SG_ 2633928190 ECUPowerOutputSupplyVoltage1 3597;
BA_ "SigType" SG_ 2633928190 ECUPowerOutputSupplyVoltage1 1;
BA_ "SPN" SG_ 2633928190 BatteryPotential_PowerInput2 444;
BA_ "SigType" SG_ 2633928190 BatteryPotential_PowerInput2 1;
BA_ "SPN" SG_ 2566845438 Longitude 585;
BA_ "SigType" SG_ 2566845438 Longitude 1;
BA_ "SPN" SG_ 2566845438 Latitude 584;
BA_ "SigType" SG_ 2566845438 Latitude 1;
BA_ "SPN" SG_ 2566843646 VehicleIdentificationNumber 237;
BA_ "SigType" SG_ 2566843646 VehicleIdentificationNumber 8;
BA_ "SPN" SG_ 2566842366 TotalPowerTakeoffHours 248;
BA_ "SigType" SG_ 2566842366 TotalPowerTakeoffHours 1;
BA_ "SPN" SG_ 2566842366 TotalVehicleHours 246;
BA_ "SigType" SG_ 2566842366 TotalVehicleHours 1;
BA_ "SPN" SG_ 2566809854 WinchOilPressSwitch 1857;
BA_ "SigType" SG_ 2566809854 WinchOilPressSwitch 4;
BA_ "SPN" SG_ 2566809854 HydOilLevel 2602;
BA_ "SigType" SG_ 2566809854 HydOilLevel 1;
BA_ "SPN" SG_ 2566809854 HydOilFilterRestrictionSwitch 1713;
BA_ "SigType" SG_ 2566809854 HydOilFilterRestrictionSwitch 4;
BA_ "SPN" SG_ 2566809854 HydTemp 1638;
BA_ "SigType" SG_ 2566809854 HydTemp 1;
BA_ "SPN" SG_ 2566842622 Altitude 580;
BA_ "SigType" SG_ 2566842622 Altitude 1;
BA_ "SPN" SG_ 2566842622 Pitch 583;
BA_ "SigType" SG_ 2566842622 Pitch 1;
BA_ "SPN" SG_ 2566842622 NavigationBasedVehicleSpeed 517;
BA_ "SigType" SG_ 2566842622 NavigationBasedVehicleSpeed 1;
BA_ "SPN" SG_ 2566842622 CompassBearing 165;
BA_ "SigType" SG_ 2566842622 CompassBearing 1;
BA_ "SPN" SG_ 2566832638 HighResolutionTripDistance 918;
BA_ "SigType" SG_ 2566832638 HighResolutionTripDistance 1;
BA_ "SPN" SG_ 2566832638 HghRslutionTotalVehicleDistance 917;
BA_ "SigType" SG_ 2566832638 HghRslutionTotalVehicleDistance 1;
BA_ "SPN" SG_ 2565868030 SteerWheelAngle 1807;
BA_ "SigType" SG_ 2565868030 SteerWheelAngle 1;
BA_ "SPN" SG_ 2565868030 LongitudinalAcceleration 1810;
BA_ "SigType" SG_ 2565868030 LongitudinalAcceleration 1;
BA_ "SPN" SG_ 2565868030 LateralAcceleration 1809;
BA_ "SigType" SG_ 2565868030 LateralAcceleration 1;
BA_ "SPN" SG_ 2565868030 YawRate 1808;
BA_ "SigType" SG_ 2565868030 YawRate 1;
BA_ "SPN" SG_ 2565868030 SteerWheelAngleSensorType 1812;
BA_ "SigType" SG_ 2565868030 SteerWheelAngleSensorType 4;
BA_ "SPN" SG_ 2565868030 SteerWheelTurnCounter 1811;
BA_ "SPN" SG_ 2566803454 YCBrakeCtrlActive 1819;
BA_ "SigType" SG_ 2566803454 YCBrakeCtrlActive 4;
BA_ "SPN" SG_ 2566803454 YCEngCtrlActive 1817;
BA_ "SigType" SG_ 2566803454 YCEngCtrlActive 4;
BA_ "SPN" SG_ 2566803454 ROPBrakeCtrlActive 1818;
BA_ "SigType" SG_ 2566803454 ROPBrakeCtrlActive 4;
BA_ "SPN" SG_ 2566803454 ROPEngCtrlActive 1816;
BA_ "SigType" SG_ 2566803454 ROPEngCtrlActive 4;
BA_ "SPN" SG_ 2566803454 VDCBrakeLightRq 1815;
BA_ "SigType" SG_ 2566803454 VDCBrakeLightRq 4;
BA_ "SPN" SG_ 2566803454 VDCFullyOperational 1814;
BA_ "SigType" SG_ 2566803454 VDCFullyOperational 4;
BA_ "SPN" SG_ 2566803454 VDCInformationSignal 1813;
BA_ "SigType" SG_ 2566803454 VDCInformationSignal 4;
BA_ "SPN" SG_ 2566840574 TotalVehicleDistance 245;
BA_ "SigType" SG_ 2566840574 TotalVehicleDistance 1;
BA_ "SPN" SG_ 2566840574 TripDistance 244;
BA_ "SigType" SG_ 2566840574 TripDistance 1;
BA_ "SPN" SG_ 2633938686 TripCruiseDistance 1019;
BA_ "SigType" SG_ 2633938686 TripCruiseDistance 1;
BA_ "SPN" SG_ 2633938686 TripMaxVehicleSpeed 1018;
BA_ "SigType" SG_ 2633938686 TripMaxVehicleSpeed 1;
BA_ "SPN" SG_ 2633937150 TripAirCompressorOnTime 1038;
BA_ "SigType" SG_ 2633937150 TripAirCompressorOnTime 1;
BA_ "SPN" SG_ 2633937150 TripIdleTime 1037;
BA_ "SigType" SG_ 2633937150 TripIdleTime 1;
BA_ "SPN" SG_ 2633937150 TripEngRunningTime 1036;
BA_ "SigType" SG_ 2633937150 TripEngRunningTime 1;
BA_ "SPN" SG_ 2633937150 TripCruiseTime 1034;
BA_ "SigType" SG_ 2633937150 TripCruiseTime 1;
BA_ "SPN" SG_ 2633937150 TripPTOGovernorTime 1035;
BA_ "SigType" SG_ 2633937150 TripPTOGovernorTime 1;
BA_ "SPN" SG_ 2633938174 TripTimeInDerateByEng 1027;
BA_ "SigType" SG_ 2633938174 TripTimeInDerateByEng 1;
BA_ "SPN" SG_ 2633938174 TripTimeInGearDown 1026;
BA_ "SigType" SG_ 2633938174 TripTimeInGearDown 1;
BA_ "SPN" SG_ 2633938174 TripTimeInTopGear 1025;
BA_ "SigType" SG_ 2633938174 TripTimeInTopGear 1;
BA_ "SPN" SG_ 2633938174 TripTimeInVSL 1024;
BA_ "SigType" SG_ 2633938174 TripTimeInVSL 1;
BA_ "SPN" SG_ 2633938430 TripSuddenDecelerations 1023;
BA_ "SigType" SG_ 2633938430 TripSuddenDecelerations 1;
BA_ "SPN" SG_ 2633938430 TrpNmberOfIdleShutdownOverrides 1022;
BA_ "SigType" SG_ 2633938430 TrpNmberOfIdleShutdownOverrides 1;
BA_ "SPN" SG_ 2633938430 TripNumberOfIdleShutdowns 1021;
BA_ "SigType" SG_ 2633938430 TripNumberOfIdleShutdowns 1;
BA_ "SPN" SG_ 2633938430 TripNumberOfHotShutdowns 1020;
BA_ "SigType" SG_ 2633938430 TripNumberOfHotShutdowns 1;
BA_ "SPN" SG_ 2348875518 MessageCounter 4206;
BA_ "SPN" SG_ 2348875518 ControlPurpose 3350;
BA_ "SPN" SG_ 2348875518 TransmissionRate 3349;
BA_ "SPN" SG_ 2348875518 EngRqedTorque_TorqueLimit 518;
BA_ "SigType" SG_ 2348875518 EngRqedTorque_TorqueLimit 1;
BA_ "SPN" SG_ 2348875518 EngRqedSpeed_SpeedLimit 898;
BA_ "SigType" SG_ 2348875518 EngRqedSpeed_SpeedLimit 1;
BA_ "SPN" SG_ 2348875518 OverrideCtrlModePriority 897;
BA_ "SPN" SG_ 2348875518 EngRqedSpeedCtrlConditions 696;
BA_ "SPN" SG_ 2348875518 EngOverrideCtrlMode 695;
BA_ "SPN" SG_ 2348875518 MessageChecksum 4207;
BA_ "SPN" SG_ 2348875518 EngineRequestedTorqueHiRes 4191;
BA_ "SPN" SG_ 2566766846 TransitRunStatus 3046;
BA_ "SigType" SG_ 2566766846 TransitRunStatus 4;
BA_ "SPN" SG_ 2566766846 VehicleUseStatus 3045;
BA_ "SigType" SG_ 2566766846 VehicleUseStatus 4;
BA_ "SPN" SG_ 2566766846 SilentAlarmStatus 3044;
BA_ "SigType" SG_ 2566766846 SilentAlarmStatus 4;
BA_ "SPN" SG_ 2566766846 PatronCount 3047;
BA_ "SigType" SG_ 2566766846 PatronCount 1;
BA_ "SPN" SG_ 2566766846 TypeOfPassengerCount 3043;
BA_ "SigType" SG_ 2566766846 TypeOfPassengerCount 1;
BA_ "SPN" SG_ 2566765310 FareboxAlarmIdentifier 3181;
BA_ "SPN" SG_ 2566765310 FareboxEmergencyStatus 3179;
BA_ "SigType" SG_ 2566765310 FareboxEmergencyStatus 4;
BA_ "SPN" SG_ 2566765566 TransferSold 3168;
BA_ "SigType" SG_ 2566765566 TransferSold 1;
BA_ "SPN" SG_ 2566765566 RouteNumber 3169;
BA_ "SigType" SG_ 2566765566 RouteNumber 1;
BA_ "SPN" SG_ 2566765566 TransferType 3173;
BA_ "SPN" SG_ 2566765566 TypeOfService 3172;
BA_ "SPN" SG_ 2566765566 InitialFareAgency 3167;
BA_ "SPN" SG_ 2566765566 PassCategory 3166;
BA_ "SigType" SG_ 2566765566 PassCategory 4;
BA_ "SPN" SG_ 2566765566 FareValidity 3165;
BA_ "SigType" SG_ 2566765566 FareValidity 4;
BA_ "SPN" SG_ 2566765566 PaymentDetails 3177;
BA_ "SigType" SG_ 2566765566 PaymentDetails 4;
BA_ "SPN" SG_ 2566765566 TypeOfFare 3176;
BA_ "SigType" SG_ 2566765566 TypeOfFare 4;
BA_ "SPN" SG_ 2566765566 PassengerType 3171;
BA_ "SigType" SG_ 2566765566 PassengerType 4;
BA_ "SPN" SG_ 2566765566 TransactionType 3170;
BA_ "SigType" SG_ 2566765566 TransactionType 4;
BA_ "SPN" SG_ 2566765822 DriversFareboxSecurityCode 3164;
BA_ "SigType" SG_ 2566765822 DriversFareboxSecurityCode 1;
BA_ "SPN" SG_ 2566765822 AssignedBlock 3163;
BA_ "SigType" SG_ 2566765822 AssignedBlock 1;
BA_ "SPN" SG_ 2566765822 AssignedRun 3162;
BA_ "SigType" SG_ 2566765822 AssignedRun 1;
BA_ "SPN" SG_ 2566765822 AssignedRoute 3160;
BA_ "SigType" SG_ 2566765822 AssignedRoute 1;
BA_ "SPN" SG_ 2566765822 PatternNumber 3161;
BA_ "SigType" SG_ 2566765822 PatternNumber 1;
BA_ "SPN" SG_ 2566765822 TripNumber 3159;
BA_ "SigType" SG_ 2566765822 TripNumber 1;
BA_ "SPN" SG_ 2566765822 FarePresets 3175;
BA_ "SigType" SG_ 2566765822 FarePresets 1;
BA_ "SPN" SG_ 2566765822 TripDirection 3174;
BA_ "SigType" SG_ 2566765822 TripDirection 4;
BA_ "SPN" SG_ 2566765822 TripStatus 3180;
BA_ "SPN" SG_ 2566765822 FareboxServiceStatus 3178;
BA_ "SigType" SG_ 2566765822 FareboxServiceStatus 4;
BA_ "SPN" SG_ 2566766078 VehicleID 3085;
BA_ "SigType" SG_ 2566766078 VehicleID 1;
BA_ "SPN" SG_ 2566766078 StrobeActivationCtrlStatus 3082;
BA_ "SigType" SG_ 2566766078 StrobeActivationCtrlStatus 4;
BA_ "SPN" SG_ 2566766078 TransitDoorEnable 3083;
BA_ "SigType" SG_ 2566766078 TransitDoorEnable 4;
BA_ "SPN" SG_ 2566766078 PriorityOfRespSentByEmitter 3084;
BA_ "SigType" SG_ 2566766078 PriorityOfRespSentByEmitter 4;
BA_ "SPN" SG_ 2566766078 IntersectionPreemptionRq_Resp 3079;
BA_ "SigType" SG_ 2566766078 IntersectionPreemptionRq_Resp 4;
BA_ "SPN" SG_ 2566766078 TransitRouteIDUsage 3080;
BA_ "SigType" SG_ 2566766078 TransitRouteIDUsage 4;
BA_ "SPN" SG_ 2566766078 RangeCodeEnable 3081;
BA_ "SigType" SG_ 2566766078 RangeCodeEnable 4;
BA_ "SPN" SG_ 2566766590 NmbrOfBytsInMlpstIdentification 3070;
BA_ "SigType" SG_ 2566766590 NmbrOfBytsInMlpstIdentification 1;
BA_ "SPN" SG_ 2566766334 Agency 3078;
BA_ "SigType" SG_ 2566766334 Agency 1;
BA_ "SPN" SG_ 2566766334 NmbrOfBytsInTrnstAssgndBlckIdntt 3073;
BA_ "SigType" SG_ 2566766334 NmbrOfBytsInTrnstAssgndBlckIdntt 1;
BA_ "SystemSignalLongSymbol" SG_ 2566766334 NmbrOfBytsInTrnstAssgndBlckIdntt "NmbrOfBytsInTrnstAssgndBlckIdntty";
BA_ "SPN" SG_ 2566766334 NmbrOfBytsInTrnstAssgndRnIdntty 3072;
BA_ "SigType" SG_ 2566766334 NmbrOfBytsInTrnstAssgndRnIdntty 1;
BA_ "SPN" SG_ 2566766334 NmbrOfBytsInTrnstAssgndRtIdntty 3071;
BA_ "SigType" SG_ 2566766334 NmbrOfBytsInTrnstAssgndRtIdntty 1;
BA_ "SPN" SG_ 2561605374 ReferenceTirePressSetting_33 521833;
BA_ "SigType" SG_ 2561605374 ReferenceTirePressSetting_33 1;
BA_ "SPN" SG_ 2561605374 ReferenceTirePressSetting_32 521832;
BA_ "SigType" SG_ 2561605374 ReferenceTirePressSetting_32 1;
BA_ "SPN" SG_ 2561605374 ReferenceTirePressSetting_31 521831;
BA_ "SigType" SG_ 2561605374 ReferenceTirePressSetting_31 1;
BA_ "SPN" SG_ 2561605374 ReferenceTirePressSetting_30 521830;
BA_ "SigType" SG_ 2561605374 ReferenceTirePressSetting_30 1;
BA_ "SPN" SG_ 2561605374 ReferenceTirePressSetting_23 521823;
BA_ "SigType" SG_ 2561605374 ReferenceTirePressSetting_23 1;
BA_ "SPN" SG_ 2561605374 ReferenceTirePressSetting_22 521822;
BA_ "SigType" SG_ 2561605374 ReferenceTirePressSetting_22 1;
BA_ "SPN" SG_ 2561605374 ReferenceTirePressSetting_21 521821;
BA_ "SigType" SG_ 2561605374 ReferenceTirePressSetting_21 1;
BA_ "SPN" SG_ 2561605374 ReferenceTirePressSetting_20 521820;
BA_ "SigType" SG_ 2561605374 ReferenceTirePressSetting_20 1;
BA_ "SPN" SG_ 2561605374 ReferenceTirePressSetting_13 521813;
BA_ "SigType" SG_ 2561605374 ReferenceTirePressSetting_13 1;
BA_ "SPN" SG_ 2561605374 ReferenceTirePressSetting_12 521812;
BA_ "SigType" SG_ 2561605374 ReferenceTirePressSetting_12 1;
BA_ "SPN" SG_ 2561605374 ReferenceTirePressSetting_11 521811;
BA_ "SigType" SG_ 2561605374 ReferenceTirePressSetting_11 1;
BA_ "SPN" SG_ 2561605374 ReferenceTirePressSetting_10 521810;
BA_ "SigType" SG_ 2561605374 ReferenceTirePressSetting_10 1;
BA_ "SPN" SG_ 2561605374 ReferenceTirePressSetting_01 521801;
BA_ "SigType" SG_ 2561605374 ReferenceTirePressSetting_01 1;
BA_ "SPN" SG_ 2561605374 ReferenceTirePressSetting_00 521800;
BA_ "SigType" SG_ 2561605374 ReferenceTirePressSetting_00 1;
BA_ "SPN" SG_ 2561605374 TireLocation 3190;
BA_ "SigType" SG_ 2561605374 TireLocation 1;
BA_ "SPN" SG_ 2566765054 ReferenceTirePress_33 521933;
BA_ "SigType" SG_ 2566765054 ReferenceTirePress_33 1;
BA_ "SPN" SG_ 2566765054 ReferenceTirePress_32 521932;
BA_ "SigType" SG_ 2566765054 ReferenceTirePress_32 1;
BA_ "SPN" SG_ 2566765054 ReferenceTirePress_31 521931;
BA_ "SigType" SG_ 2566765054 ReferenceTirePress_31 1;
BA_ "SPN" SG_ 2566765054 ReferenceTirePress_30 521930;
BA_ "SigType" SG_ 2566765054 ReferenceTirePress_30 1;
BA_ "SPN" SG_ 2566765054 ReferenceTirePress_23 521923;
BA_ "SigType" SG_ 2566765054 ReferenceTirePress_23 1;
BA_ "SPN" SG_ 2566765054 ReferenceTirePress_22 521922;
BA_ "SigType" SG_ 2566765054 ReferenceTirePress_22 1;
BA_ "SPN" SG_ 2566765054 ReferenceTirePress_21 521921;
BA_ "SigType" SG_ 2566765054 ReferenceTirePress_21 1;
BA_ "SPN" SG_ 2566765054 ReferenceTirePress_20 521920;
BA_ "SigType" SG_ 2566765054 ReferenceTirePress_20 1;
BA_ "SPN" SG_ 2566765054 ReferenceTirePress_13 521913;
BA_ "SigType" SG_ 2566765054 ReferenceTirePress_13 1;
BA_ "SPN" SG_ 2566765054 ReferenceTirePress_12 521912;
BA_ "SigType" SG_ 2566765054 ReferenceTirePress_12 1;
BA_ "SPN" SG_ 2566765054 ReferenceTirePress_11 521911;
BA_ "SigType" SG_ 2566765054 ReferenceTirePress_11 1;
BA_ "SPN" SG_ 2566765054 ReferenceTirePress_10 521910;
BA_ "SigType" SG_ 2566765054 ReferenceTirePress_10 1;
BA_ "SPN" SG_ 2566765054 ReferenceTirePress_01 521901;
BA_ "SigType" SG_ 2566765054 ReferenceTirePress_01 1;
BA_ "SPN" SG_ 2566765054 ReferenceTirePress_00 521900;
BA_ "SigType" SG_ 2566765054 ReferenceTirePress_00 1;
BA_ "SPN" SG_ 2566765054 TireLocation 3190;
BA_ "SigType" SG_ 2566765054 TireLocation 1;
BA_ "SPN" SG_ 2633923326 SteerChannelTirePress 146;
BA_ "SigType" SG_ 2633923326 SteerChannelTirePress 1;
BA_ "SPN" SG_ 2633923326 DriveChannelTirePress 145;
BA_ "SigType" SG_ 2633923326 DriveChannelTirePress 1;
BA_ "SPN" SG_ 2633923326 TrailerTagPushChannelTirePress 144;
BA_ "SigType" SG_ 2633923326 TrailerTagPushChannelTirePress 1;
BA_ "SPN" SG_ 2633923070 SteerChannelTirePressTarget 143;
BA_ "SigType" SG_ 2633923070 SteerChannelTirePressTarget 1;
BA_ "SPN" SG_ 2633923070 DriveChannelTirePressTarget 142;
BA_ "SigType" SG_ 2633923070 DriveChannelTirePressTarget 1;
BA_ "SPN" SG_ 2633923070 TrlrTgPshChannelTirePressTarget 141;
BA_ "SigType" SG_ 2633923070 TrlrTgPshChannelTirePressTarget 1;
BA_ "SPN" SG_ 2633922814 PCUSupplySolenoidStatus 1474;
BA_ "SigType" SG_ 2633922814 PCUSupplySolenoidStatus 4;
BA_ "SPN" SG_ 2633922814 PCUCtrlSolenoidStatus 1473;
BA_ "SigType" SG_ 2633922814 PCUCtrlSolenoidStatus 4;
BA_ "SPN" SG_ 2633922814 PCUDeflateSolenoidStatus 1472;
BA_ "SigType" SG_ 2633922814 PCUDeflateSolenoidStatus 4;
BA_ "SPN" SG_ 2633922814 TirePressSupplySwitchStatus 1471;
BA_ "SigType" SG_ 2633922814 TirePressSupplySwitchStatus 4;
BA_ "SPN" SG_ 2633922814 PCUSteerSolenoidStatus 1470;
BA_ "SigType" SG_ 2633922814 PCUSteerSolenoidStatus 4;
BA_ "SPN" SG_ 2633922814 PCUDriveSolenoidStatus 1469;
BA_ "SigType" SG_ 2633922814 PCUDriveSolenoidStatus 4;
BA_ "SPN" SG_ 2633922814 DriveChannelMode 1468;
BA_ "SigType" SG_ 2633922814 DriveChannelMode 4;
BA_ "SPN" SG_ 2633922814 Trailer_TagChannelMode 1467;
BA_ "SigType" SG_ 2633922814 Trailer_TagChannelMode 4;
BA_ "SPN" SG_ 2633922814 SteerChannelMode 1466;
BA_ "SigType" SG_ 2633922814 SteerChannelMode 4;
BA_ "SPN" SG_ 2633922814 TirePressCheckInterval 39;
BA_ "SigType" SG_ 2633922814 TirePressCheckInterval 1;
BA_ "SPN" SG_ 2633922814 PCUTrailerTagPushSolenoidStatus 1475;
BA_ "SigType" SG_ 2633922814 PCUTrailerTagPushSolenoidStatus 4;
BA_ "SPN" SG_ 2566845694 TirePressThresholdDetection_13 521613;
BA_ "SPN" SG_ 2566845694 TirePressThresholdDetection_12 521612;
BA_ "SPN" SG_ 2566845694 TirePressThresholdDetection_11 521611;
BA_ "SPN" SG_ 2566845694 TirePressThresholdDetection_10 521610;
BA_ "SPN" SG_ 2566845694 TirePressThresholdDetection_01 521601;
BA_ "SPN" SG_ 2566845694 TirePress_33 521033;
BA_ "SigType" SG_ 2566845694 TirePress_33 1;
BA_ "SPN" SG_ 2566845694 TirePress_32 521032;
BA_ "SigType" SG_ 2566845694 TirePress_32 1;
BA_ "SPN" SG_ 2566845694 TirePress_31 521031;
BA_ "SigType" SG_ 2566845694 TirePress_31 1;
BA_ "SPN" SG_ 2566845694 TirePress_30 521030;
BA_ "SigType" SG_ 2566845694 TirePress_30 1;
BA_ "SPN" SG_ 2566845694 TirePress_23 521023;
BA_ "SigType" SG_ 2566845694 TirePress_23 1;
BA_ "SPN" SG_ 2566845694 TirePress_22 521022;
BA_ "SigType" SG_ 2566845694 TirePress_22 1;
BA_ "SPN" SG_ 2566845694 TirePress_21 521021;
BA_ "SigType" SG_ 2566845694 TirePress_21 1;
BA_ "SPN" SG_ 2566845694 TirePress_20 521020;
BA_ "SigType" SG_ 2566845694 TirePress_20 1;
BA_ "SPN" SG_ 2566845694 TirePress_13 521013;
BA_ "SigType" SG_ 2566845694 TirePress_13 1;
BA_ "SPN" SG_ 2566845694 TirePress_12 521012;
BA_ "SigType" SG_ 2566845694 TirePress_12 1;
BA_ "SPN" SG_ 2566845694 TirePress_11 521011;
BA_ "SigType" SG_ 2566845694 TirePress_11 1;
BA_ "SPN" SG_ 2566845694 TirePress_10 521010;
BA_ "SigType" SG_ 2566845694 TirePress_10 1;
BA_ "SPN" SG_ 2566845694 TireAirLeakageRate_33 521533;
BA_ "SigType" SG_ 2566845694 TireAirLeakageRate_33 1;
BA_ "SPN" SG_ 2566845694 TireAirLeakageRate_32 521532;
BA_ "SigType" SG_ 2566845694 TireAirLeakageRate_32 1;
BA_ "SPN" SG_ 2566845694 TireAirLeakageRate_31 521531;
BA_ "SigType" SG_ 2566845694 TireAirLeakageRate_31 1;
BA_ "SPN" SG_ 2566845694 TireAirLeakageRate_30 521530;
BA_ "SigType" SG_ 2566845694 TireAirLeakageRate_30 1;
BA_ "SPN" SG_ 2566845694 TireAirLeakageRate_23 521523;
BA_ "SigType" SG_ 2566845694 TireAirLeakageRate_23 1;
BA_ "SPN" SG_ 2566845694 TireAirLeakageRate_22 521522;
BA_ "SigType" SG_ 2566845694 TireAirLeakageRate_22 1;
BA_ "SPN" SG_ 2566845694 TireAirLeakageRate_21 521521;
BA_ "SigType" SG_ 2566845694 TireAirLeakageRate_21 1;
BA_ "SPN" SG_ 2566845694 TireAirLeakageRate_20 521520;
BA_ "SigType" SG_ 2566845694 TireAirLeakageRate_20 1;
BA_ "SPN" SG_ 2566845694 TireAirLeakageRate_13 521513;
BA_ "SigType" SG_ 2566845694 TireAirLeakageRate_13 1;
BA_ "SPN" SG_ 2566845694 TireAirLeakageRate_12 521512;
BA_ "SigType" SG_ 2566845694 TireAirLeakageRate_12 1;
BA_ "SPN" SG_ 2566845694 TireAirLeakageRate_11 521511;
BA_ "SigType" SG_ 2566845694 TireAirLeakageRate_11 1;
BA_ "SPN" SG_ 2566845694 TireAirLeakageRate_10 521510;
BA_ "SigType" SG_ 2566845694 TireAirLeakageRate_10 1;
BA_ "SPN" SG_ 2566845694 TireAirLeakageRate_01 521501;
BA_ "SigType" SG_ 2566845694 TireAirLeakageRate_01 1;
BA_ "SPN" SG_ 2566845694 TireAirLeakageRate_00 521500;
BA_ "SigType" SG_ 2566845694 TireAirLeakageRate_00 1;
BA_ "SPN" SG_ 2566845694 CTIWheelSensorStatus_33 521433;
BA_ "SigType" SG_ 2566845694 CTIWheelSensorStatus_33 4;
BA_ "SPN" SG_ 2566845694 CTIWheelSensorStatus_32 521432;
BA_ "SigType" SG_ 2566845694 CTIWheelSensorStatus_32 4;
BA_ "SPN" SG_ 2566845694 CTIWheelSensorStatus_31 521431;
BA_ "SigType" SG_ 2566845694 CTIWheelSensorStatus_31 4;
BA_ "SPN" SG_ 2566845694 CTIWheelSensorStatus_30 521430;
BA_ "SigType" SG_ 2566845694 CTIWheelSensorStatus_30 4;
BA_ "SPN" SG_ 2566845694 CTIWheelSensorStatus_23 521423;
BA_ "SigType" SG_ 2566845694 CTIWheelSensorStatus_23 4;
BA_ "SPN" SG_ 2566845694 CTIWheelSensorStatus_22 521422;
BA_ "SigType" SG_ 2566845694 CTIWheelSensorStatus_22 4;
BA_ "SPN" SG_ 2566845694 CTIWheelSensorStatus_21 521421;
BA_ "SigType" SG_ 2566845694 CTIWheelSensorStatus_21 4;
BA_ "SPN" SG_ 2566845694 CTIWheelSensorStatus_20 521420;
BA_ "SigType" SG_ 2566845694 CTIWheelSensorStatus_20 4;
BA_ "SPN" SG_ 2566845694 CTIWheelSensorStatus_13 521413;
BA_ "SigType" SG_ 2566845694 CTIWheelSensorStatus_13 4;
BA_ "SPN" SG_ 2566845694 CTIWheelSensorStatus_12 521412;
BA_ "SigType" SG_ 2566845694 CTIWheelSensorStatus_12 4;
BA_ "SPN" SG_ 2566845694 CTIWheelSensorStatus_11 521411;
BA_ "SigType" SG_ 2566845694 CTIWheelSensorStatus_11 4;
BA_ "SPN" SG_ 2566845694 CTIWheelSensorStatus_10 521410;
BA_ "SigType" SG_ 2566845694 CTIWheelSensorStatus_10 4;
BA_ "SPN" SG_ 2566845694 CTIWheelSensorStatus_01 521401;
BA_ "SigType" SG_ 2566845694 CTIWheelSensorStatus_01 4;
BA_ "SPN" SG_ 2566845694 CTIWheelEndElectricalFault_33 521233;
BA_ "SigType" SG_ 2566845694 CTIWheelEndElectricalFault_33 4;
BA_ "SPN" SG_ 2566845694 CTIWheelEndElectricalFault_32 521232;
BA_ "SigType" SG_ 2566845694 CTIWheelEndElectricalFault_32 4;
BA_ "SPN" SG_ 2566845694 CTIWheelEndElectricalFault_31 521231;
BA_ "SigType" SG_ 2566845694 CTIWheelEndElectricalFault_31 4;
BA_ "SPN" SG_ 2566845694 CTIWheelEndElectricalFault_30 521230;
BA_ "SigType" SG_ 2566845694 CTIWheelEndElectricalFault_30 4;
BA_ "SPN" SG_ 2566845694 CTIWheelEndElectricalFault_23 521223;
BA_ "SigType" SG_ 2566845694 CTIWheelEndElectricalFault_23 4;
BA_ "SPN" SG_ 2566845694 CTIWheelEndElectricalFault_22 521222;
BA_ "SigType" SG_ 2566845694 CTIWheelEndElectricalFault_22 4;
BA_ "SPN" SG_ 2566845694 CTIWheelEndElectricalFault_21 521221;
BA_ "SigType" SG_ 2566845694 CTIWheelEndElectricalFault_21 4;
BA_ "SPN" SG_ 2566845694 CTIWheelEndElectricalFault_20 521220;
BA_ "SigType" SG_ 2566845694 CTIWheelEndElectricalFault_20 4;
BA_ "SPN" SG_ 2566845694 CTIWheelEndElectricalFault_13 521213;
BA_ "SigType" SG_ 2566845694 CTIWheelEndElectricalFault_13 4;
BA_ "SPN" SG_ 2566845694 CTIWheelEndElectricalFault_12 521212;
BA_ "SigType" SG_ 2566845694 CTIWheelEndElectricalFault_12 4;
BA_ "SPN" SG_ 2566845694 CTIWheelEndElectricalFault_11 521211;
BA_ "SigType" SG_ 2566845694 CTIWheelEndElectricalFault_11 4;
BA_ "SPN" SG_ 2566845694 CTIWheelEndElectricalFault_10 521210;
BA_ "SigType" SG_ 2566845694 CTIWheelEndElectricalFault_10 4;
BA_ "SPN" SG_ 2566845694 CTIWheelEndElectricalFault_01 521201;
BA_ "SigType" SG_ 2566845694 CTIWheelEndElectricalFault_01 4;
BA_ "SPN" SG_ 2566845694 CTITireStatus_33 521333;
BA_ "SigType" SG_ 2566845694 CTITireStatus_33 4;
BA_ "SPN" SG_ 2566845694 CTITireStatus_32 521332;
BA_ "SigType" SG_ 2566845694 CTITireStatus_32 4;
BA_ "SPN" SG_ 2566845694 CTITireStatus_31 521331;
BA_ "SigType" SG_ 2566845694 CTITireStatus_31 4;
BA_ "SPN" SG_ 2566845694 CTITireStatus_30 521330;
BA_ "SigType" SG_ 2566845694 CTITireStatus_30 4;
BA_ "SPN" SG_ 2566845694 CTITireStatus_23 521323;
BA_ "SigType" SG_ 2566845694 CTITireStatus_23 4;
BA_ "SPN" SG_ 2566845694 CTITireStatus_22 521322;
BA_ "SigType" SG_ 2566845694 CTITireStatus_22 4;
BA_ "SPN" SG_ 2566845694 CTITireStatus_21 521321;
BA_ "SigType" SG_ 2566845694 CTITireStatus_21 4;
BA_ "SPN" SG_ 2566845694 CTITireStatus_20 521320;
BA_ "SigType" SG_ 2566845694 CTITireStatus_20 4;
BA_ "SPN" SG_ 2566845694 CTITireStatus_13 521313;
BA_ "SigType" SG_ 2566845694 CTITireStatus_13 4;
BA_ "SPN" SG_ 2566845694 CTITireStatus_12 521312;
BA_ "SigType" SG_ 2566845694 CTITireStatus_12 4;
BA_ "SPN" SG_ 2566845694 CTITireStatus_11 521311;
BA_ "SigType" SG_ 2566845694 CTITireStatus_11 4;
BA_ "SPN" SG_ 2566845694 CTITireStatus_10 521310;
BA_ "SigType" SG_ 2566845694 CTITireStatus_10 4;
BA_ "SPN" SG_ 2566845694 CTITireStatus_01 521301;
BA_ "SigType" SG_ 2566845694 CTITireStatus_01 4;
BA_ "SPN" SG_ 2566845694 TireTemp_11 521111;
BA_ "SigType" SG_ 2566845694 TireTemp_11 1;
BA_ "SPN" SG_ 2566845694 TireTemp_33 521133;
BA_ "SigType" SG_ 2566845694 TireTemp_33 1;
BA_ "SPN" SG_ 2566845694 TireTemp_32 521132;
BA_ "SigType" SG_ 2566845694 TireTemp_32 1;
BA_ "SPN" SG_ 2566845694 TireTemp_31 521131;
BA_ "SigType" SG_ 2566845694 TireTemp_31 1;
BA_ "SPN" SG_ 2566845694 TireTemp_30 521130;
BA_ "SigType" SG_ 2566845694 TireTemp_30 1;
BA_ "SPN" SG_ 2566845694 TireTemp_23 521123;
BA_ "SigType" SG_ 2566845694 TireTemp_23 1;
BA_ "SPN" SG_ 2566845694 TireTemp_22 521122;
BA_ "SigType" SG_ 2566845694 TireTemp_22 1;
BA_ "SPN" SG_ 2566845694 TireTemp_21 521121;
BA_ "SigType" SG_ 2566845694 TireTemp_21 1;
BA_ "SPN" SG_ 2566845694 TireTemp_20 521120;
BA_ "SigType" SG_ 2566845694 TireTemp_20 1;
BA_ "SPN" SG_ 2566845694 TireTemp_13 521113;
BA_ "SigType" SG_ 2566845694 TireTemp_13 1;
BA_ "SPN" SG_ 2566845694 TireTemp_12 521112;
BA_ "SigType" SG_ 2566845694 TireTemp_12 1;
BA_ "SPN" SG_ 2566845694 TireTemp_10 521110;
BA_ "SigType" SG_ 2566845694 TireTemp_10 1;
BA_ "SPN" SG_ 2566845694 TireTemp_01 521101;
BA_ "SigType" SG_ 2566845694 TireTemp_01 1;
BA_ "SPN" SG_ 2566845694 TireTemp_00 521100;
BA_ "SigType" SG_ 2566845694 TireTemp_00 1;
BA_ "SPN" SG_ 2566845694 TirePressThresholdDetection_33 521633;
BA_ "SPN" SG_ 2566845694 TirePressThresholdDetection_32 521632;
BA_ "SPN" SG_ 2566845694 TirePressThresholdDetection_31 521631;
BA_ "SPN" SG_ 2566845694 TirePressThresholdDetection_30 521630;
BA_ "SPN" SG_ 2566845694 TirePressThresholdDetection_23 521623;
BA_ "SPN" SG_ 2566845694 TirePressThresholdDetection_22 521622;
BA_ "SPN" SG_ 2566845694 TirePressThresholdDetection_21 521621;
BA_ "SPN" SG_ 2566845694 TirePressThresholdDetection_20 521620;
BA_ "SPN" SG_ 2566845694 TirePressThresholdDetection_00 521600;
BA_ "SPN" SG_ 2566845694 TirePress_01 521001;
BA_ "SigType" SG_ 2566845694 TirePress_01 1;
BA_ "SPN" SG_ 2566845694 TirePress_00 521000;
BA_ "SigType" SG_ 2566845694 TirePress_00 1;
BA_ "SPN" SG_ 2566845694 CTIWheelSensorStatus_00 521400;
BA_ "SigType" SG_ 2566845694 CTIWheelSensorStatus_00 4;
BA_ "SPN" SG_ 2566845694 CTIWheelEndElectricalFault_00 521200;
BA_ "SigType" SG_ 2566845694 CTIWheelEndElectricalFault_00 4;
BA_ "SPN" SG_ 2566845694 CTITireStatus_00 521300;
BA_ "SigType" SG_ 2566845694 CTITireStatus_00 4;
BA_ "SPN" SG_ 2566845694 TireLocation 929;
BA_ "SigType" SG_ 2566845694 TireLocation 1;
BA_ "SPN" SG_ 2633939966 TripFanOnTimeDueToAManualSwitch 996;
BA_ "SigType" SG_ 2633939966 TripFanOnTimeDueToAManualSwitch 1;
BA_ "SPN" SG_ 2633939966 TripFanOnTime 994;
BA_ "SigType" SG_ 2633939966 TripFanOnTime 1;
BA_ "SPN" SG_ 2633939966 TripFanOnTimeDueToA_CSystem 997;
BA_ "SigType" SG_ 2633939966 TripFanOnTimeDueToA_CSystem 1;
BA_ "SPN" SG_ 2633939966 TripFanOnTimeDueToEngSystem 995;
BA_ "SigType" SG_ 2633939966 TripFanOnTimeDueToEngSystem 1;
BA_ "SPN" SG_ 2633939710 TripDistanceInTopGear 1000;
BA_ "SigType" SG_ 2633939710 TripDistanceInTopGear 1;
BA_ "SPN" SG_ 2633939710 TripGearDownDistance 999;
BA_ "SigType" SG_ 2633939710 TripGearDownDistance 1;
BA_ "SPN" SG_ 2633939710 TripDistanceOnVSL 998;
BA_ "SigType" SG_ 2633939710 TripDistanceOnVSL 1;
BA_ "SPN" SG_ 2564161278 AdjustLocalHourOffset 1610;
BA_ "SigType" SG_ 2564161278 AdjustLocalHourOffset 1;
BA_ "SPN" SG_ 2564161278 AdjustLocalMinuteOffset 1609;
BA_ "SigType" SG_ 2564161278 AdjustLocalMinuteOffset 1;
BA_ "SPN" SG_ 2564161278 AdjustYear 1608;
BA_ "SigType" SG_ 2564161278 AdjustYear 1;
BA_ "SPN" SG_ 2564161278 AdjustDay 1607;
BA_ "SigType" SG_ 2564161278 AdjustDay 1;
BA_ "SPN" SG_ 2564161278 AdjustMonth 1606;
BA_ "SigType" SG_ 2564161278 AdjustMonth 1;
BA_ "SPN" SG_ 2564161278 AdjustHours 1605;
BA_ "SigType" SG_ 2564161278 AdjustHours 1;
BA_ "SPN" SG_ 2564161278 AdjustMinutes 1604;
BA_ "SigType" SG_ 2564161278 AdjustMinutes 1;
BA_ "SPN" SG_ 2564161278 AdjustSeconds 1603;
BA_ "SigType" SG_ 2564161278 AdjustSeconds 1;
BA_ "SPN" SG_ 2566842110 LocalHourOffset 1602;
BA_ "SigType" SG_ 2566842110 LocalHourOffset 1;
BA_ "SPN" SG_ 2566842110 LocalMinuteOffset 1601;
BA_ "SigType" SG_ 2566842110 LocalMinuteOffset 1;
BA_ "SPN" SG_ 2566842110 Year 964;
BA_ "SigType" SG_ 2566842110 Year 1;
BA_ "SPN" SG_ 2566842110 Day 962;
BA_ "SigType" SG_ 2566842110 Day 1;
BA_ "SPN" SG_ 2566842110 Month 963;
BA_ "SigType" SG_ 2566842110 Month 1;
BA_ "SPN" SG_ 2566842110 Hours 961;
BA_ "SigType" SG_ 2566842110 Hours 1;
BA_ "SPN" SG_ 2566842110 Minutes 960;
BA_ "SigType" SG_ 2566842110 Minutes 1;
BA_ "SPN" SG_ 2566842110 Seconds 959;
BA_ "SigType" SG_ 2566842110 Seconds 1;
BA_ "SPN" SG_ 2566821630 EngTrbWstgteActuator1TempStatus 5372;
BA_ "SigType" SG_ 2566821630 EngTrbWstgteActuator1TempStatus 4;
BA_ "SPN" SG_ 2566821630 EngTrbWstgtActtr1PreliminaryFMI 5371;
BA_ "SigType" SG_ 2566821630 EngTrbWstgtActtr1PreliminaryFMI 1;
BA_ "SPN" SG_ 2566821630 EngDsrdTrbWastegateActuator2Pos 5373;
BA_ "SigType" SG_ 2566821630 EngDsrdTrbWastegateActuator2Pos 1;
BA_ "SPN" SG_ 2566821630 EngDsrdTrbWastegateActuator1Pos 5370;
BA_ "SigType" SG_ 2566821630 EngDsrdTrbWastegateActuator1Pos 1;
BA_ "SPN" SG_ 2566821630 EngTurboWastegateActuator4Pos 1191;
BA_ "SigType" SG_ 2566821630 EngTurboWastegateActuator4Pos 1;
BA_ "SPN" SG_ 2566821630 EngTurboWastegateActuator3Pos 1190;
BA_ "SigType" SG_ 2566821630 EngTurboWastegateActuator3Pos 1;
BA_ "SPN" SG_ 2566821630 EngTurboWastegateActuator2Pos 1189;
BA_ "SigType" SG_ 2566821630 EngTurboWastegateActuator2Pos 1;
BA_ "SPN" SG_ 2566821630 EngTurboWastegateActuator1Pos 1188;
BA_ "SigType" SG_ 2566821630 EngTurboWastegateActuator1Pos 1;
BA_ "SPN" SG_ 2566821630 EngTrbWstgtActuatorCtrlAirPress 1192;
BA_ "SigType" SG_ 2566821630 EngTrbWstgtActuatorCtrlAirPress 1;
BA_ "SPN" SG_ 2365484286 VehicleOverspeed 1614;
BA_ "SigType" SG_ 2365484286 VehicleOverspeed 4;
BA_ "SPN" SG_ 2365484286 VehicleMotion 1611;
BA_ "SigType" SG_ 2365484286 VehicleMotion 4;
BA_ "SPN" SG_ 2365484286 TachographVehicleSpeed 1624;
BA_ "SigType" SG_ 2365484286 TachographVehicleSpeed 1;
BA_ "SPN" SG_ 2365484286 TachographOutputShaftSpeed 1623;
BA_ "SigType" SG_ 2365484286 TachographOutputShaftSpeed 1;
BA_ "SPN" SG_ 2365484286 DirectionIndicator 1619;
BA_ "SigType" SG_ 2365484286 DirectionIndicator 4;
BA_ "SPN" SG_ 2365484286 TachographPerformance 1620;
BA_ "SigType" SG_ 2365484286 TachographPerformance 4;
BA_ "SPN" SG_ 2365484286 HandlingInformation 1621;
BA_ "SigType" SG_ 2365484286 HandlingInformation 4;
BA_ "SPN" SG_ 2365484286 SystemEvent 1622;
BA_ "SigType" SG_ 2365484286 SystemEvent 4;
BA_ "SPN" SG_ 2365484286 DriverCardDriver2 1616;
BA_ "SigType" SG_ 2365484286 DriverCardDriver2 4;
BA_ "SPN" SG_ 2365484286 Driver2TimeRelatedStates 1618;
BA_ "SigType" SG_ 2365484286 Driver2TimeRelatedStates 4;
BA_ "SPN" SG_ 2365484286 DriverCardDriver1 1615;
BA_ "SigType" SG_ 2365484286 DriverCardDriver1 4;
BA_ "SPN" SG_ 2365484286 Driver1TimeRelatedStates 1617;
BA_ "SigType" SG_ 2365484286 Driver1TimeRelatedStates 4;
BA_ "SPN" SG_ 2365484286 Driver2WorkingState 1613;
BA_ "SPN" SG_ 2365484286 Driver1WorkingState 1612;
BA_ "SPN" SG_ 2566771710 EngTurbo4CompressorOutletTemp 2801;
BA_ "SigType" SG_ 2566771710 EngTurbo4CompressorOutletTemp 1;
BA_ "SPN" SG_ 2566771710 EngTurbo3CompressorOutletTemp 2800;
BA_ "SigType" SG_ 2566771710 EngTurbo3CompressorOutletTemp 1;
BA_ "SPN" SG_ 2566771710 EngTurbo2CompressorOutletTemp 2799;
BA_ "SigType" SG_ 2566771710 EngTurbo2CompressorOutletTemp 1;
BA_ "SPN" SG_ 2566771710 EngTurbo1CompressorOutletTemp 2629;
BA_ "SigType" SG_ 2566771710 EngTurbo1CompressorOutletTemp 1;
BA_ "SPN" SG_ 2566821886 EngTurbo4TurbineOutletTemp 1187;
BA_ "SigType" SG_ 2566821886 EngTurbo4TurbineOutletTemp 1;
BA_ "SPN" SG_ 2566821886 EngTurbo3TurbineOutletTemp 1186;
BA_ "SigType" SG_ 2566821886 EngTurbo3TurbineOutletTemp 1;
BA_ "SPN" SG_ 2566821886 EngTurbo2TurbineOutletTemp 1185;
BA_ "SigType" SG_ 2566821886 EngTurbo2TurbineOutletTemp 1;
BA_ "SPN" SG_ 2566821886 EngTurbo1TurbineOutletTemp 1184;
BA_ "SigType" SG_ 2566821886 EngTurbo1TurbineOutletTemp 1;
BA_ "SPN" SG_ 2566822142 EngTurbo4TurbineIntakeTemp 1183;
BA_ "SigType" SG_ 2566822142 EngTurbo4TurbineIntakeTemp 1;
BA_ "SPN" SG_ 2566822142 EngTurbo3TurbineIntakeTemp 1182;
BA_ "SigType" SG_ 2566822142 EngTurbo3TurbineIntakeTemp 1;
BA_ "SPN" SG_ 2566822142 EngTurbo2TurbineIntakeTemp 1181;
BA_ "SigType" SG_ 2566822142 EngTurbo2TurbineIntakeTemp 1;
BA_ "SPN" SG_ 2566822142 EngTurbo1TurbineIntakeTemp 1180;
BA_ "SigType" SG_ 2566822142 EngTurbo1TurbineIntakeTemp 1;
BA_ "SPN" SG_ 2566822398 EngTurbo4CompressorIntakePress 1179;
BA_ "SigType" SG_ 2566822398 EngTurbo4CompressorIntakePress 1;
BA_ "SPN" SG_ 2566822398 EngTurbo3CompressorIntakePress 1178;
BA_ "SigType" SG_ 2566822398 EngTurbo3CompressorIntakePress 1;
BA_ "SPN" SG_ 2566822398 EngTurbo2CompressorIntakePress 1177;
BA_ "SigType" SG_ 2566822398 EngTurbo2CompressorIntakePress 1;
BA_ "SPN" SG_ 2566822398 EngTurbo1CompressorIntakePress 1176;
BA_ "SigType" SG_ 2566822398 EngTurbo1CompressorIntakePress 1;
BA_ "SPN" SG_ 2566822654 EngTurbo4CompressorIntakeTemp 1175;
BA_ "SigType" SG_ 2566822654 EngTurbo4CompressorIntakeTemp 1;
BA_ "SPN" SG_ 2566822654 EngTurbo3CompressorIntakeTemp 1174;
BA_ "SigType" SG_ 2566822654 EngTurbo3CompressorIntakeTemp 1;
BA_ "SPN" SG_ 2566822654 EngTurbo2CompressorIntakeTemp 1173;
BA_ "SigType" SG_ 2566822654 EngTurbo2CompressorIntakeTemp 1;
BA_ "SPN" SG_ 2566822654 EngTurbo1CompressorIntakeTemp 1172;
BA_ "SigType" SG_ 2566822654 EngTurbo1CompressorIntakeTemp 1;
BA_ "SPN" SG_ 2633931774 EngTurbo4Speed 1171;
BA_ "SigType" SG_ 2633931774 EngTurbo4Speed 1;
BA_ "SPN" SG_ 2633931774 EngTurbo3Speed 1170;
BA_ "SigType" SG_ 2633931774 EngTurbo3Speed 1;
BA_ "SPN" SG_ 2633931774 EngTurbo2Speed 1169;
BA_ "SigType" SG_ 2633931774 EngTurbo2Speed 1;
BA_ "SPN" SG_ 2633931774 EngTurboLubeOilPress2 1168;
BA_ "SigType" SG_ 2633931774 EngTurboLubeOilPress2 1;
BA_ "SPN" SG_ 2566802430 TransTorqueLimit 1845;
BA_ "SigType" SG_ 2566802430 TransTorqueLimit 1;
BA_ "SPN" SG_ 2566841086 TransGearRatio 581;
BA_ "SigType" SG_ 2566841086 TransGearRatio 1;
BA_ "SPN" SG_ 2566841086 NumberOfForwardGearRatios 957;
BA_ "SigType" SG_ 2566841086 NumberOfForwardGearRatios 1;
BA_ "SPN" SG_ 2566841086 NumberOfReverseGearRatios 958;
BA_ "SigType" SG_ 2566841086 NumberOfReverseGearRatios 1;
VAL_ 2566759678 EnggmntSttusTransInputShaftPTO1 0 "DriveNotEngaged" 1 "DriveIsEngaged" 2 "Error" 3 "NotAvailable";
VAL_ 2566759678 EnggmntSttusTransInputShaftPTO2 0 "DriveNotEngaged" 1 "DriveIsEngaged" 2 "Error" 3 "NotAvailable";
VAL_ 2566759678 EnggmntSttusTransOutputShaftPTO 0 "DriveNotEngaged" 1 "DriveIsEngaged" 2 "Error" 3 "NotAvailable";
VAL_ 2566759678 EnggmntSttsTrnsfrCsOtptShaftPTO 0 "DriveNotEngaged" 1 "DriveIsEngaged" 2 "Error" 3 "NotAvailable";
VAL_ 2566759678 EnggmntCnsntTransInputShaftPTO1 0 "CnsntNtGvnPTODrvShldNtBeEngaged" 1 "CnsentGivenPTODriveMayBeEngaged" 2 "Error" 3 "NotAvailable";
VAL_ 2566759678 EnggmntCnsntTransInputShaftPTO2 0 "CnsntNtGvnPTODrvShldNtBeEngaged" 1 "CnsentGivenPTODriveMayBeEngaged" 2 "Error" 3 "NotAvailable";
VAL_ 2566759678 EnggmntCnsntTransOutputShaftPTO 0 "CnsntNtGvnPTODrvShldNtBeEngaged" 1 "CnsentGivenPTODriveMayBeEngaged" 2 "Error" 3 "NotAvailable";
VAL_ 2566759678 EnggmntCnsntTrnsfrCsOtptShftPTO 0 "CnsntNtGvnPTODrvShldNtBeEngaged" 1 "CnsentGivenPTODriveMayBeEngaged" 2 "Error" 3 "NotAvailable";
VAL_ 2566759678 EnableSwitchTransInputShaftPTO1 0 "EnblSwtchOffPTOOprtonNotDesired" 1 "EnblSwtchOffPTOOperationDesired" 2 "Error" 3 "NotAvailable";
VAL_ 2566759678 EnableSwitchTransInputShaftPTO2 0 "EnblSwtchOffPTOOprtonNotDesired" 1 "EnblSwtchOffPTOOperationDesired" 2 "Error" 3 "NotAvailable";
VAL_ 2566759678 EnableSwitchTransOutputShaftPTO 0 "EnblSwtchOffPTOOprtonNotDesired" 1 "EnblSwtchOffPTOOperationDesired" 2 "Error" 3 "NotAvailable";
VAL_ 2566759678 EnblSwtchTrnsfrCsOutputShaftPTO 0 "EnblSwtchOffPTOOprtonNotDesired" 1 "EnblSwtchOffPTOOperationDesired" 2 "Error" 3 "NotAvailable";
VAL_ 2566759678 EnggmntSttsPTOEngAccssoryDrive2 0 "DriveNotEngaged" 1 "DriveEngaged" 2 "Error" 3 "NotAvailable";
VAL_ 2566759678 EnggmntSttsPTOEngAccssoryDrive1 0 "DriveNotEngaged" 1 "DriveEngaged" 2 "Error" 3 "NotAvailable";
VAL_ 2566759678 EnggmntCnsntPTOEngAccssryDrive2 0 "CnsntNtGvnPTODrvMayNotBeEngaged" 1 "CnsentGivenPTODriveMayBeEngaged" 2 "Error" 3 "NotAvailable";
VAL_ 2566759678 EnggmntCnsntPTOEngAccssryDrive1 0 "CnsntNtGvnPTODrvMayNotBeEngaged" 1 "CnsentGivenPTODriveMayBeEngaged" 2 "Error" 3 "NotAvailable";
VAL_ 2566759678 EngagementStatusPTOEngFlywheel 0 "DriveNotEngaged" 1 "DriveEngaged" 2 "Error" 3 "NotAvailable";
VAL_ 2566759678 EngagementConsentPTOEngFlywheel 0 "CnsntNtGvnPTODrvMayNotBeEngaged" 1 "CnsentGivenPTODriveMayBeEngaged" 2 "Error" 3 "NotAvailable";
VAL_ 2566759678 EnblSwitchPTOEngAccessoryDrive2 0 "EnblSwtchOffPTOOprtonNotDesired" 1 "EnblSwitchOnPTOOperationDesired" 2 "Error" 3 "NotAvailable";
VAL_ 2566759678 EnblSwitchPTOEngAccessoryDrive1 0 "EnblSwtchOffPTOOprtonNotDesired" 1 "EnblSwitchOnPTOOperationDesired" 2 "Error" 3 "NotAvailable";
VAL_ 2566759678 EnableSwitchPTOEngFlywheel 0 "EnblSwtchOffPTOOprtonNotDesired" 1 "EnblSwitchOnPTOOperationDesired" 2 "Error" 3 "NotAvailable";
VAL_ 2566759678 AtLeastOnePTOEngaged 0 "NoPTODriveIsEngaged" 1 "AtLeastOnePTODriveIsEngaged" 2 "Error" 3 "NotAvailable";
VAL_ 2432541694 EngTrbCmprssrBypssActtr1TmpStts 0 "HighMostSevere" 1 "HighLeastSevere" 2 "InRange" 3 "LowLeastSevere" 4 "LowMostSevere" 5 "NotDefined" 6 "Error" 7 "NotAvailable";
VAL_ 2432541694 EngTrbCmprssrBypassActuator2Cmd 4 "RprsntsFllyOpnTypcllyTrbCmprssr";
VAL_ 2432541694 EngTrbCmprssrBypassActuator1Pos 4 "RprsntsBypssFllyOpnTypcllyCmprs";
VAL_ 2432541694 EngTrbCmprssrBypassActuator1Cmd 4 "RprsntsFllyOpnTypcllyTrbCmprssr";
VAL_ 2566759934 EnableStatusOfDoor10 0 "doorDisabled" 1 "doorEnabled" 2 "error" 3 "notAvailable";
VAL_ 2566759934 OpenStatusOfDoor10 0 "doorClosed" 1 "doorOpened" 2 "error" 3 "notAvailable";
VAL_ 2566759934 LockStatusOfDoor10 0 "unlocked" 1 "locked" 2 "error" 3 "notAvailable";
VAL_ 2566759934 EnableStatusOfDoor9 0 "doorDisabled" 1 "doorEnabled" 2 "error" 3 "notAvailable";
VAL_ 2566759934 OpenStatusOfDoor9 0 "doorClosed" 1 "doorOpened" 2 "error" 3 "notAvailable";
VAL_ 2566759934 LockStatusOfDoor9 0 "unlocked" 1 "locked" 2 "error" 3 "notAvailable";
VAL_ 2566759934 EnableStatusOfDoor8 0 "doorDisabled" 1 "doorEnabled" 2 "error" 3 "notAvailable";
VAL_ 2566759934 OpenStatusOfDoor8 0 "doorClosed" 1 "doorOpened" 2 "error" 3 "notAvailable";
VAL_ 2566759934 LockStatusOfDoor8 0 "unlocked" 1 "locked" 2 "error" 3 "notAvailable";
VAL_ 2566759934 EnableStatusOfDoor7 0 "doorDisabled" 1 "doorEnabled" 2 "error" 3 "notAvailable";
VAL_ 2566759934 OpenStatusOfDoor7 0 "doorClosed" 1 "doorOpened" 2 "error" 3 "notAvailable";
VAL_ 2566759934 LockStatusOfDoor7 0 "unlocked" 1 "locked" 2 "error" 3 "notAvailable";
VAL_ 2566759934 EnableStatusOfDoor6 0 "doorDisabled" 1 "doorEnabled" 2 "error" 3 "notAvailable";
VAL_ 2566759934 OpenStatusOfDoor6 0 "doorClosed" 1 "doorOpened" 2 "error" 3 "notAvailable";
VAL_ 2566759934 LockStatusOfDoor6 0 "unlocked" 1 "locked" 2 "error" 3 "notAvailable";
VAL_ 2566759934 EnableStatusOfDoor5 0 "doorDisabled" 1 "doorEnabled" 2 "error" 3 "notAvailable";
VAL_ 2566759934 OpenStatusOfDoor5 0 "doorClosed" 1 "doorOpened" 2 "error" 3 "notAvailable";
VAL_ 2566759934 LockStatusOfDoor5 0 "unlocked" 1 "locked" 2 "error" 3 "notAvailable";
VAL_ 2566759934 EnableStatusOfDoor4 0 "doorDisabled" 1 "doorEnabled" 2 "error" 3 "notAvailable";
VAL_ 2566759934 OpenStatusOfDoor4 0 "doorClosed" 1 "doorOpened" 2 "error" 3 "notAvailable";
VAL_ 2566759934 LockStatusOfDoor4 0 "unlocked" 1 "locked" 2 "error" 3 "notAvailable";
VAL_ 2566759934 EnableStatusOfDoor3 0 "doorDisabled" 1 "doorEnabled" 2 "error" 3 "notAvailable";
VAL_ 2566759934 OpenStatusOfDoor3 0 "doorClosed" 1 "doorOpened" 2 "error" 3 "notAvailable";
VAL_ 2566759934 LockStatusOfDoor3 0 "unlocked" 1 "locked" 2 "error" 3 "notAvailable";
VAL_ 2566759934 EnableStatusOfDoor2 0 "doorDisabled" 1 "doorEnabled" 2 "error" 3 "notAvailable";
VAL_ 2566759934 OpenStatusOfDoor2 0 "doorClosed" 1 "doorOpened" 2 "error" 3 "notAvailable";
VAL_ 2566759934 LockStatusOfDoor2 0 "unlocked" 1 "locked" 2 "error" 3 "notAvailable";
VAL_ 2566759934 EnableStatusOfDoor1 0 "doorDisabled" 1 "doorEnabled" 2 "error" 3 "notAvailable";
VAL_ 2566759934 OpenStatusOfDoor1 0 "doorClosed" 1 "doorOpened" 2 "error" 3 "notAvailable";
VAL_ 2566759934 LockStatusOfDoor1 0 "unlocked" 1 "locked" 2 "error" 3 "notAvailable";
VAL_ 2566757374 Aftrtrtmnt1SCRCtlystReagentType 0 "CtlystRgntIsUrCncntrtionTooHigh" 1 "CtlystRgntIsUrCncntrationTooLow" 2 "CatalystReagentIsDiesel" 3 "CatalystReagentIsProperMixture" 5 "to1100ReservedForSAEAssignment" 13 "NtAblTDtrmneCatalystReagentType" 14 "ErrrDtctdWthUrRgntTypeDetection" 15 "NotAvailable";
VAL_ 2364544766 EngCyl9CombustionStatus 0 "NoCombustion" 1 "CombustionExists" 2 "Error" 3 "NotAvailable";
VAL_ 2364544766 EngCyl8CombustionStatus 0 "NoCombustion" 1 "CombustionExists" 2 "Error" 3 "NotAvailable";
VAL_ 2364544766 EngCyl7CombustionStatus 0 "NoCombustion" 1 "CombustionExists" 2 "Error" 3 "NotAvailable";
VAL_ 2364544766 EngCyl6CombustionStatus 0 "NoCombustion" 1 "CombustionExists" 2 "Error" 3 "NotAvailable";
VAL_ 2364544766 EngCyl5CombustionStatus 0 "NoCombustion" 1 "CombustionExists" 2 "Error" 3 "NotAvailable";
VAL_ 2364544766 EngCyl4CombustionStatus 0 "NoCombustion" 1 "CombustionExists" 2 "Error" 3 "NotAvailable";
VAL_ 2364544766 EngCyl3CombustionStatus 0 "NoCombustion" 1 "CombustionExists" 2 "Error" 3 "NotAvailable";
VAL_ 2364544766 EngCyl2CombustionStatus 0 "NoCombustion" 1 "CombustionExists" 2 "Error" 3 "NotAvailable";
VAL_ 2364544766 EngCyl24CombustionStatus 0 "NoCombustion" 1 "CombustionExists" 2 "Error" 3 "NotAvailable";
VAL_ 2364544766 EngCyl23CombustionStatus 0 "NoCombustion" 1 "CombustionExists" 2 "Error" 3 "NotAvailable";
VAL_ 2364544766 EngCyl22CombustionStatus 0 "NoCombustion" 1 "CombustionExists" 2 "Error" 3 "NotAvailable";
VAL_ 2364544766 EngCyl21CombustionStatus 0 "NoCombustion" 1 "CombustionExists" 2 "Error" 3 "NotAvailable";
VAL_ 2364544766 EngCyl20CombustionStatus 0 "NoCombustion" 1 "CombustionExists" 2 "Error" 3 "NotAvailable";
VAL_ 2364544766 EngCyl1CombustionStatus 0 "NoCombustion" 1 "CombustionExists" 2 "Error" 3 "NotAvailable";
VAL_ 2364544766 EngCyl19CombustionStatus 0 "NoCombustion" 1 "CombustionExists" 2 "Error" 3 "NotAvailable";
VAL_ 2364544766 EngCyl18CombustionStatus 0 "NoCombustion" 1 "CombustionExists" 2 "Error" 3 "NotAvailable";
VAL_ 2364544766 EngCyl17CombustionStatus 0 "NoCombustion" 1 "CombustionExists" 2 "Error" 3 "NotAvailable";
VAL_ 2364544766 EngCyl16CombustionStatus 0 "NoCombustion" 1 "CombustionExists" 2 "Error" 3 "NotAvailable";
VAL_ 2364544766 EngCyl15CombustionStatus 0 "NoCombustion" 1 "CombustionExists" 2 "Error" 3 "NotAvailable";
VAL_ 2364544766 EngCyl14CombustionStatus 0 "NoCombustion" 1 "CombustionExists" 2 "Error" 3 "NotAvailable";
VAL_ 2364544766 EngCyl13CombustionStatus 0 "NoCombustion" 1 "CombustionExists" 2 "Error" 3 "NotAvailable";
VAL_ 2364544766 EngCyl12CombustionStatus 0 "NoCombustion" 1 "CombustionExists" 2 "Error" 3 "NotAvailable";
VAL_ 2364544766 EngCyl11CombustionStatus 0 "NoCombustion" 1 "CombustionExists" 2 "Error" 3 "NotAvailable";
VAL_ 2364544766 EngCyl10CombustionStatus 0 "NoCombustion" 1 "CombustionExists" 2 "Error" 3 "NotAvailable";
VAL_ 2364544254 RlativeBladeHeightFigureOfMerit 0 "RltvBldHghtFllyFnctnlDtIsWthnSn" 1 "RltvBldHghtDgrddDtIsSspctDTEnvr" 2 "RelativeBladeHeightFailed" 3 "RelativeBladeHeightNotAvailable";
VAL_ 2364544254 BladeRotationAngleFigureOfMerit 0 "BldRttnAnglFllyFnctnlDtIsWthnSn" 1 "BldRttnAnglDgrddDtIsSspctDTEnvr" 2 "BldRttnAnglFldRllSnsrFldTOprtCr" 3 "BladeRotationAngleNotAvailable";
VAL_ 2349137662 XBRCtrlMode 0 "OverrideDisabled" 1 "AccelerationControlWithAddMode" 2 "AccelerationControlWithMaxMode" 3 "NotDefined";
VAL_ 2349137662 XBRPriority 0 "HghstPrrtyUsdFrEmrgncySttnsEgFr" 1 "HighPriorityNotDefined" 2 "MdmPrrtyUsdFrACCSystmsThsMdDsNt" 3 "LwPrrtyUsdInOvrrdDsbldXBRCtrlMd";
VAL_ 2349137662 XBREBIMode 0 "NEndrnceBrakeIntegrationAllowed" 1 "OnlyEnduranceBrakesAllowed" 2 "EndranceBrakeIntegrationAllowed" 3 "NotDefined";
VAL_ 2349137662 XBRUrgency 0 "SttnNtCrtclLwRtrdrDynmcsArTlrtd" 4 "LwRtrdrDynmcsShllBFllyCmpnstdBy";
VAL_ 2566848510 WaterInFuelIndicator 0 "No" 1 "Yes" 2 "Error" 3 "NotAvailable";
VAL_ 2566843134 AxleLocation 0 "Axle0_Position0" 16 "Axle1_Position0" 32 "Axle2_Position0" 48 "Axle3_Position0";
VAL_ 2566809854 WinchOilPressSwitch 0 "NOTOKOilPressIsTooLow" 1 "OKOilPressIsAboveMin" 2 "ErrrSwtchStteCannotBeDetermined" 3 "NotAvailable";
VAL_ 2566809854 HydOilFilterRestrictionSwitch 0 "NoRestriction" 1 "RestrictionExistsOnOilFilter" 2 "Error" 3 "NotAvailable";
VAL_ 2565868030 SteerWheelAngleSensorType 0 "RelativeMeasuringPrinciple" 1 "AbsMeasuringPrinciple" 2 "Reserved" 3 "NotAvailable";
VAL_ 2566803454 YCBrakeCtrlActive 0 "YCBrakeCtrlPassiveButInstalled" 1 "YCBrakeCtrlActive" 2 "Reserved" 3 "DontCare_TakeNoAction";
VAL_ 2566803454 YCEngCtrlActive 0 "YCEngCtrlPassiveButInstalled" 1 "YCEngCtrlActive" 2 "Reserved" 3 "DontCare_TakeNoAction";
VAL_ 2566803454 ROPBrakeCtrlActive 0 "ROPBrakeCtrlPassiveButInstalled" 1 "ROPBrakeCtrlActive" 2 "Reserved" 3 "DontCare_TakeNoAction";
VAL_ 2566803454 ROPEngCtrlActive 0 "ROPEngCtrlPassiveButInstalled" 1 "ROPEngCtrlActive" 2 "Reserved" 3 "DontCare_TakeNoAction";
VAL_ 2566803454 VDCBrakeLightRq 0 "TurnBrakeLightNotOn" 1 "TurnBrakeLightOn" 2 "Reserved" 3 "DontCare_TakeNoAction";
VAL_ 2566803454 VDCFullyOperational 0 "NotFullyOperational" 1 "FullyOperational" 2 "Reserved" 3 "DontCare_TakeNoAction";
VAL_ 2566803454 VDCInformationSignal 0 "Off" 1 "On" 2 "Reserved" 3 "DontCare_TakeNoAction";
VAL_ 2348875518 MessageCounter 8 "Reserved" 9 "Reserved" 10 "Reserved" 11 "Reserved" 12 "Reserved" 13 "Reserved" 14 "Reserved" 15 "Not Available";
VAL_ 2348875518 ControlPurpose 0 "AcceleratorPedal" 1 "CruiseControl" 2 "PTOGovernor" 3 "RoadSpeedGovernor" 4 "EngineProtection" 5 "TemporaryPowerTrainControl";
VAL_ 2348875518 TransmissionRate 0 "1000ms" 1 "750ms" 2 "500ms" 3 "250ms" 4 "100ms" 5 "50ms" 6 "25ms" 7 "UseStandardRate";
VAL_ 2348875518 OverrideCtrlModePriority 0 "HghstPrrtyUsdFrSttnsThtRqrImmdt" 1 "HighPriority" 2 "MdmPrrtyUsdFrPwrtrnCtrlOprtnsWh" 3 "LowPriority";
VAL_ 2348875518 EngRqedSpeedCtrlConditions 0 "ThsSpdGvrnrGnSlctnIsAdjstdTPrvd" 1 "StbltyOptmzdFrDrvlnDsnggdAndNnl" 2 "ThsCtrlCndtnHsBnOptmzdTMnmzRpmO" 3 "StbltyOptmzdFrDrvlnEnggdAnd_OrI";
VAL_ 2348875518 EngOverrideCtrlMode 0 "OvrrdDsbldDsblAnyExstngCtrlCmdd" 1 "SpdCtrlGvrnSpdTInclddDsrdSpdVle" 2 "TrqCtrlCntrlTrqTInclddDsrdTrqVl" 3 "Spd_TrqLmtCtrlLmtSpdAnd_OrTrqBs";
VAL_ 2348875518 MessageChecksum 15 "Not Available";
VAL_ 2348875518 EngineRequestedTorqueHiRes 8 "Not Available" 9 "Not Available" 10 "Not Available" 11 "Not Available" 12 "Not Available" 13 "Not Available" 14 "Not Available" 15 "Not Available";
VAL_ 2566766846 TransitRunStatus 0 "Off" 1 "On" 2 "ErrorCondition" 3 "NotAvailable";
VAL_ 2566766846 VehicleUseStatus 0 "NormalUse" 1 "UnauthorizedUse" 2 "ErrorCondition" 3 "NotAvailable";
VAL_ 2566766846 SilentAlarmStatus 0 "Off" 1 "On" 2 "ErrorCondition" 3 "NotAvailable";
VAL_ 2566766846 TypeOfPassengerCount 0 "AbsPassengerCount" 1 "BoardingPassenger" 2 "Exiting Passenger" 3 "Boarding Passenger (second passenger stream)" 4 "Exiting Passenger (second passenger stream)";
VAL_ 2566765310 FareboxAlarmIdentifier 0 "VoltageDropout" 1 "VoltageRestored" 2 "ProbeStarted" 3 "ProbeCompleted" 4 "CashboxRemoved" 5 "CashboxRestored" 6 "CashboxDoorTimeout" 7 "CshbxOpndInSrvcCnsdrdAnAlrmCndt" 8 "InsufficientFareAccepted" 9 "Coinbox75Full" 10 "CoinboxFull" 11 "CurrencyBox75Full" 12 "CurrencyBoxLessThan75Full" 13 "CurrencyBoxFull" 14 "Card_PassBox75Full" 15 "Card_PassBoxLessThan75Full" 16 "Card_PassBoxFull" 17 "CoinDejamOperated" 18 "FareboxSetInManualBypass" 19 "FareboxResetToAutomaticMode" 20 "Pass_TransferJam" 21 "Pass_TransferJamCleared" 22 "PaperCurrencyJam" 23 "PaperCurrencyJamCleared" 24 "MntnncAccssInSrvcCnsdrdAnAlrmCn" 25 "MaintenanceAccessOutOfService" 26 "1100000ReservedToBeAssigned" 97 "1111111AgencyDefined";
VAL_ 2566765310 FareboxEmergencyStatus 0 "NonemergencyCondition" 1 "EmergencyCondition" 2 "ErrorCondition" 3 "NotAvailable";
VAL_ 2566765566 TransferType 0 "North" 1 "South" 2 "East" 3 "West" 4 "In" 5 "Out" 6 "11111AgencyDefined";
VAL_ 2566765566 TypeOfService 0 "LocalService" 1 "ExpressService" 2 "111AgencyDefined";
VAL_ 2566765566 PaymentDetails 0 "NotAnUpgrade" 1 "Cash" 2 "Token" 3 "Ticket" 4 "Pass" 5 "Card" 6 "1010ReservedForAssignment" 11 "1111AgencyDefined";
VAL_ 2566765566 TypeOfFare 0 "Cash_NoDetail" 1 "TokenA" 2 "TokenB" 3 "TicketA" 4 "TicketB" 5 "PassA" 6 "PassB" 7 "1010ReservedForAssignment" 11 "1111AgencyDefined";
VAL_ 2566765566 TransactionType 0 "Cash" 1 "Token" 2 "Ticket" 3 "Pass" 4 "Card" 5 "Permit" 6 "Transfer" 7 "Free" 8 "1011ReservedForAssignment" 12 "1111AgencyDefined";
VAL_ 2566765822 DriversFareboxSecurityCode 0 "Farebox is in reporting status" 1 "SecurityCode";
VAL_ 2566765822 FarePresets 0 "to00001111AgencyDefined" 16 "to11111111ReservedForAssignment";
VAL_ 2566765822 TripDirection 0 "North" 1 "South" 2 "East" 3 "West" 4 "In" 5 "Out" 6 "1111AgencyDefined";
VAL_ 2566765822 TripStatus 1 "TripStart" 2 "TripEnd" 5 "LayoverStart" 6 "LayoverEnd" 7 "Undefined";
VAL_ 2566765822 FareboxServiceStatus 0 "FareboxOutOfService" 1 "FareboxInService" 2 "ErrorCondition" 3 "NotAvailable";
VAL_ 2566766078 StrobeActivationCtrlStatus 0 "DeactivateStrobe" 1 "ActivateStrobe" 2 "ErrorCondition" 3 "NotAvailable";
VAL_ 2566766078 TransitDoorEnable 0 "IgnoreTransitDoorStatus" 1 "TrnstDrSttsWllOvrrdStrbActvtion" 2 "ErrorCondition" 3 "NotAvailable";
VAL_ 2566766078 PriorityOfRespSentByEmitter 0 "Reserved" 1 "LowPriority" 2 "ProbePriority" 3 "HighPriority" 4 "to1000Reserved" 9 "PrrtySetByHardwareToLowPriority" 10 "PrrtyStByHrdwareToProbePriority" 11 "PrrtyStByHardwareToHighPriority" 12 "to1101Reserved" 14 "ErrorCondition" 15 "NotAvailable";
VAL_ 2566766078 IntersectionPreemptionRq_Resp 0 "MessageIsARqDirectedToEmitter" 1 "MessageIsARespFromEmitter" 2 "ErrorCondition" 3 "NotAvailable";
VAL_ 2566766078 TransitRouteIDUsage 0 "TrnstRtIDNtUsdFrInterleavedData" 1 "TrnstRtIDUsedForInterleavedData" 2 "ErrorCondition" 3 "NotAvailable";
VAL_ 2566766078 RangeCodeEnable 0 "RngCdeNotUsedForInterleavedData" 1 "RangeCodeUsedForInterleavedData" 2 "ErrorCondition" 3 "NotAvailable";
VAL_ 2633922814 PCUSupplySolenoidStatus 0 "Off" 1 "On" 2 "Error" 3 "NotAvailable";
VAL_ 2633922814 PCUCtrlSolenoidStatus 0 "Off" 1 "On" 2 "Error" 3 "NotAvailable";
VAL_ 2633922814 PCUDeflateSolenoidStatus 0 "Off" 1 "On" 2 "Error" 3 "NotAvailable";
VAL_ 2633922814 TirePressSupplySwitchStatus 0 "Off" 1 "On" 2 "Error" 3 "NotAvailable";
VAL_ 2633922814 PCUSteerSolenoidStatus 0 "Off" 1 "On" 2 "Error" 3 "NotAvailable";
VAL_ 2633922814 PCUDriveSolenoidStatus 0 "Off" 1 "On" 2 "Error" 3 "NotAvailable";
VAL_ 2633922814 DriveChannelMode 0 "Maintain" 1 "Inflate" 2 "Deflate" 3 "Confirm" 4 "InfltWtSystmWllInfltWhnCndtnsAl" 5 "DfltWtSystmWllDfltWhnCndtnsAllw" 6 "PressCheck" 7 "1101Reserved" 14 "ErrorCondition" 15 "NotAvailable";
VAL_ 2633922814 Trailer_TagChannelMode 0 "Maintain" 1 "Inflate" 2 "Deflate" 3 "Confirm" 4 "InfltWtSystmWllInfltWhnCndtnsAl" 5 "DfltWtSystmWllDfltWhnCndtnsAllw" 6 "PressCheck" 7 "1101Reserved" 14 "ErrorCondition" 15 "NotAvailable";
VAL_ 2633922814 SteerChannelMode 0 "Maintain" 1 "Inflate" 2 "Deflate" 3 "Confirm" 4 "InfltWtSystmWllInfltWhnCndtnsAl" 5 "DfltWtSystmWllDfltWhnCndtnsAllw" 6 "PressCheck" 7 "1101Reserved" 14 "ErrorCondition" 15 "NotAvailable";
VAL_ 2633922814 PCUTrailerTagPushSolenoidStatus 0 "Off" 1 "On" 2 "Error" 3 "NotAvailable";
VAL_ 2566845694 TirePressThresholdDetection_13 0 "ExtrmOvrPrssTrPrssrIsAtALvlWhrT" 1 "OvrPrssTrPrssrIsHghrThnThPrssrD" 2 "NWrnngPrssTrPrssrIsWthnThThrshl" 3 "UndrPrssTrPrssrIsLwrThnThPrssrD" 4 "ExtrmUndrPrssTrPrssrIsAtALvlWhr" 5 "NotDefined" 6 "ErrorIndicator" 7 "NotAvailable";
VAL_ 2566845694 TirePressThresholdDetection_12 0 "ExtrmOvrPrssTrPrssrIsAtALvlWhrT" 1 "OvrPrssTrPrssrIsHghrThnThPrssrD" 2 "NWrnngPrssTrPrssrIsWthnThThrshl" 3 "UndrPrssTrPrssrIsLwrThnThPrssrD" 4 "ExtrmUndrPrssTrPrssrIsAtALvlWhr" 5 "NotDefined" 6 "ErrorIndicator" 7 "NotAvailable";
VAL_ 2566845694 TirePressThresholdDetection_11 0 "ExtrmOvrPrssTrPrssrIsAtALvlWhrT" 1 "OvrPrssTrPrssrIsHghrThnThPrssrD" 2 "NWrnngPrssTrPrssrIsWthnThThrshl" 3 "UndrPrssTrPrssrIsLwrThnThPrssrD" 4 "ExtrmUndrPrssTrPrssrIsAtALvlWhr" 5 "NotDefined" 6 "ErrorIndicator" 7 "NotAvailable";
VAL_ 2566845694 TirePressThresholdDetection_10 0 "ExtrmOvrPrssTrPrssrIsAtALvlWhrT" 1 "OvrPrssTrPrssrIsHghrThnThPrssrD" 2 "NWrnngPrssTrPrssrIsWthnThThrshl" 3 "UndrPrssTrPrssrIsLwrThnThPrssrD" 4 "ExtrmUndrPrssTrPrssrIsAtALvlWhr" 5 "NotDefined" 6 "ErrorIndicator" 7 "NotAvailable";
VAL_ 2566845694 TirePressThresholdDetection_01 0 "ExtrmOvrPrssTrPrssrIsAtALvlWhrT" 1 "OvrPrssTrPrssrIsHghrThnThPrssrD" 2 "NWrnngPrssTrPrssrIsWthnThThrshl" 3 "UndrPrssTrPrssrIsLwrThnThPrssrD" 4 "ExtrmUndrPrssTrPrssrIsAtALvlWhr" 5 "NotDefined" 6 "ErrorIndicator" 7 "NotAvailable";
VAL_ 2566845694 CTIWheelSensorStatus_33 0 "Off_IsolatedFromCTIPressCtrl" 1 "On" 2 "NotDefined" 3 "NotSupported";
VAL_ 2566845694 CTIWheelSensorStatus_32 0 "Off_IsolatedFromCTIPressCtrl" 1 "On" 2 "NotDefined" 3 "NotSupported";
VAL_ 2566845694 CTIWheelSensorStatus_31 0 "Off_IsolatedFromCTIPressCtrl" 1 "On" 2 "NotDefined" 3 "NotSupported";
VAL_ 2566845694 CTIWheelSensorStatus_30 0 "Off_IsolatedFromCTIPressCtrl" 1 "On" 2 "NotDefined" 3 "NotSupported";
VAL_ 2566845694 CTIWheelSensorStatus_23 0 "Off_IsolatedFromCTIPressCtrl" 1 "On" 2 "NotDefined" 3 "NotSupported";
VAL_ 2566845694 CTIWheelSensorStatus_22 0 "Off_IsolatedFromCTIPressCtrl" 1 "On" 2 "NotDefined" 3 "NotSupported";
VAL_ 2566845694 CTIWheelSensorStatus_21 0 "Off_IsolatedFromCTIPressCtrl" 1 "On" 2 "NotDefined" 3 "NotSupported";
VAL_ 2566845694 CTIWheelSensorStatus_20 0 "Off_IsolatedFromCTIPressCtrl" 1 "On" 2 "NotDefined" 3 "NotSupported";
VAL_ 2566845694 CTIWheelSensorStatus_13 0 "Off_IsolatedFromCTIPressCtrl" 1 "On" 2 "NotDefined" 3 "NotSupported";
VAL_ 2566845694 CTIWheelSensorStatus_12 0 "Off_IsolatedFromCTIPressCtrl" 1 "On" 2 "NotDefined" 3 "NotSupported";
VAL_ 2566845694 CTIWheelSensorStatus_11 0 "Off_IsolatedFromCTIPressCtrl" 1 "On" 2 "NotDefined" 3 "NotSupported";
VAL_ 2566845694 CTIWheelSensorStatus_10 0 "Off_IsolatedFromCTIPressCtrl" 1 "On" 2 "NotDefined" 3 "NotSupported";
VAL_ 2566845694 CTIWheelSensorStatus_01 0 "Off_IsolatedFromCTIPressCtrl" 1 "On" 2 "NotDefined" 3 "NotSupported";
VAL_ 2566845694 CTIWheelEndElectricalFault_33 0 "Ok" 1 "NotDefined" 2 "Error" 3 "NotSupported";
VAL_ 2566845694 CTIWheelEndElectricalFault_32 0 "Ok" 1 "NotDefined" 2 "Error" 3 "NotSupported";
VAL_ 2566845694 CTIWheelEndElectricalFault_31 0 "Ok" 1 "NotDefined" 2 "Error" 3 "NotSupported";
VAL_ 2566845694 CTIWheelEndElectricalFault_30 0 "Ok" 1 "NotDefined" 2 "Error" 3 "NotSupported";
VAL_ 2566845694 CTIWheelEndElectricalFault_23 0 "Ok" 1 "NotDefined" 2 "Error" 3 "NotSupported";
VAL_ 2566845694 CTIWheelEndElectricalFault_22 0 "Ok" 1 "NotDefined" 2 "Error" 3 "NotSupported";
VAL_ 2566845694 CTIWheelEndElectricalFault_21 0 "Ok" 1 "NotDefined" 2 "Error" 3 "NotSupported";
VAL_ 2566845694 CTIWheelEndElectricalFault_20 0 "Ok" 1 "NotDefined" 2 "Error" 3 "NotSupported";
VAL_ 2566845694 CTIWheelEndElectricalFault_13 0 "Ok" 1 "NotDefined" 2 "Error" 3 "NotSupported";
VAL_ 2566845694 CTIWheelEndElectricalFault_12 0 "Ok" 1 "NotDefined" 2 "Error" 3 "NotSupported";
VAL_ 2566845694 CTIWheelEndElectricalFault_11 0 "Ok" 1 "NotDefined" 2 "Error" 3 "NotSupported";
VAL_ 2566845694 CTIWheelEndElectricalFault_10 0 "Ok" 1 "NotDefined" 2 "Error" 3 "NotSupported";
VAL_ 2566845694 CTIWheelEndElectricalFault_01 0 "Ok" 1 "NotDefined" 2 "Error" 3 "NotSupported";
VAL_ 2566845694 CTITireStatus_33 0 "Ok" 1 "TireLeakDetected" 2 "Error" 3 "NotSupported";
VAL_ 2566845694 CTITireStatus_32 0 "Ok" 1 "TireLeakDetected" 2 "Error" 3 "NotSupported";
VAL_ 2566845694 CTITireStatus_31 0 "Ok" 1 "TireLeakDetected" 2 "Error" 3 "NotSupported";
VAL_ 2566845694 CTITireStatus_30 0 "Ok" 1 "TireLeakDetected" 2 "Error" 3 "NotSupported";
VAL_ 2566845694 CTITireStatus_23 0 "Ok" 1 "TireLeakDetected" 2 "Error" 3 "NotSupported";
VAL_ 2566845694 CTITireStatus_22 0 "Ok" 1 "TireLeakDetected" 2 "Error" 3 "NotSupported";
VAL_ 2566845694 CTITireStatus_21 0 "Ok" 1 "TireLeakDetected" 2 "Error" 3 "NotSupported";
VAL_ 2566845694 CTITireStatus_20 0 "Ok" 1 "TireLeakDetected" 2 "Error" 3 "NotSupported";
VAL_ 2566845694 CTITireStatus_13 0 "Ok" 1 "TireLeakDetected" 2 "Error" 3 "NotSupported";
VAL_ 2566845694 CTITireStatus_12 0 "Ok" 1 "TireLeakDetected" 2 "Error" 3 "NotSupported";
VAL_ 2566845694 CTITireStatus_11 0 "Ok" 1 "TireLeakDetected" 2 "Error" 3 "NotSupported";
VAL_ 2566845694 CTITireStatus_10 0 "Ok" 1 "TireLeakDetected" 2 "Error" 3 "NotSupported";
VAL_ 2566845694 CTITireStatus_01 0 "Ok" 1 "TireLeakDetected" 2 "Error" 3 "NotSupported";
VAL_ 2566845694 TirePressThresholdDetection_33 0 "ExtrmOvrPrssTrPrssrIsAtALvlWhrT" 1 "OvrPrssTrPrssrIsHghrThnThPrssrD" 2 "NWrnngPrssTrPrssrIsWthnThThrshl" 3 "UndrPrssTrPrssrIsLwrThnThPrssrD" 4 "ExtrmUndrPrssTrPrssrIsAtALvlWhr" 5 "NotDefined" 6 "ErrorIndicator" 7 "NotAvailable";
VAL_ 2566845694 TirePressThresholdDetection_32 0 "ExtrmOvrPrssTrPrssrIsAtALvlWhrT" 1 "OvrPrssTrPrssrIsHghrThnThPrssrD" 2 "NWrnngPrssTrPrssrIsWthnThThrshl" 3 "UndrPrssTrPrssrIsLwrThnThPrssrD" 4 "ExtrmUndrPrssTrPrssrIsAtALvlWhr" 5 "NotDefined" 6 "ErrorIndicator" 7 "NotAvailable";
VAL_ 2566845694 TirePressThresholdDetection_31 0 "ExtrmOvrPrssTrPrssrIsAtALvlWhrT" 1 "OvrPrssTrPrssrIsHghrThnThPrssrD" 2 "NWrnngPrssTrPrssrIsWthnThThrshl" 3 "UndrPrssTrPrssrIsLwrThnThPrssrD" 4 "ExtrmUndrPrssTrPrssrIsAtALvlWhr" 5 "NotDefined" 6 "ErrorIndicator" 7 "NotAvailable";
VAL_ 2566845694 TirePressThresholdDetection_30 0 "ExtrmOvrPrssTrPrssrIsAtALvlWhrT" 1 "OvrPrssTrPrssrIsHghrThnThPrssrD" 2 "NWrnngPrssTrPrssrIsWthnThThrshl" 3 "UndrPrssTrPrssrIsLwrThnThPrssrD" 4 "ExtrmUndrPrssTrPrssrIsAtALvlWhr" 5 "NotDefined" 6 "ErrorIndicator" 7 "NotAvailable";
VAL_ 2566845694 TirePressThresholdDetection_23 0 "ExtrmOvrPrssTrPrssrIsAtALvlWhrT" 1 "OvrPrssTrPrssrIsHghrThnThPrssrD" 2 "NWrnngPrssTrPrssrIsWthnThThrshl" 3 "UndrPrssTrPrssrIsLwrThnThPrssrD" 4 "ExtrmUndrPrssTrPrssrIsAtALvlWhr" 5 "NotDefined" 6 "ErrorIndicator" 7 "NotAvailable";
VAL_ 2566845694 TirePressThresholdDetection_22 0 "ExtrmOvrPrssTrPrssrIsAtALvlWhrT" 1 "OvrPrssTrPrssrIsHghrThnThPrssrD" 2 "NWrnngPrssTrPrssrIsWthnThThrshl" 3 "UndrPrssTrPrssrIsLwrThnThPrssrD" 4 "ExtrmUndrPrssTrPrssrIsAtALvlWhr" 5 "NotDefined" 6 "ErrorIndicator" 7 "NotAvailable";
VAL_ 2566845694 TirePressThresholdDetection_21 0 "ExtrmOvrPrssTrPrssrIsAtALvlWhrT" 1 "OvrPrssTrPrssrIsHghrThnThPrssrD" 2 "NWrnngPrssTrPrssrIsWthnThThrshl" 3 "UndrPrssTrPrssrIsLwrThnThPrssrD" 4 "ExtrmUndrPrssTrPrssrIsAtALvlWhr" 5 "NotDefined" 6 "ErrorIndicator" 7 "NotAvailable";
VAL_ 2566845694 TirePressThresholdDetection_20 0 "ExtrmOvrPrssTrPrssrIsAtALvlWhrT" 1 "OvrPrssTrPrssrIsHghrThnThPrssrD" 2 "NWrnngPrssTrPrssrIsWthnThThrshl" 3 "UndrPrssTrPrssrIsLwrThnThPrssrD" 4 "ExtrmUndrPrssTrPrssrIsAtALvlWhr" 5 "NotDefined" 6 "ErrorIndicator" 7 "NotAvailable";
VAL_ 2566845694 TirePressThresholdDetection_00 0 "ExtrmOvrPrssTrPrssrIsAtALvlWhrT" 1 "OvrPrssTrPrssrIsHghrThnThPrssrD" 2 "NWrnngPrssTrPrssrIsWthnThThrshl" 3 "UndrPrssTrPrssrIsLwrThnThPrssrD" 4 "ExtrmUndrPrssTrPrssrIsAtALvlWhr" 5 "NotDefined" 6 "ErrorIndicator" 7 "NotAvailable";
VAL_ 2566845694 CTIWheelSensorStatus_00 0 "Off_IsolatedFromCTIPressCtrl" 1 "On" 2 "NotDefined" 3 "NotSupported";
VAL_ 2566845694 CTIWheelEndElectricalFault_00 0 "Ok" 1 "NotDefined" 2 "Error" 3 "NotSupported";
VAL_ 2566845694 CTITireStatus_00 0 "Ok" 1 "TireLeakDetected" 2 "Error" 3 "NotSupported";
VAL_ 2566821630 EngTrbWstgteActuator1TempStatus 0 "HighMostSevere" 1 "HighLeastSevere" 2 "InRange" 3 "LowLeastSevere" 4 "LowMostSevere" 5 "NotDefined" 6 "Error" 7 "NotAvailable";
VAL_ 2365484286 VehicleOverspeed 0 "NoOverspeed" 1 "Overspeed" 2 "Error" 3 "NotAvailable";
VAL_ 2365484286 VehicleMotion 0 "VehicleMotionNotDetected" 1 "VehicleMotionDetected" 2 "Error" 3 "NotAvailable";
VAL_ 2365484286 DirectionIndicator 0 "Forward" 1 "Reverse" 2 "Error" 3 "NotAvailable";
VAL_ 2365484286 TachographPerformance 0 "NormalPerformance" 1 "PerformanceAnalysis" 2 "Error" 3 "NotAvailable";
VAL_ 2365484286 HandlingInformation 0 "NoHandlingInformation" 1 "HandlingInformation" 2 "Error" 3 "NotAvailable";
VAL_ 2365484286 SystemEvent 0 "NoTachographEvent" 1 "TachographEvent" 2 "Error" 3 "NotAvailable";
VAL_ 2365484286 DriverCardDriver2 0 "DriverCardNotPresent" 1 "DriverCardPresent" 2 "Error" 3 "NotAvailable";
VAL_ 2365484286 Driver2TimeRelatedStates 0 "Normal_NoLimitsReached" 1 "Limit115MinBefore4H" 2 "Limit24HReached" 3 "Limit315MinBefore9H" 4 "Limit49HReached" 5 "Limit515MinBefore16H" 6 "Limit616HReached" 7 "1100Reserved" 13 "Other" 14 "Error" 15 "NotAvailable";
VAL_ 2365484286 DriverCardDriver1 0 "DriverCardNotPresent" 1 "DriverCardPresent" 2 "Error" 3 "NotAvailable";
VAL_ 2365484286 Driver1TimeRelatedStates 0 "Normal_NoLimitsReached" 1 "Limit115MinBefore4H" 2 "Limit24HReached" 3 "Limit315MinBefore9H" 4 "Limit49HReached" 5 "Limit515MinBefore16H" 6 "Limit616HReached" 7 "1100Reserved" 13 "Other" 14 "Error" 15 "NotAvailable";
VAL_ 2365484286 Driver2WorkingState 0 "RestSleeping" 1 "DriverAvailableShortBreak" 2 "WrkLdngUnldingWorkingInAnOffice" 3 "DriveBehindWheel" 4 "101Reserved" 6 "Error" 7 "NotAvailable";
VAL_ 2365484286 Driver1WorkingState 0 "RestSleeping" 1 "DriverAvailableShortBreak" 2 "WrkLdngUnldingWorkingInAnOffice" 3 "DriveBehindWheel" 4 "101Reserved" 6 "Error" 7 "NotAvailable";
